VERSION ""

NS_ :

BS_:

BU_:

BO_ 605 DAS_road: 6 XXX
 SG_ DAS_stopLineDist : 16|8@1+ (0.5,0) [0|127.5] "m" XXX
 SG_ DAS_trafficLightColor : 26|3@0+ (1,0) [0|7] "" XXX

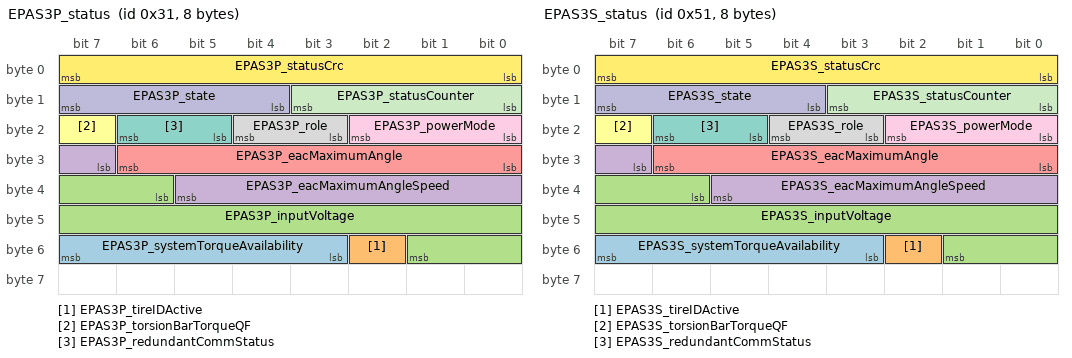
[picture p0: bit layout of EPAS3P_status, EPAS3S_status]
BO_ 49 EPAS3P_status: 8 Vector__XXX
 SG_ EPAS3P_systemTorqueAvailability : 51|5@1+ (5,0) [0|0] "" Vector__XXX
 SG_ EPAS3P_tireIDActive : 50|1@1+ (1,0) [0|0] "" Vector__XXX
 SG_ EPAS3P_inputVoltage : 38|12@1+ (0.0073,0) [0|0] "" Vector__XXX
 SG_ EPAS3P_eacMaximumAngleSpeed : 31|7@1+ (10,0) [0|0] "" Vector__XXX
 SG_ EPAS3P_eacMaximumAngle : 24|7@1+ (10,0) [0|0] "" Vector__XXX
 SG_ EPAS3P_torsionBarTorqueQF : 23|1@1+ (1,0) [0|0] "" Vector__XXX
 SG_ EPAS3P_redundantCommStatus : 21|2@1+ (1,0) [0|0] "" Vector__XXX
 SG_ EPAS3P_role : 19|2@1+ (1,0) [0|0] "" Vector__XXX
 SG_ EPAS3P_powerMode : 16|3@1+ (1,0) [0|0] "" Vector__XXX
 SG_ EPAS3P_state : 12|4@1+ (1,0) [0|0] "" Vector__XXX
 SG_ EPAS3P_statusCounter : 8|4@1+ (1,0) [0|0] "" Vector__XXX
 SG_ EPAS3P_statusCrc : 0|8@1+ (1,0) [0|0] "" Vector__XXX

BO_ 81 EPAS3S_status: 8 Vector__XXX
 SG_ EPAS3S_systemTorqueAvailability : 51|5@1+ (5,0) [0|0] "" Vector__XXX
 SG_ EPAS3S_tireIDActive : 50|1@1+ (1,0) [0|0] "" Vector__XXX
 SG_ EPAS3S_inputVoltage : 38|12@1+ (0.0073,0) [0|0] "" Vector__XXX
 SG_ EPAS3S_eacMaximumAngleSpeed : 31|7@1+ (10,0) [0|0] "" Vector__XXX
 SG_ EPAS3S_eacMaximumAngle : 24|7@1+ (10,0) [0|0] "" Vector__XXX
 SG_ EPAS3S_torsionBarTorqueQF : 23|1@1+ (1,0) [0|0] "" Vector__XXX
 SG_ EPAS3S_redundantCommStatus : 21|2@1+ (1,0) [0|0] "" Vector__XXX
 SG_ EPAS3S_role : 19|2@1+ (1,0) [0|0] "" Vector__XXX
 SG_ EPAS3S_powerMode : 16|3@1+ (1,0) [0|0] "" Vector__XXX
 SG_ EPAS3S_state : 12|4@1+ (1,0) [0|0] "" Vector__XXX
 SG_ EPAS3S_statusCounter : 8|4@1+ (1,0) [0|0] "" Vector__XXX
 SG_ EPAS3S_statusCrc : 0|8@1+ (1,0) [0|0] "" Vector__XXX

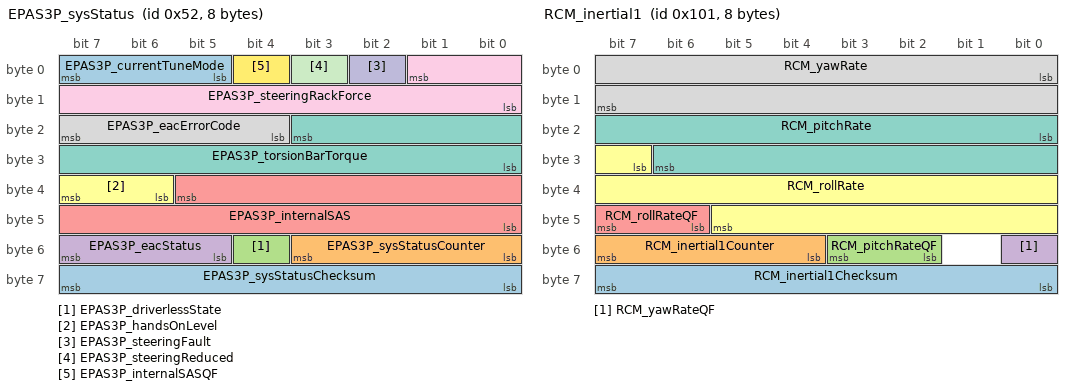
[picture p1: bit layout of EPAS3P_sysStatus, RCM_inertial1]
BO_ 82 EPAS3P_sysStatus: 8 Vector__XXX
 SG_ EPAS3P_sysStatusChecksum : 63|8@0+ (1,0) [0|0] "" Vector__XXX
 SG_ EPAS3P_sysStatusCounter : 51|4@0+ (1,0) [0|0] "" Vector__XXX
 SG_ EPAS3P_driverlessState : 52|1@0+ (1,0) [0|0] "" Vector__XXX
 SG_ EPAS3P_eacStatus : 55|3@0+ (1,0) [0|0] "" Vector__XXX
 SG_ EPAS3P_internalSAS : 37|14@0+ (0.1,-819.2) [0|0] "" Vector__XXX
 SG_ EPAS3P_handsOnLevel : 39|2@0+ (1,0) [0|0] "" Vector__XXX
 SG_ EPAS3P_torsionBarTorque : 19|12@0+ (0.01,-20.5) [0|0] "" Vector__XXX
 SG_ EPAS3P_eacErrorCode : 23|4@0+ (1,0) [0|0] "" Vector__XXX
 SG_ EPAS3P_steeringRackForce : 1|10@0+ (50,-25575) [0|0] "" Vector__XXX
 SG_ EPAS3P_steeringFault : 2|1@0+ (1,0) [0|0] "" Vector__XXX
 SG_ EPAS3P_steeringReduced : 3|1@0+ (1,0) [0|0] "" Vector__XXX
 SG_ EPAS3P_internalSASQF : 4|1@0+ (1,0) [0|0] "" Vector__XXX
 SG_ EPAS3P_currentTuneMode : 7|3@0+ (1,0) [0|0] "" Vector__XXX

BO_ 257 RCM_inertial1: 8 Vector__XXX
 SG_ RCM_inertial1Checksum : 56|8@1+ (1,0) [0|0] "" Vector__XXX
 SG_ RCM_inertial1Counter : 52|4@1+ (1,0) [0|0] "" Vector__XXX
 SG_ RCM_pitchRateQF : 50|2@1+ (1,0) [0|0] "" Vector__XXX
 SG_ RCM_yawRateQF : 48|1@1+ (1,0) [0|0] "" Vector__XXX
 SG_ RCM_rollRateQF : 46|2@1+ (1,0) [0|0] "" Vector__XXX
 SG_ RCM_rollRate : 31|15@1- (0.00025,0) [0|0] "" Vector__XXX
 SG_ RCM_pitchRate : 16|15@1- (0.00025,0) [0|0] "" Vector__XXX
 SG_ RCM_yawRate : 0|16@1- (0.0001,0) [0|0] "" Vector__XXX

BO_ 258 VCLEFT_doorStatus: 8 VEH
 SG_ VCLEFT_frontHandlePulledPersist : 62|1@1+ (1,0) [0|0] ""  X
 SG_ VCLEFT_mirrorDipped : 61|1@1+ (1,0) [0|0] ""  X
 SG_ VCLEFT_mirrorHeatState : 58|3@1+ (1,0) [0|0] ""  X
 SG_ VCLEFT_mirrorRecallState : 55|3@1+ (1,0) [0|0] ""  X
 SG_ VCLEFT_mirrorFoldState : 52|3@1+ (1,0) [0|0] ""  X
 SG_ VCLEFT_mirrorState : 49|3@1+ (1,0) [0|0] ""  X
 SG_ VCLEFT_mirrorTiltYPosition : 41|8@1+ (0.02,0) [0|0] "V"  X
 SG_ VCLEFT_mirrorTiltXPosition : 33|8@1+ (0.02,0) [0|0] "V"  X
 SG_ VCLEFT_rearIntSwitchPressed : 32|1@1+ (1,0) [0|0] ""  X
 SG_ VCLEFT_frontIntSwitchPressed : 31|1@1+ (1,0) [0|0] ""  X
 SG_ VCLEFT_rearHandlePWM : 24|7@1+ (1,0) [0|0] "%"  X
 SG_ VCLEFT_frontHandlePWM : 16|7@1+ (1,0) [0|0] "%"  X
 SG_ VCLEFT_rearRelActuatorSwitch : 13|1@1+ (1,0) [0|0] ""  X
 SG_ VCLEFT_frontRelActuatorSwitch : 12|1@1+ (1,0) [0|0] ""  X
 SG_ VCLEFT_rearHandlePulled : 11|1@1+ (1,0) [0|0] ""  X
 SG_ VCLEFT_frontHandlePulled : 10|1@1+ (1,0) [0|0] ""  X
 SG_ VCLEFT_rearLatchSwitch : 9|1@1+ (1,0) [0|0] ""  X
 SG_ VCLEFT_frontLatchSwitch : 8|1@1+ (1,0) [0|0] ""  X
 SG_ VCLEFT_rearLatchStatus : 4|4@1+ (1,0) [0|0] ""  X
 SG_ VCLEFT_frontLatchStatus : 0|4@1+ (1,0) [0|0] ""  X

BO_ 259 VCRIGHT_doorStatus: 8 VEH
 SG_ VCRIGHT_mirrorDipped : 63|1@1+ (1,0) [0|0] ""  X
 SG_ VCRIGHT_mirrorRecallState : 60|3@1+ (1,0) [0|0] ""  X
 SG_ VCRIGHT_trunkLatchStatus : 56|4@1+ (1,0) [0|0] ""  X
 SG_ VCRIGHT_mirrorFoldState : 52|3@1+ (1,0) [0|0] ""  X
 SG_ VCRIGHT_mirrorState : 49|3@1+ (1,0) [0|0] ""  X
 SG_ VCRIGHT_mirrorTiltYPosition : 41|8@1+ (0.02,0) [0|0] "V"  X
 SG_ VCRIGHT_mirrorTiltXPosition : 33|8@1+ (0.02,0) [0|0] "V"  X
 SG_ VCRIGHT_rearIntSwitchPressed : 32|1@1+ (1,0) [0|0] ""  X
 SG_ VCRIGHT_frontIntSwitchPressed : 31|1@1+ (1,0) [0|0] ""  X
 SG_ VCRIGHT_frontHandlePulledPersist : 30|1@1+ (1,0) [0|0] ""  X
 SG_ VCRIGHT_reservedForBackCompat : 28|2@1+ (1,0) [0|0] ""  X
 SG_ VCRIGHT_rearHandlePWM : 21|7@1+ (1,0) [0|0] "%"  X
 SG_ VCRIGHT_frontHandlePWM : 14|7@1+ (1,0) [0|0] "%"  X
 SG_ VCRIGHT_rearRelActuatorSwitch : 13|1@1+ (1,0) [0|0] ""  X
 SG_ VCRIGHT_frontRelActuatorSwitch : 12|1@1+ (1,0) [0|0] ""  X
 SG_ VCRIGHT_rearHandlePulled : 11|1@1+ (1,0) [0|0] ""  X
 SG_ VCRIGHT_frontHandlePulled : 10|1@1+ (1,0) [0|0] ""  X
 SG_ VCRIGHT_rearLatchSwitch : 9|1@1+ (1,0) [0|0] ""  X
 SG_ VCRIGHT_frontLatchSwitch : 8|1@1+ (1,0) [0|0] ""  X
 SG_ VCRIGHT_rearLatchStatus : 4|4@1+ (1,0) [0|0] ""  X
 SG_ VCRIGHT_frontLatchStatus : 0|4@1+ (1,0) [0|0] ""  X

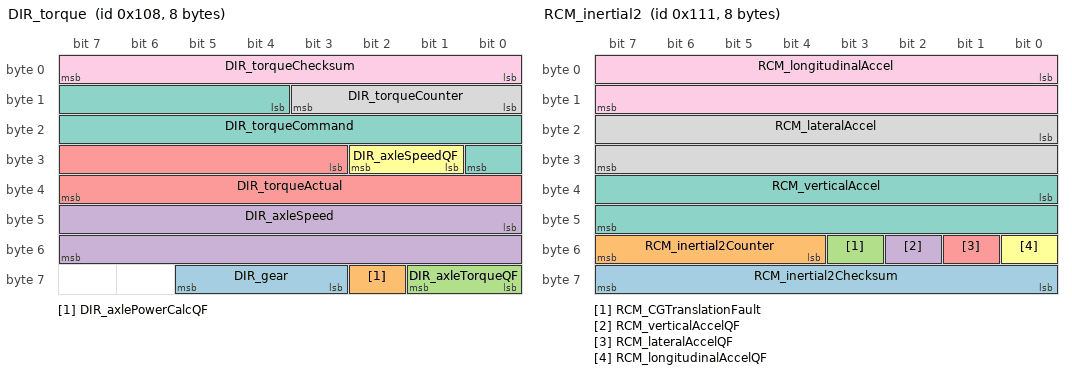
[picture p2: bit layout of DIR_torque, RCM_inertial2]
BO_ 264 DIR_torque: 8 Vector__XXX
 SG_ DIR_gear : 59|3@1+ (1,0) [0|0] "" Vector__XXX
 SG_ DIR_axlePowerCalcQF : 58|1@1+ (1,0) [0|0] "" Vector__XXX
 SG_ DIR_axleTorqueQF : 56|2@1+ (1,0) [0|0] "" Vector__XXX
 SG_ DIR_axleSpeed : 40|16@1- (0.1,0) [0|0] "" Vector__XXX
 SG_ DIR_torqueActual : 27|13@1- (2,0) [0|0] "" Vector__XXX
 SG_ DIR_axleSpeedQF : 25|2@1+ (1,0) [0|0] "" Vector__XXX
 SG_ DIR_torqueCommand : 12|13@1- (2,0) [0|0] "" Vector__XXX
 SG_ DIR_torqueCounter : 8|4@1+ (1,0) [0|0] "" Vector__XXX
 SG_ DIR_torqueChecksum : 0|8@1+ (1,0) [0|0] "" Vector__XXX

BO_ 273 RCM_inertial2: 8 Vector__XXX
 SG_ RCM_inertial2Checksum : 56|8@1+ (1,0) [0|0] "" Vector__XXX
 SG_ RCM_inertial2Counter : 52|4@1+ (1,0) [0|0] "" Vector__XXX
 SG_ RCM_CGTranslationFault : 51|1@1+ (1,0) [0|0] "" Vector__XXX
 SG_ RCM_verticalAccelQF : 50|1@1+ (1,0) [0|0] "" Vector__XXX
 SG_ RCM_lateralAccelQF : 49|1@1+ (1,0) [0|0] "" Vector__XXX
 SG_ RCM_longitudinalAccelQF : 48|1@1+ (1,0) [0|0] "" Vector__XXX
 SG_ RCM_verticalAccel : 32|16@1- (0.00125,0) [0|0] "" Vector__XXX
 SG_ RCM_lateralAccel : 16|16@1- (0.00125,0) [0|0] "" Vector__XXX
 SG_ RCM_longitudinalAccel : 0|16@1- (0.00125,0) [0|0] "" Vector__XXX

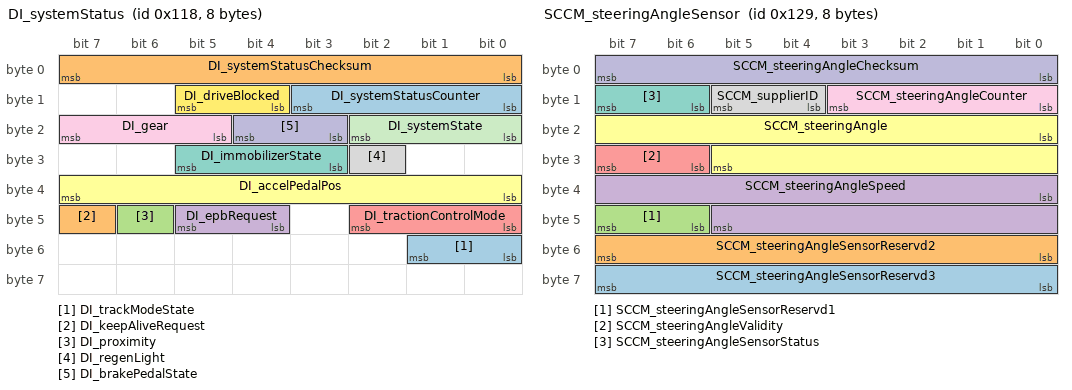
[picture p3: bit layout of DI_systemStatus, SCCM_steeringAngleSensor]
BO_ 280 DI_systemStatus: 8 VEH
 SG_ DI_trackModeState : 48|2@1+ (1,0) [0|0] ""  X
 SG_ DI_keepAliveRequest : 47|1@1+ (1,0) [0|0] ""  X
 SG_ DI_proximity : 46|1@1+ (1,0) [0|0] ""  X
 SG_ DI_epbRequest : 44|2@1+ (1,0) [0|0] ""  X
 SG_ DI_tractionControlMode : 40|3@1+ (1,0) [0|0] ""  X
 SG_ DI_accelPedalPos : 32|8@1+ (0.4,0) [0|0] "%"  X
 SG_ DI_immobilizerState : 27|3@1+ (1,0) [0|0] ""  X
 SG_ DI_regenLight : 26|1@1+ (1,0) [0|0] ""  X
 SG_ DI_gear : 21|3@1+ (1,0) [0|0] ""  X
 SG_ DI_brakePedalState : 19|2@1+ (1,0) [0|0] ""  X
 SG_ DI_systemState : 16|3@1+ (1,0) [0|0] ""  X
 SG_ DI_driveBlocked : 12|2@1+ (1,0) [0|2] ""  X
 SG_ DI_systemStatusCounter : 8|4@1+ (1,0) [0|0] ""  X
 SG_ DI_systemStatusChecksum : 0|8@1+ (1,0) [0|0] ""  X

BO_ 297 SCCM_steeringAngleSensor: 8 VEH
 SG_ SCCM_steeringAngleSensorReservd3 : 56|8@1+ (1,0) [0|0] ""  X
 SG_ SCCM_steeringAngleSensorReservd2 : 48|8@1+ (1,0) [0|0] ""  X
 SG_ SCCM_steeringAngleSensorReservd1 : 46|2@1+ (1,0) [0|0] ""  X
 SG_ SCCM_steeringAngleSpeed : 32|14@1+ (0.5,-4096) [0|0] "deg/s"  X
 SG_ SCCM_steeringAngleValidity : 30|2@1+ (1,0) [0|0] ""  X
 SG_ SCCM_steeringAngle : 16|14@1+ (0.1,-819.2) [0|0] "deg"  X
 SG_ SCCM_steeringAngleSensorStatus : 14|2@1+ (1,0) [0|0] ""  X
 SG_ SCCM_supplierID : 12|2@1+ (1,0) [0|0] ""  X
 SG_ SCCM_steeringAngleCounter : 8|4@1+ (1,0) [0|0] ""  X
 SG_ SCCM_steeringAngleChecksum : 0|8@1+ (1,0) [0|0] ""  X

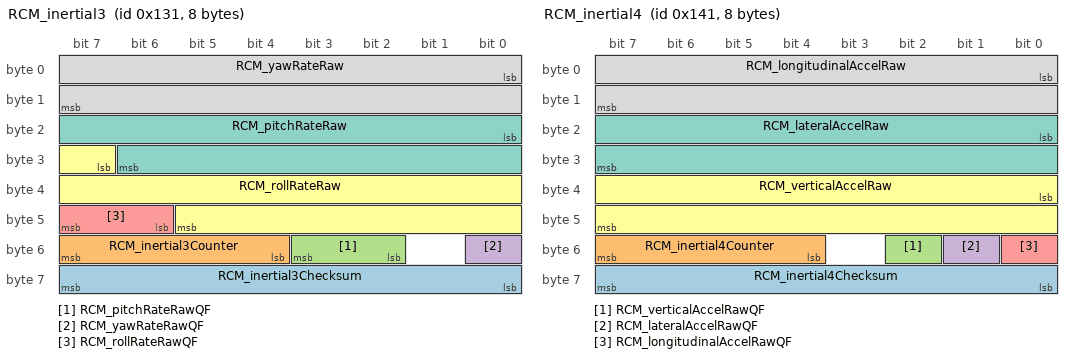
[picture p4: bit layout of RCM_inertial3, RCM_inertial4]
BO_ 305 RCM_inertial3: 8 Vector__XXX
 SG_ RCM_inertial3Checksum : 56|8@1+ (1,0) [0|0] "" Vector__XXX
 SG_ RCM_inertial3Counter : 52|4@1+ (1,0) [0|0] "" Vector__XXX
 SG_ RCM_pitchRateRawQF : 50|2@1+ (1,0) [0|0] "" Vector__XXX
 SG_ RCM_yawRateRawQF : 48|1@1+ (1,0) [0|0] "" Vector__XXX
 SG_ RCM_rollRateRawQF : 46|2@1+ (1,0) [0|0] "" Vector__XXX
 SG_ RCM_rollRateRaw : 31|15@1- (0.00025,0) [0|0] "" Vector__XXX
 SG_ RCM_pitchRateRaw : 16|15@1- (0.00025,0) [0|0] "" Vector__XXX
 SG_ RCM_yawRateRaw : 0|16@1- (0.0001,0) [0|0] "" Vector__XXX

BO_ 321 RCM_inertial4: 8 Vector__XXX
 SG_ RCM_inertial4Checksum : 56|8@1+ (1,0) [0|0] "" Vector__XXX
 SG_ RCM_inertial4Counter : 52|4@1+ (1,0) [0|0] "" Vector__XXX
 SG_ RCM_verticalAccelRawQF : 50|1@1+ (1,0) [0|0] "" Vector__XXX
 SG_ RCM_lateralAccelRawQF : 49|1@1+ (1,0) [0|0] "" Vector__XXX
 SG_ RCM_longitudinalAccelRawQF : 48|1@1+ (1,0) [0|0] "" Vector__XXX
 SG_ RCM_verticalAccelRaw : 32|16@1- (0.00125,0) [0|0] "" Vector__XXX
 SG_ RCM_lateralAccelRaw : 16|16@1- (0.00125,0) [0|0] "" Vector__XXX
 SG_ RCM_longitudinalAccelRaw : 0|16@1- (0.00125,0) [0|0] "" Vector__XXX

BO_ 325 ESP_status: 8 Vector__XXX
 SG_ ESP_brakeTorqueTarget : 51|13@1+ (3,0) [0|0] "" Vector__XXX
 SG_ ESP_ebrStatus : 49|2@1+ (1,0) [0|0] "" Vector__XXX
 SG_ ESP_ebrStandstillSkid : 48|1@1+ (1,0) [0|0] "" Vector__XXX
 SG_ ESP_btcTargetState : 38|2@1+ (1,0) [0|0] "" Vector__XXX
 SG_ ESP_ptcTargetState : 36|2@1+ (1,0) [0|0] "" Vector__XXX
 SG_ ESP_cdpStatus : 34|2@1+ (1,0) [0|0] "" Vector__XXX
 SG_ ESP_aesPrimaryActuatorStatus : 32|2@1+ (1,0) [0|0] "" Vector__XXX
 SG_ ESP_brakeApply : 31|1@1+ (1,0) [0|0] "" Vector__XXX
 SG_ ESP_driverBrakeApply : 29|2@1+ (1,0) [0|0] "" Vector__XXX
 SG_ ESP_brakeDiscWipingActive : 28|1@1+ (1,0) [0|0] "" Vector__XXX
 SG_ ESP_steeringAngleQF : 27|1@1+ (1,0) [0|0] "" Vector__XXX
 SG_ ESP_yawRateQF : 26|1@1+ (1,0) [0|0] "" Vector__XXX
 SG_ ESP_lateralAccelQF : 25|1@1+ (1,0) [0|0] "" Vector__XXX
 SG_ ESP_longitudinalAccelQF : 24|1@1+ (1,0) [0|0] "" Vector__XXX
 SG_ ESP_absBrakeEvent2 : 22|2@1+ (1,0) [0|0] "" Vector__XXX
 SG_ ESP_brakeLamp : 21|1@1+ (1,0) [0|0] "" Vector__XXX
 SG_ ESP_espLampFlash : 20|1@1+ (1,0) [0|0] "" Vector__XXX
 SG_ ESP_hydraulicBoostEnabled : 19|1@1+ (1,0) [0|0] "" Vector__XXX
 SG_ ESP_espFaultLamp : 18|1@1+ (1,0) [0|0] "" Vector__XXX
 SG_ ESP_absFaultLamp : 17|1@1+ (1,0) [0|0] "" Vector__XXX
 SG_ ESP_ebdFaultLamp : 16|1@1+ (1,0) [0|0] "" Vector__XXX
 SG_ ESP_stabilityControlSts2 : 14|2@1+ (1,0) [0|0] "" Vector__XXX
 SG_ ESP_espModeActive : 12|2@1+ (1,0) [0|0] "" Vector__XXX
 SG_ ESP_statusCounter : 8|4@1+ (1,0) [0|0] "" Vector__XXX
 SG_ ESP_statusChecksum : 0|8@1+ (1,0) [0|0] "" Vector__XXX

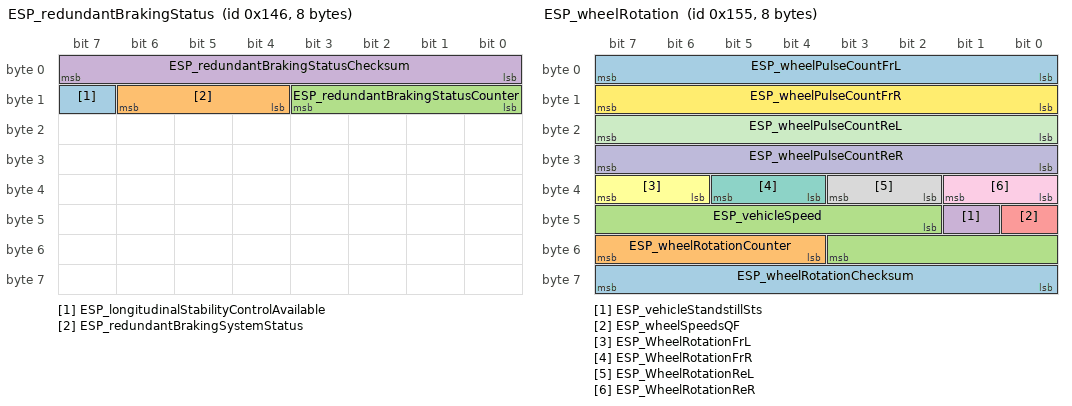
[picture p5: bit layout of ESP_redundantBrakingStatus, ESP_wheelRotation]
BO_ 326 ESP_redundantBrakingStatus: 8 Vector__XXX
 SG_ ESP_longitudinalStabilityControlAvailable : 15|1@1+ (1,0) [0|0] "" Vector__XXX
 SG_ ESP_redundantBrakingSystemStatus : 12|3@1+ (1,0) [0|0] "" Vector__XXX
 SG_ ESP_redundantBrakingStatusCounter : 8|4@1+ (1,0) [0|0] "" Vector__XXX
 SG_ ESP_redundantBrakingStatusChecksum : 0|8@1+ (1,0) [0|0] "" Vector__XXX

BO_ 329 IBST_redundantBrakingStatus: 8 Vector__XXX
 SG_ IBST_brakeTorqueTarget : 15|13@1+ (3,0) [0|0] "" Vector__XXX
 SG_ IBST_redundantBrakingSystemStatus : 12|3@1+ (1,0) [0|0] "" Vector__XXX
 SG_ IBST_redundantBrakingStatusCounter : 8|4@1+ (1,0) [0|0] "" Vector__XXX
 SG_ IBST_redundantBrakingStatusChecksum : 0|8@1+ (1,0) [0|0] "" Vector__XXX

BO_ 341 ESP_wheelRotation: 8 Vector__XXX
 SG_ ESP_wheelRotationChecksum : 56|8@1+ (1,0) [0|0] "" Vector__XXX
 SG_ ESP_wheelRotationCounter : 52|4@1+ (1,0) [0|0] "" Vector__XXX
 SG_ ESP_vehicleSpeed : 42|10@1+ (0.5,0) [0|0] "" Vector__XXX
 SG_ ESP_vehicleStandstillSts : 41|1@1+ (1,0) [0|0] "" Vector__XXX
 SG_ ESP_wheelSpeedsQF : 40|1@1+ (1,0) [0|0] "" Vector__XXX
 SG_ ESP_WheelRotationFrL : 38|2@1+ (1,0) [0|0] "" Vector__XXX
 SG_ ESP_WheelRotationFrR : 36|2@1+ (1,0) [0|0] "" Vector__XXX
 SG_ ESP_WheelRotationReL : 34|2@1+ (1,0) [0|0] "" Vector__XXX
 SG_ ESP_WheelRotationReR : 32|2@1+ (1,0) [0|0] "" Vector__XXX
 SG_ ESP_wheelPulseCountReR : 24|8@1+ (1,0) [0|0] "" Vector__XXX
 SG_ ESP_wheelPulseCountReL : 16|8@1+ (1,0) [0|0] "" Vector__XXX
 SG_ ESP_wheelPulseCountFrR : 8|8@1+ (1,0) [0|0] "" Vector__XXX
 SG_ ESP_wheelPulseCountFrL : 0|8@1+ (1,0) [0|0] "" Vector__XXX

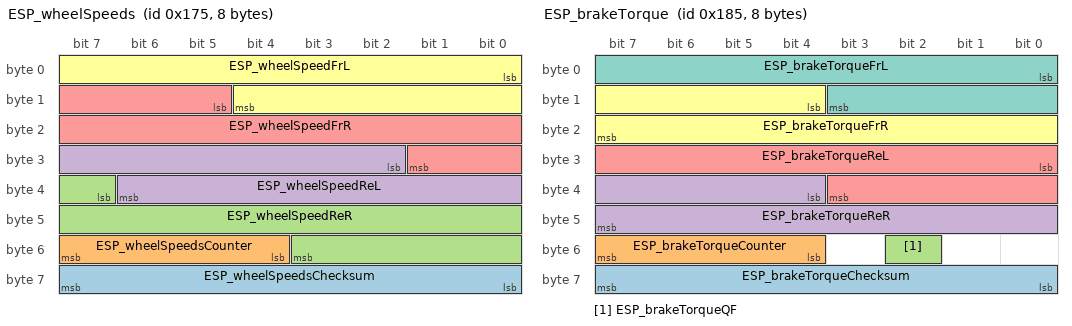
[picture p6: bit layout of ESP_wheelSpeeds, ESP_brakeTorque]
BO_ 373 ESP_wheelSpeeds: 8 Vector__XXX
 SG_ ESP_wheelSpeedsChecksum : 56|8@1+ (1,0) [0|0] "" Vector__XXX
 SG_ ESP_wheelSpeedsCounter : 52|4@1+ (1,0) [0|0] "" Vector__XXX
 SG_ ESP_wheelSpeedReR : 39|13@1+ (0.042,0) [0|0] "" Vector__XXX
 SG_ ESP_wheelSpeedReL : 26|13@1+ (0.042,0) [0|0] "" Vector__XXX
 SG_ ESP_wheelSpeedFrR : 13|13@1+ (0.042,0) [0|0] "" Vector__XXX
 SG_ ESP_wheelSpeedFrL : 0|13@1+ (0.042,0) [0|0] "" Vector__XXX

BO_ 389 ESP_brakeTorque: 8 Vector__XXX
 SG_ ESP_brakeTorqueChecksum : 56|8@1+ (1,0) [0|0] "" Vector__XXX
 SG_ ESP_brakeTorqueCounter : 52|4@1+ (1,0) [0|0] "" Vector__XXX
 SG_ ESP_brakeTorqueQF : 50|1@1+ (1,0) [0|0] "" Vector__XXX
 SG_ ESP_brakeTorqueReR : 36|12@1+ (3,0) [0|0] "" Vector__XXX
 SG_ ESP_brakeTorqueReL : 24|12@1+ (3,0) [0|0] "" Vector__XXX
 SG_ ESP_brakeTorqueFrR : 12|12@1+ (3,0) [0|0] "" Vector__XXX
 SG_ ESP_brakeTorqueFrL : 0|12@1+ (3,0) [0|0] "" Vector__XXX

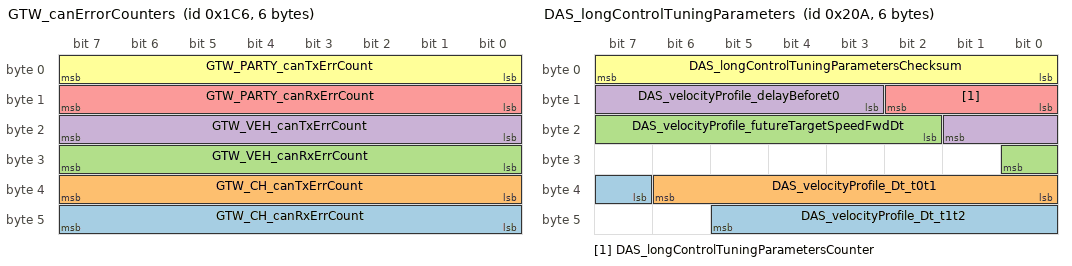
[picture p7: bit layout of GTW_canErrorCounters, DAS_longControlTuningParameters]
BO_ 454 GTW_canErrorCounters: 6 Vector__XXX
 SG_ GTW_CH_canRxErrCount : 40|8@1+ (1,0) [0|0] "" Vector__XXX
 SG_ GTW_CH_canTxErrCount : 32|8@1+ (1,0) [0|0] "" Vector__XXX
 SG_ GTW_VEH_canRxErrCount : 24|8@1+ (1,0) [0|0] "" Vector__XXX
 SG_ GTW_VEH_canTxErrCount : 16|8@1+ (1,0) [0|0] "" Vector__XXX
 SG_ GTW_PARTY_canRxErrCount : 8|8@1+ (1,0) [0|0] "" Vector__XXX
 SG_ GTW_PARTY_canTxErrCount : 0|8@1+ (1,0) [0|0] "" Vector__XXX

BO_ 521 DAS_longControl: 8 Vector__XXX
 SG_ DAS_longControlStack M : 61|3@1+ (1,0) [0|0] "" Vector__XXX
 SG_ DAS_velocityProfile_calcDelay m3 : 58|3@1+ (0.006666666666666667,0) [0|0] "" Vector__XXX
 SG_ DAS_torqueProfiler_jerkMaxPed m2 : 53|8@1+ (0.059,0) [0|0] "" Vector__XXX
 SG_ DAS_velocityProfile_maxAllowedTargetErrorReg m3 : 52|6@1- (0.1,1.1) [0|0] "" Vector__XXX
 SG_ DAS_pedalControl_speedMax m5 : 51|8@1+ (1,0) [0|0] "" Vector__XXX
 SG_ DAS_pedalControl_noGradeAccelMax m5 : 45|6@1+ (0.25,0) [0|0] "" Vector__XXX
 SG_ DAS_torqueProfiler_jerkMinPed m2 : 44|9@1+ (0.03,-15.232) [0|0] "" Vector__XXX
 SG_ DAS_velocityProfile_jerkFwd_t1t2 m3 : 44|8@1- (0.12,0) [0|0] "" Vector__XXX
 SG_ DAS_pedalControl_brakeTorqueCommand m5 : 32|13@1+ (3.5,0) [0|0] "" Vector__XXX
 SG_ DAS_torqueControl_standstillRequest m6 : 32|1@1+ (1,0) [0|0] "" Vector__XXX
 SG_ DAS_torqueProfiler_targetSpeedPed m2 : 32|12@1+ (0.1,0) [0|0] "" Vector__XXX
 SG_ DAS_velocityProfile_futureTargetSpeedFwd m3 : 32|12@1- (0.08,80.08) [0|0] "" Vector__XXX
 SG_ DAS_velocityProfile_jerkFwd_t0t1 m3 : 24|8@1- (0.12,0) [0|0] "" Vector__XXX
 SG_ DAS_torqueProfiler_accelMaxPed m2 : 23|9@1+ (0.04,-15) [0|0] "" Vector__XXX
 SG_ DAS_aebControl_targetAccelDis m4 : 18|11@1- (0.01,-7.5) [0|0] "" Vector__XXX
 SG_ DAS_aebControl_active m4 : 16|2@1+ (1,0) [0|0] "" Vector__XXX
 SG_ DAS_pedalControl_accelPedalPos m5 : 16|12@1+ (0.025,0) [0|0] "" Vector__XXX
 SG_ DAS_torqueControl_sysTorqueCommandFwd m6 : 16|15@1- (2,0) [0|0] "" Vector__XXX
 SG_ DAS_torqueProfiler_accelMinPed m2 : 14|9@1+ (0.04,-15) [0|0] "" Vector__XXX
 SG_ DAS_velocityProfile_accelFwd_t0 m3 : 13|11@1- (0.012,-0.216) [0|0] "" Vector__XXX
 SG_ DAS_gearRequest : 11|2@1+ (1,0) [0|0] "" Vector__XXX
 SG_ DAS_longControlCounter : 8|3@1+ (1,0) [0|0] "" Vector__XXX
 SG_ DAS_longControlChecksum : 0|8@1+ (1,0) [0|0] "" Vector__XXX

BO_ 522 DAS_longControlTuningParameters: 6 Vector__XXX
 SG_ DAS_velocityProfile_Dt_t1t2 : 39|7@1+ (0.01,0) [0|0] "" Vector__XXX
 SG_ DAS_velocityProfile_Dt_t0t1 : 32|7@1+ (0.01,0) [0|0] "" Vector__XXX
 SG_ DAS_velocityProfile_futureTargetSpeedFwdDt : 18|7@1+ (0.01,0) [0|0] "" Vector__XXX
 SG_ DAS_velocityProfile_delayBeforet0 : 11|7@1+ (0.01,0) [0|0] "" Vector__XXX
 SG_ DAS_longControlTuningParametersCounter : 8|3@1+ (1,0) [0|0] "" Vector__XXX
 SG_ DAS_longControlTuningParametersChecksum : 0|8@1+ (1,0) [0|0] "" Vector__XXX

BO_ 529 RCM_status: 6 Vector__XXX
 SG_ RCM_pedProEDR2State : 46|2@1+ (1,0) [0|0] "" Vector__XXX
 SG_ RCM_pedProEDR1State : 44|2@1+ (1,0) [0|0] "" Vector__XXX
 SG_ RCM_occupantClassificationSource : 43|1@1+ (1,0) [0|0] "" Vector__XXX
 SG_ RCM_driverOrientationInitStatus : 40|3@1+ (1,0) [0|0] "" Vector__XXX
 SG_ RCM_edr3State : 38|2@1+ (1,0) [0|0] "" Vector__XXX
 SG_ RCM_imuOffsetLearnState : 36|2@1+ (1,0) [0|0] "" Vector__XXX
 SG_ RCM_keepPowerReason : 32|4@1+ (1,0) [0|0] "" Vector__XXX
 SG_ RCM_edr2State : 30|2@1+ (1,0) [0|0] "" Vector__XXX
 SG_ RCM_edr1State : 28|2@1+ (1,0) [0|0] "" Vector__XXX
 SG_ RCM_seatTrackPositionPass : 26|2@1+ (1,0) [0|0] "" Vector__XXX
 SG_ RCM_seatTrackPositionDrvr : 24|2@1+ (1,0) [0|0] "" Vector__XXX
 SG_ RCM_vinLearnFlag : 22|2@1+ (1,0) [0|0] "" Vector__XXX
 SG_ RCM_alrSwitchStatus : 20|2@1+ (1,0) [0|0] "" Vector__XXX
 SG_ RCM_airbagCutoffStatus : 18|2@1+ (1,0) [0|0] "" Vector__XXX
 SG_ RCM_passAirbagIndicatorRequest : 16|2@1+ (1,0) [0|0] "" Vector__XXX
 SG_ RCM_warningIndicatorState : 14|2@1+ (1,0) [0|0] "" Vector__XXX
 SG_ RCM_armStatus : 12|2@1+ (1,0) [0|0] "" Vector__XXX
 SG_ RCM_statusCounter : 8|4@1+ (1,0) [0|0] "" Vector__XXX
 SG_ RCM_statusChecksum : 0|8@1+ (1,0) [0|0] "" Vector__XXX

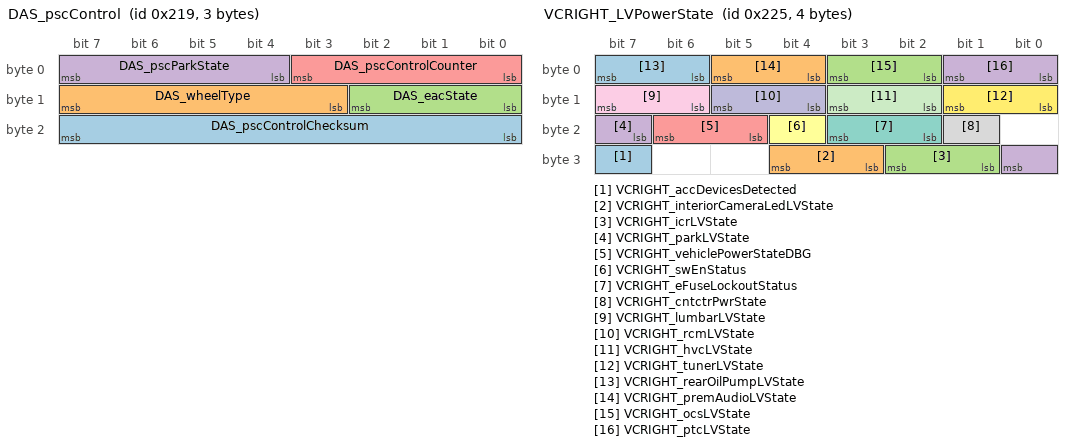
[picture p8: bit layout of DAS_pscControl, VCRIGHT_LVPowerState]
BO_ 537 DAS_pscControl: 3 Vector__XXX
 SG_ DAS_pscControlChecksum : 16|8@1+ (1,0) [0|0] "" Vector__XXX
 SG_ DAS_wheelType : 11|5@1+ (1,0) [0|0] "" Vector__XXX
 SG_ DAS_eacState : 8|3@1+ (1,0) [0|0] "" Vector__XXX
 SG_ DAS_pscParkState : 4|4@1+ (1,0) [0|0] "" Vector__XXX
 SG_ DAS_pscControlCounter : 0|4@1+ (1,0) [0|0] "" Vector__XXX

BO_ 545 VCFRONT_LVPowerState: 8 Vector__XXX
 SG_ VCFRONT_LVPowerStateChecksum : 56|8@1+ (1,0) [0|0] "" Vector__XXX
 SG_ VCFRONT_LVPowerStateCounter : 52|4@1+ (1,0) [0|0] "" Vector__XXX
 SG_ VCFRONT_LVShuttingDown : 51|1@1+ (1,0) [0|0] "" Vector__XXX
 SG_ VCFRONT_inAccessoryPlus : 50|1@1+ (1,0) [0|0] "" Vector__XXX
 SG_ VCFRONT_uiHiCurrentLVState m0 : 48|2@1+ (1,0) [0|0] "" Vector__XXX
 SG_ VCFRONT_vcrightHiCurrentLVState m0 : 46|2@1+ (1,0) [0|0] "" Vector__XXX
 SG_ VC_noAccDeviceDetectedWhileIdle m1 : 46|1@1+ (1,0) [0|0] "" Vector__XXX
 SG_ VCFRONT_vcleftHiCurrentLVState m0 : 44|2@1+ (1,0) [0|0] "" Vector__XXX
 SG_ VCFRONT_ocsLVRequest m0 : 42|2@1+ (1,0) [0|0] "" Vector__XXX
 SG_ VC_persistAccPortPowerState m1 : 41|3@1+ (1,0) [0|0] "" Vector__XXX
 SG_ VCFRONT_oilPumpRearLVRequest m0 : 40|2@1+ (1,0) [0|0] "" Vector__XXX
 SG_ VC_accPortPowerRequest m1 : 40|1@1+ (1,0) [0|0] "" Vector__XXX
 SG_ VC_persistAccPowerRequestOverridden m1 : 39|1@1+ (1,0) [0|0] "" Vector__XXX
 SG_ VCFRONT_oilPumpFrontLVState m0 : 38|2@1+ (1,0) [0|0] "" Vector__XXX
 SG_ VCFRONT_difLVState m0 : 36|2@1+ (1,0) [0|0] "" Vector__XXX
 SG_ VCFRONT_dirLVRequest m0 : 34|2@1+ (1,0) [0|0] "" Vector__XXX
 SG_ VC_autonomyBehavior m1 : 34|2@1+ (1,0) [0|0] "" Vector__XXX
 SG_ VCFRONT_das2HighCurrentLVState m0 : 32|2@1+ (1,0) [0|0] "" Vector__XXX
 SG_ VC_hvStateRequest m1 : 31|3@1+ (1,0) [0|0] "" Vector__XXX
 SG_ VCFRONT_das1HighCurrentLVState m0 : 30|2@1+ (1,0) [0|0] "" Vector__XXX
 SG_ VC_dcdcSupportRequest m1 : 30|1@1+ (1,0) [0|0] "" Vector__XXX
 SG_ VCFRONT_MCUGraphicsLVState m1 : 28|2@1+ (1,0) [0|0] "" Vector__XXX
 SG_ VCFRONT_amplifierLVRequest m0 : 28|2@1+ (1,0) [0|0] "" Vector__XXX
 SG_ VCFRONT_espValveLVState m1 : 26|2@1+ (1,0) [0|0] "" Vector__XXX
 SG_ VCFRONT_tunerLVRequest m0 : 26|2@1+ (1,0) [0|0] "" Vector__XXX
 SG_ VCFRONT_MCUAudioLVState m1 : 24|2@1+ (1,0) [0|0] "" Vector__XXX
 SG_ VCFRONT_iBoosterLVState m0 : 24|2@1+ (1,0) [0|0] "" Vector__XXX
 SG_ VCFRONT_hcmrLVState m1 : 22|2@1+ (1,0) [0|0] "" Vector__XXX
 SG_ VCFRONT_rcmLVRequest m0 : 22|2@1+ (1,0) [0|0] "" Vector__XXX
 SG_ VCFRONT_hcmlLVState m1 : 20|2@1+ (1,0) [0|0] "" Vector__XXX
 SG_ VCFRONT_tpmsLVRequest m0 : 20|2@1+ (1,0) [0|0] "" Vector__XXX
 SG_ VCFRONT_CMPDLVState m1 : 18|2@1+ (1,0) [0|0] "" Vector__XXX
 SG_ VCFRONT_sccmLVRequest m0 : 18|2@1+ (1,0) [0|0] "" Vector__XXX
 SG_ VCFRONT_pcsLVState m1 : 16|2@1+ (1,0) [0|0] "" Vector__XXX
 SG_ VCFRONT_ptcLVRequest m0 : 16|2@1+ (1,0) [0|0] "" Vector__XXX
 SG_ VCFRONT_hvacCompLVState m0 : 14|2@1+ (1,0) [0|0] "" Vector__XXX
 SG_ VCFRONT_tasLVState m1 : 14|2@1+ (1,0) [0|0] "" Vector__XXX
 SG_ VCFRONT_hvcLVRequest m1 : 12|2@1+ (1,0) [0|0] "" Vector__XXX
 SG_ VCFRONT_radcLVState m0 : 12|2@1+ (1,0) [0|0] "" Vector__XXX
 SG_ VCFRONT_epasLVState m1 : 10|2@1+ (1,0) [0|0] "" Vector__XXX
 SG_ VCFRONT_espLVState m0 : 10|2@1+ (1,0) [0|0] "" Vector__XXX
 SG_ VCFRONT_cpLVRequest m1 : 8|2@1+ (1,0) [0|0] "" Vector__XXX
 SG_ VCFRONT_parkLVState m0 : 8|2@1+ (1,0) [0|0] "" Vector__XXX
 SG_ VCFRONT_vehiclePowerState : 5|2@1+ (1,0) [0|0] "" Vector__XXX
 SG_ VCFRONT_LVPowerStateIndex M : 0|5@1+ (1,0) [0|0] "" Vector__XXX

BO_ 549 VCRIGHT_LVPowerState: 4 Vector__XXX
 SG_ VCRIGHT_accDevicesDetected : 31|1@1+ (1,0) [0|0] "" Vector__XXX
 SG_ VCRIGHT_interiorCameraLedLVState : 27|2@1+ (1,0) [0|0] "" Vector__XXX
 SG_ VCRIGHT_icrLVState : 25|2@1+ (1,0) [0|0] "" Vector__XXX
 SG_ VCRIGHT_parkLVState : 23|2@1+ (1,0) [0|0] "" Vector__XXX
 SG_ VCRIGHT_vehiclePowerStateDBG : 21|2@1+ (1,0) [0|0] "" Vector__XXX
 SG_ VCRIGHT_swEnStatus : 20|1@1+ (1,0) [0|0] "" Vector__XXX
 SG_ VCRIGHT_eFuseLockoutStatus : 18|2@1+ (1,0) [0|0] "" Vector__XXX
 SG_ VCRIGHT_cntctrPwrState : 17|1@1+ (1,0) [0|0] "" Vector__XXX
 SG_ VCRIGHT_lumbarLVState : 14|2@1+ (1,0) [0|0] "" Vector__XXX
 SG_ VCRIGHT_rcmLVState : 12|2@1+ (1,0) [0|0] "" Vector__XXX
 SG_ VCRIGHT_hvcLVState : 10|2@1+ (1,0) [0|0] "" Vector__XXX
 SG_ VCRIGHT_tunerLVState : 8|2@1+ (1,0) [0|0] "" Vector__XXX
 SG_ VCRIGHT_rearOilPumpLVState : 6|2@1+ (1,0) [0|0] "" Vector__XXX
 SG_ VCRIGHT_premAudioLVState : 4|2@1+ (1,0) [0|0] "" Vector__XXX
 SG_ VCRIGHT_ocsLVState : 2|2@1+ (1,0) [0|0] "" Vector__XXX
 SG_ VCRIGHT_ptcLVState : 0|2@1+ (1,0) [0|0] "" Vector__XXX

BO_ 551 OCS1P_debugCushionMutCNT: 8 Vector__XXX
 SG_ OCS1P_cushionMutCNTFreqMed : 48|16@1+ (10,0) [0|0] "" Vector__XXX
 SG_ OCS1P_cushionMutCNTDuty : 32|16@1+ (1,0) [0|0] "" Vector__XXX
 SG_ OCS1P_cushionMutCNTFreq : 0|32@1+ (1,0) [0|0] "" Vector__XXX

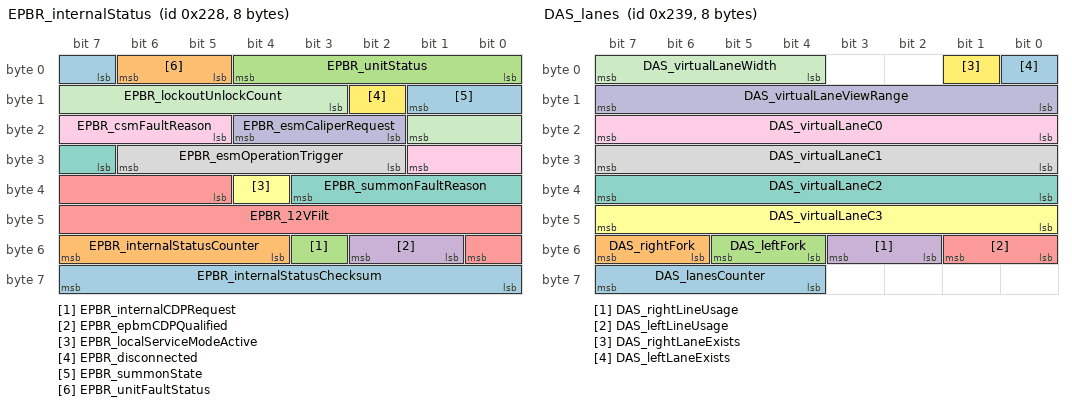
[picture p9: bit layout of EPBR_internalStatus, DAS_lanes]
BO_ 552 EPBR_internalStatus: 8 VEH
 SG_ EPBR_internalStatusChecksum : 56|8@1+ (1,0) [0|0] ""  X
 SG_ EPBR_internalStatusCounter : 52|4@1+ (1,0) [0|0] ""  X
 SG_ EPBR_internalCDPRequest : 51|1@1+ (1,0) [0|0] ""  X
 SG_ EPBR_epbmCDPQualified : 49|2@1+ (1,0) [0|0] ""  X
 SG_ EPBR_12VFilt : 37|12@1+ (0.00544368,0) [0|0] "V"  X
 SG_ EPBR_localServiceModeActive : 36|1@1+ (1,0) [0|0] ""  X
 SG_ EPBR_summonFaultReason : 31|5@1+ (1,0) [0|0] ""  X
 SG_ EPBR_esmOperationTrigger : 26|5@1+ (1,0) [0|0] ""  X
 SG_ EPBR_csmFaultReason : 21|5@1+ (1,0) [0|0] ""  X
 SG_ EPBR_esmCaliperRequest : 18|3@1+ (1,0) [0|0] ""  X
 SG_ EPBR_lockoutUnlockCount : 11|7@1+ (1,0) [0|0] ""  X
 SG_ EPBR_disconnected : 10|1@1+ (1,0) [0|0] ""  X
 SG_ EPBR_summonState : 7|3@1+ (1,0) [0|0] ""  X
 SG_ EPBR_unitFaultStatus : 5|2@1+ (1,0) [0|0] ""  X
 SG_ EPBR_unitStatus : 0|5@1+ (1,0) [0|0] ""  X

BO_ 553 OCS1P_debugCushionSelfCNT: 8 Vector__XXX
 SG_ OCS1P_cushionSelfCNTFreqMed : 48|16@1+ (10,0) [0|0] "" Vector__XXX
 SG_ OCS1P_cushionSelfCNTDuty : 32|16@1+ (1,0) [0|0] "" Vector__XXX
 SG_ OCS1P_cushionSelfCNTFreq : 0|32@1+ (1,0) [0|0] "" Vector__XXX

BO_ 561 OCS1P_debugSeatbackSelfCNT: 8 Vector__XXX
 SG_ OCS1P_seatbackSelfCNTFreqMed : 48|16@1+ (10,0) [0|0] "" Vector__XXX
 SG_ OCS1P_seatbackSelfCNTDuty : 32|16@1+ (1,0) [0|0] "" Vector__XXX
 SG_ OCS1P_seatbackSelfCNTFreq : 0|32@1+ (1,0) [0|0] "" Vector__XXX

BO_ 564 OCS1P_debugCalibration: 8 Vector__XXX
 SG_ OCS1P_cushionMutCalibLargeFreq m1 : 40|16@1+ (1,0) [0|0] "" Vector__XXX
 SG_ OCS1P_cushionMutCalibSmallFreq m1 : 24|16@1+ (1,0) [0|0] "" Vector__XXX
 SG_ OCS1P_humidityCalib m2 : 24|16@1+ (0.1,0) [0|0] "" Vector__XXX
 SG_ OCS1P_seatbackSelfCalibEmptyFreq m0 : 24|16@1+ (1,0) [0|0] "" Vector__XXX
 SG_ OCS1P_seatbackSelfOffsetHCB m3 : 24|16@1- (0.005,0) [0|0] "" Vector__XXX
 SG_ OCS1P_cushionMutCalibEmptyFreq m1 : 8|16@1+ (1,0) [0|0] "" Vector__XXX
 SG_ OCS1P_cushionSelfCalibEmptyFreq m0 : 8|16@1+ (1,0) [0|0] "" Vector__XXX
 SG_ OCS1P_cushionSelfOffsetHCB m3 : 8|16@1- (0.005,0) [0|0] "" Vector__XXX
 SG_ OCS1P_temperatureCalib m2 : 8|16@1- (0.1,0) [0|0] "" Vector__XXX
 SG_ OCS1P_debugCalibrationIndex M : 0|2@1+ (1,0) [0|0] "" Vector__XXX

BO_ 565 OCS1P_debugTHS: 4 Vector__XXX
 SG_ OCS1P_humidity : 16|16@1+ (0.1,0) [0|0] "" Vector__XXX
 SG_ OCS1P_temperature : 0|16@1- (0.1,0) [0|0] "" Vector__XXX

BO_ 568 UI_driverAssistMapData: 8 Vector__XXX
 SG_ UI_mapDataChecksum : 56|8@1+ (1,0) [0|0] "" Vector__XXX
 SG_ UI_mapDataCounter : 52|4@1+ (1,0) [0|0] "" Vector__XXX
 SG_ UI_scaEnabled : 51|1@1+ (1,0) [0|0] "" Vector__XXX
 SG_ UI_pmmEnabled : 50|1@1+ (1,0) [0|0] "" Vector__XXX
 SG_ UI_autosteerRestricted : 49|1@1+ (1,0) [0|0] "" Vector__XXX
 SG_ UI_acceptBottsDots : 48|1@1+ (1,0) [0|0] "" Vector__XXX
 SG_ UI_rejectHandsOn : 47|1@1+ (1,0) [0|0] "" Vector__XXX
 SG_ UI_rejectAutosteer : 46|1@1+ (1,0) [0|0] "" Vector__XXX
 SG_ UI_rejectRightFreeSpace : 45|1@1+ (1,0) [0|0] "" Vector__XXX
 SG_ UI_rejectLeftFreeSpace : 44|1@1+ (1,0) [0|0] "" Vector__XXX
 SG_ UI_rejectNav : 43|1@1+ (1,0) [0|0] "" Vector__XXX
 SG_ UI_rejectHPP : 42|1@1+ (1,0) [0|0] "" Vector__XXX
 SG_ UI_rejectRightLane : 41|1@1+ (1,0) [0|0] "" Vector__XXX
 SG_ UI_rejectLeftLane : 40|1@1+ (1,0) [0|0] "" Vector__XXX
 SG_ UI_nextBranchRightOffRamp : 39|1@1+ (1,0) [0|0] "" Vector__XXX
 SG_ UI_nextBranchLeftOffRamp : 38|1@1+ (1,0) [0|0] "" Vector__XXX
 SG_ UI_controlledAccess : 37|1@1+ (1,0) [0|0] "" Vector__XXX
 SG_ UI_nextBranchDist : 32|5@1+ (10,0) [0|0] "" Vector__XXX
 SG_ UI_perpendicularAutoparkEnabled : 31|1@1+ (1,0) [0|0] "" Vector__XXX
 SG_ UI_parallelAutoparkEnabled : 30|1@1+ (1,0) [0|0] "" Vector__XXX
 SG_ UI_navRouteActive : 29|1@1+ (1,0) [0|0] "" Vector__XXX
 SG_ UI_gpsRoadMatch : 28|1@1+ (1,0) [0|0] "" Vector__XXX
 SG_ UI_streetCount : 26|2@1+ (1,0) [0|0] "" Vector__XXX
 SG_ UI_countryCode : 16|10@1+ (1,0) [0|0] "" Vector__XXX
 SG_ UI_mapSpeedLimitType : 13|3@1+ (1,0) [0|0] "" Vector__XXX
 SG_ UI_mapSpeedLimit : 8|5@1+ (1,0) [0|0] "" Vector__XXX
 SG_ UI_mapSpeedUnits : 7|1@1+ (1,0) [0|0] "" Vector__XXX
 SG_ UI_inSuperchargerGeofence : 6|1@1+ (1,0) [0|0] "" Vector__XXX
 SG_ UI_roadClass : 3|3@1+ (1,0) [0|0] "" Vector__XXX
 SG_ UI_mapSpeedLimitDependency : 0|3@1+ (1,0) [0|0] "" Vector__XXX

BO_ 569 DAS_lanes: 8 Vector__XXX
 SG_ DAS_lanesCounter : 60|4@1+ (1,0) [0|0] "" Vector__XXX
 SG_ DAS_rightFork : 54|2@1+ (1,0) [0|0] "" Vector__XXX
 SG_ DAS_leftFork : 52|2@1+ (1,0) [0|0] "" Vector__XXX
 SG_ DAS_rightLineUsage : 50|2@1+ (1,0) [0|0] "" Vector__XXX
 SG_ DAS_leftLineUsage : 48|2@1+ (1,0) [0|0] "" Vector__XXX
 SG_ DAS_virtualLaneC3 : 40|8@1+ (2.4e-07,-3e-05) [0|0] "" Vector__XXX
 SG_ DAS_virtualLaneC2 : 32|8@1+ (2e-05,-0.0025) [0|0] "" Vector__XXX
 SG_ DAS_virtualLaneC1 : 24|8@1+ (0.0016,-0.2) [0|0] "" Vector__XXX
 SG_ DAS_virtualLaneC0 : 16|8@1+ (0.035,-3.5) [0|0] "" Vector__XXX
 SG_ DAS_virtualLaneViewRange : 8|8@1+ (1,0) [0|0] "" Vector__XXX
 SG_ DAS_virtualLaneWidth : 4|4@1+ (0.3125,2) [0|0] "" Vector__XXX
 SG_ DAS_rightLaneExists : 1|1@1+ (1,0) [0|0] "" Vector__XXX
 SG_ DAS_leftLaneExists : 0|1@1+ (1,0) [0|0] "" Vector__XXX

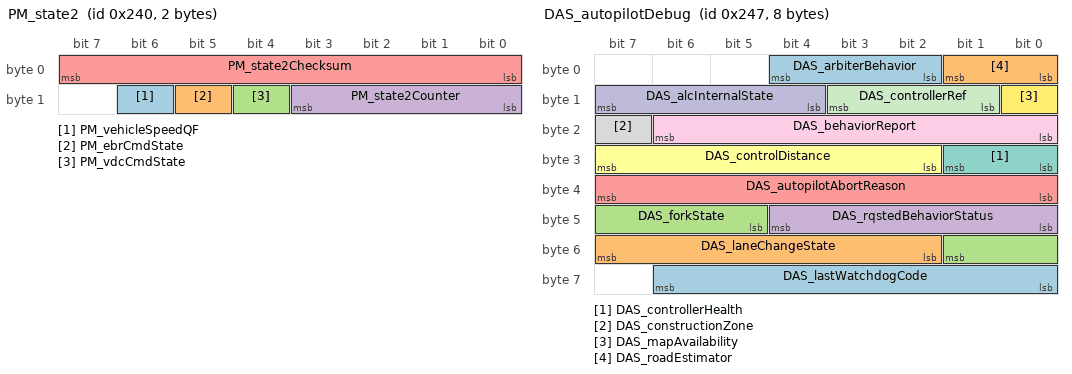
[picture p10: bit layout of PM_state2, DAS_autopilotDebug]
BO_ 576 PM_state2: 2 Vector__XXX
 SG_ PM_vehicleSpeedQF : 14|1@1+ (1,0) [0|0] "" Vector__XXX
 SG_ PM_ebrCmdState : 13|1@1+ (1,0) [0|0] "" Vector__XXX
 SG_ PM_vdcCmdState : 12|1@1+ (1,0) [0|0] "" Vector__XXX
 SG_ PM_state2Counter : 8|4@1+ (1,0) [0|0] "" Vector__XXX
 SG_ PM_state2Checksum : 0|8@1+ (1,0) [0|0] "" Vector__XXX

BO_ 583 DAS_autopilotDebug: 8 Vector__XXX
 SG_ DAS_lastWatchdogCode : 56|7@1+ (1,0) [0|0] "" Vector__XXX
 SG_ DAS_laneChangeState : 50|6@1+ (1,0) [0|0] "" Vector__XXX
 SG_ DAS_forkState : 45|5@1+ (1,0) [0|0] "" Vector__XXX
 SG_ DAS_rqstedBehaviorStatus : 40|5@1+ (1,0) [0|0] "" Vector__XXX
 SG_ DAS_autopilotAbortReason : 32|8@1+ (1,0) [0|0] "" Vector__XXX
 SG_ DAS_controlDistance : 26|6@1+ (2,0) [0|0] "" Vector__XXX
 SG_ DAS_controllerHealth : 24|2@1+ (1,0) [0|0] "" Vector__XXX
 SG_ DAS_constructionZone : 23|1@1+ (1,0) [0|0] "" Vector__XXX
 SG_ DAS_behaviorReport : 16|7@1+ (1,0) [0|0] "" Vector__XXX
 SG_ DAS_alcInternalState : 12|4@1+ (1,0) [0|0] "" Vector__XXX
 SG_ DAS_controllerRef : 9|3@1+ (1,0) [0|0] "" Vector__XXX
 SG_ DAS_mapAvailability : 8|1@1+ (1,0) [0|0] "" Vector__XXX
 SG_ DAS_arbiterBehavior : 2|3@1+ (1,0) [0|0] "" Vector__XXX
 SG_ DAS_roadEstimator : 0|2@1+ (1,0) [0|0] "" Vector__XXX

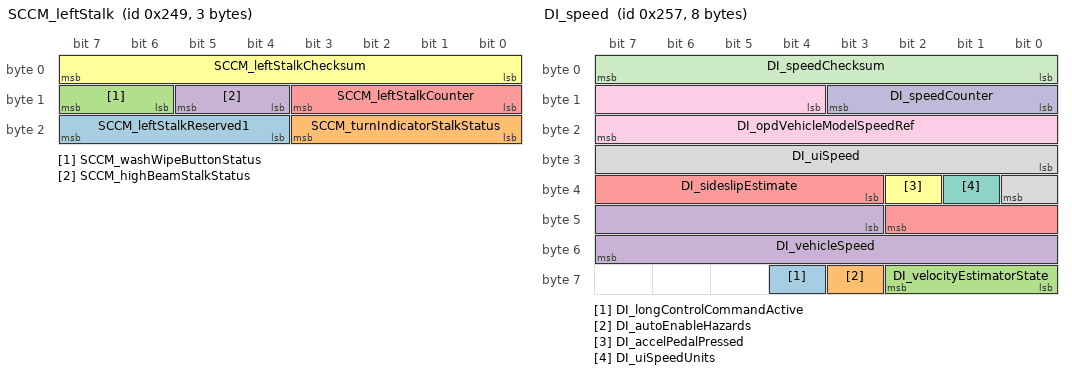
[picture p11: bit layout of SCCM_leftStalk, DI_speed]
BO_ 585 SCCM_leftStalk: 3 VEH
 SG_ SCCM_leftStalkReserved1 : 20|4@1+ (1,0) [0|0] ""  X
 SG_ SCCM_turnIndicatorStalkStatus : 16|4@1+ (1,0) [0|0] ""  X
 SG_ SCCM_washWipeButtonStatus : 14|2@1+ (1,0) [0|0] ""  X
 SG_ SCCM_highBeamStalkStatus : 12|2@1+ (1,0) [0|0] ""  X
 SG_ SCCM_leftStalkCounter : 8|4@1+ (1,0) [0|0] ""  X
 SG_ SCCM_leftStalkChecksum : 0|8@1+ (1,0) [0|0] ""  X

BO_ 586 DAS_visualDebug: 8 Vector__XXX
 SG_ DAS_rearLeftVehDetectedTrip : 63|1@1+ (1,0) [0|0] "" Vector__XXX
 SG_ DAS_rearRightVehDetectedTrip : 62|1@1+ (1,0) [0|0] "" Vector__XXX
 SG_ DAS_rearLeftVehDetectedCurrent : 61|1@1+ (1,0) [0|0] "" Vector__XXX
 SG_ DAS_rearVehDetectedThisCycle : 60|1@1+ (1,0) [0|0] "" Vector__XXX
 SG_ DAS_ulcType : 58|2@1+ (1,0) [0|0] "" Vector__XXX
 SG_ DAS_behaviorType : 56|2@1+ (1,0) [0|0] "" Vector__XXX
 SG_ DAS_isaSystemState : 54|2@1+ (1,0) [0|0] "" Vector__XXX
 SG_ DAS_trafficAwareSetSpeedInUse : 53|1@1+ (1,0) [0|0] "" Vector__XXX
 SG_ DAS_ulcInProgress : 52|1@1+ (1,0) [0|0] "" Vector__XXX
 SG_ DAS_accSmartSpeedState : 49|3@1+ (1,0) [0|0] "" Vector__XXX
 SG_ DAS_accSmartSpeedActive : 48|1@1+ (1,0) [0|0] "" Vector__XXX
 SG_ DAS_navDistance : 40|8@1+ (100,0) [0|0] "" Vector__XXX
 SG_ DAS_navAvailable : 39|1@1+ (1,0) [0|0] "" Vector__XXX
 SG_ DAS_devAppInterfaceEnabled : 38|1@1+ (1,0) [0|0] "" Vector__XXX
 SG_ DAS_lastAutosteerAbortReason : 32|6@1+ (1,0) [0|0] "" Vector__XXX
 SG_ DAS_plannerState : 28|4@1+ (1,0) [0|0] "" Vector__XXX
 SG_ DAS_lastLinePreferenceReason : 24|4@1+ (1,0) [0|0] "" Vector__XXX
 SG_ DAS_autosteerHealthState : 21|3@1+ (1,0) [0|0] "" Vector__XXX
 SG_ DAS_autosteerHealthAnomalyLevel : 18|3@1+ (1,0) [0|0] "" Vector__XXX
 SG_ DAS_roadSurfaceType : 16|2@1+ (1,0) [0|0] "" Vector__XXX
 SG_ DAS_offsetSide : 14|2@1+ (1,0) [0|0] "" Vector__XXX
 SG_ DAS_autosteerBottsDotsUsage : 12|2@1+ (1,0) [0|0] "" Vector__XXX
 SG_ DAS_autosteerModelUsage : 10|2@1+ (1,0) [0|0] "" Vector__XXX
 SG_ DAS_autosteerNavigationUsage : 8|2@1+ (1,0) [0|0] "" Vector__XXX
 SG_ DAS_autosteerHPPUsage : 6|2@1+ (1,0) [0|0] "" Vector__XXX
 SG_ DAS_autosteerVehiclesUsage : 4|2@1+ (1,0) [0|0] "" Vector__XXX

BO_ 599 DI_speed: 8 VEH
 SG_ DI_longControlCommandActive : 60|1@1+ (1,0) [0|1] ""  X
 SG_ DI_autoEnableHazards : 59|1@1+ (1,0) [0|1] ""  X
 SG_ DI_velocityEstimatorState : 56|3@1+ (1,0) [0|7] ""  X
 SG_ DI_vehicleSpeed : 43|13@1+ (0.08,-40) [-40|615.28] "kph"  X
 SG_ DI_sideslipEstimate : 35|8@1- (0.0025,0) [-0.32|0.3175] "rad"  X
 SG_ DI_accelPedalPressed : 34|1@1+ (1,0) [0|1] ""  X
 SG_ DI_uiSpeedUnits : 33|1@1+ (1,0) [0|1] ""  X
 SG_ DI_uiSpeed : 24|9@1+ (1,0) [0|510] ""  X
 SG_ DI_opdVehicleModelSpeedRef : 12|12@1+ (0.08,-40) [-40|285] "kph"  X
 SG_ DI_speedCounter : 8|4@1+ (1,0) [0|15] ""  X
 SG_ DI_speedChecksum : 0|8@1+ (1,0) [0|255] ""  X

BO_ 601 APP_status: 8 Vector__XXX
 SG_ APP_statusChecksum : 56|8@1+ (1,0) [0|0] "" Vector__XXX
 SG_ APP_statusCounter : 52|4@1+ (1,0) [0|0] "" Vector__XXX
 SG_ APP_suspendResumeAvailable : 51|1@1+ (1,0) [0|0] "" Vector__XXX
 SG_ APP_uiEthFailoverDisabled : 50|1@1+ (1,0) [0|0] "" Vector__XXX
 SG_ APP_autonomySystemHealth : 49|1@1+ (1,0) [0|0] "" Vector__XXX
 SG_ APP_autoparkVersionIdentifier : 47|2@1+ (1,0) [0|0] "" Vector__XXX
 SG_ APP_sentryState : 44|3@1+ (1,0) [0|0] "" Vector__XXX
 SG_ APP_summonVersionIdentifier : 42|2@1+ (1,0) [0|0] "" Vector__XXX
 SG_ APP_socOperatingMode : 40|2@1+ (1,0) [0|0] "" Vector__XXX
 SG_ APP_DDAWSystemStatus : 37|3@1+ (1,0) [0|0] "" Vector__XXX
 SG_ APP_sendingBUCStream : 35|1@1+ (1,0) [0|0] "" Vector__XXX
 SG_ APP_unifiedObjectStackSupported : 33|2@1+ (1,0) [0|0] "" Vector__XXX
 SG_ APP_excessiveAccelPedalWarning : 32|1@1+ (1,0) [0|0] "" Vector__XXX
 SG_ APP_fsdRevokeCount : 29|3@1+ (1,0) [0|0] "" Vector__XXX
 SG_ APP_teslaVisionUnsupportedReason : 26|3@1+ (1,0) [0|0] "" Vector__XXX
 SG_ APP_teslaVisionSupported : 24|2@1+ (1,0) [0|0] "" Vector__XXX
 SG_ APP_fsdRevokeStrikeoutCount : 21|3@1+ (1,0) [0|0] "" Vector__XXX
 SG_ APP_fsdSuspendState : 19|2@1+ (1,0) [0|0] "" Vector__XXX
 SG_ APP_summonUnavailableReason : 14|5@1+ (1,0) [0|0] "" Vector__XXX
 SG_ APP_allowApActivationWithBrake : 13|1@1+ (1,0) [0|0] "" Vector__XXX
 SG_ APP_clipRecordingStatus : 10|3@1+ (1,0) [0|0] "" Vector__XXX
 SG_ APP_factorySummonStatus : 6|4@1+ (1,0) [0|0] "" Vector__XXX
 SG_ APP_cameraHeaterRequest : 5|1@1+ (1,0) [0|0] "" Vector__XXX
 SG_ APP_fusedState : 3|2@1+ (1,0) [0|0] "" Vector__XXX
 SG_ APP_watchdogState : 0|3@1+ (1,0) [0|0] "" Vector__XXX

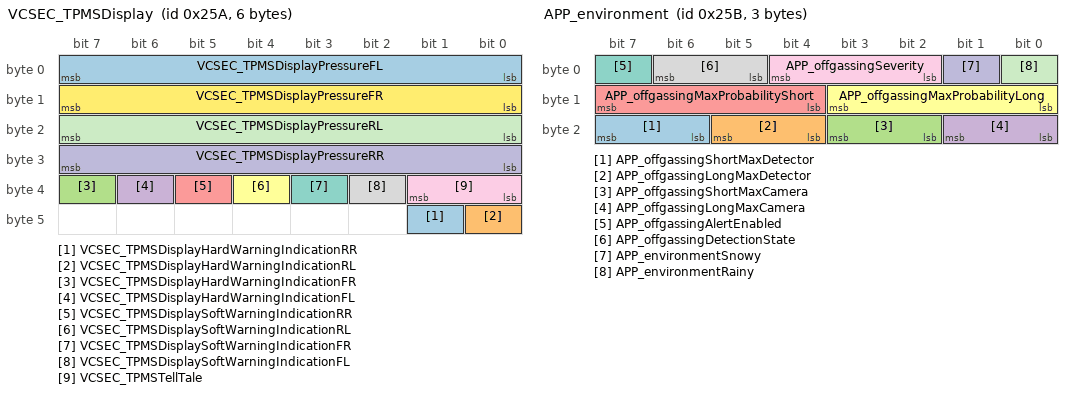
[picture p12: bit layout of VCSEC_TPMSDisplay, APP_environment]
BO_ 602 VCSEC_TPMSDisplay: 6 Vector__XXX
 SG_ VCSEC_TPMSDisplayHardWarningIndicationRR : 41|1@1+ (1,0) [0|0] "" Vector__XXX
 SG_ VCSEC_TPMSDisplayHardWarningIndicationRL : 40|1@1+ (1,0) [0|0] "" Vector__XXX
 SG_ VCSEC_TPMSDisplayHardWarningIndicationFR : 39|1@1+ (1,0) [0|0] "" Vector__XXX
 SG_ VCSEC_TPMSDisplayHardWarningIndicationFL : 38|1@1+ (1,0) [0|0] "" Vector__XXX
 SG_ VCSEC_TPMSDisplaySoftWarningIndicationRR : 37|1@1+ (1,0) [0|0] "" Vector__XXX
 SG_ VCSEC_TPMSDisplaySoftWarningIndicationRL : 36|1@1+ (1,0) [0|0] "" Vector__XXX
 SG_ VCSEC_TPMSDisplaySoftWarningIndicationFR : 35|1@1+ (1,0) [0|0] "" Vector__XXX
 SG_ VCSEC_TPMSDisplaySoftWarningIndicationFL : 34|1@1+ (1,0) [0|0] "" Vector__XXX
 SG_ VCSEC_TPMSTellTale : 32|2@1+ (1,0) [0|0] "" Vector__XXX
 SG_ VCSEC_TPMSDisplayPressureRR : 24|8@1+ (0.025,0) [0|0] "" Vector__XXX
 SG_ VCSEC_TPMSDisplayPressureRL : 16|8@1+ (0.025,0) [0|0] "" Vector__XXX
 SG_ VCSEC_TPMSDisplayPressureFR : 8|8@1+ (0.025,0) [0|0] "" Vector__XXX
 SG_ VCSEC_TPMSDisplayPressureFL : 0|8@1+ (0.025,0) [0|0] "" Vector__XXX

BO_ 603 APP_environment: 3 Vector__XXX
 SG_ APP_offgassingShortMaxDetector : 22|2@1+ (1,0) [0|0] "" Vector__XXX
 SG_ APP_offgassingLongMaxDetector : 20|2@1+ (1,0) [0|0] "" Vector__XXX
 SG_ APP_offgassingShortMaxCamera : 18|2@1+ (1,0) [0|0] "" Vector__XXX
 SG_ APP_offgassingLongMaxCamera : 16|2@1+ (1,0) [0|0] "" Vector__XXX
 SG_ APP_offgassingMaxProbabilityShort : 12|4@1+ (1,0) [0|0] "" Vector__XXX
 SG_ APP_offgassingMaxProbabilityLong : 8|4@1+ (1,0) [0|0] "" Vector__XXX
 SG_ APP_offgassingAlertEnabled : 7|1@1+ (1,0) [0|0] "" Vector__XXX
 SG_ APP_offgassingDetectionState : 5|2@1+ (1,0) [0|0] "" Vector__XXX
 SG_ APP_offgassingSeverity : 2|3@1+ (1,0) [0|0] "" Vector__XXX
 SG_ APP_environmentSnowy : 1|1@1+ (1,0) [0|0] "" Vector__XXX
 SG_ APP_environmentRainy : 0|1@1+ (1,0) [0|0] "" Vector__XXX

BO_ 637 APS_eacMonitor: 3 Vector__XXX
 SG_ APS_eacMonitorChecksum : 16|8@1+ (1,0) [0|0] "" Vector__XXX
 SG_ APS_eacMonitorCounter : 8|4@1+ (1,0) [0|0] "" Vector__XXX
 SG_ APS_eacAllow : 0|2@1+ (1,0) [0|0] "" Vector__XXX

BO_ 644 UI_vehicleModes: 8 Vector__XXX
 SG_ UI_vehicleModesChecksum : 56|8@1+ (1,0) [0|0] "" Vector__XXX
 SG_ UI_vehicleModesCounter : 52|4@1+ (1,0) [0|0] "" Vector__XXX
 SG_ UI_upkeepMode : 46|1@1+ (1,0) [0|0] "" Vector__XXX
 SG_ UI_sohTestRequest : 45|1@1+ (1,0) [0|0] "" Vector__XXX
 SG_ UI_lightShowType : 42|3@1+ (1,0) [0|0] "" Vector__XXX
 SG_ UI_closureEasterEggStatus : 40|2@1+ (1,0) [0|0] "" Vector__XXX
 SG_ UI_signedCmdServiceMode : 39|1@1+ (1,0) [0|0] "" Vector__XXX
 SG_ UI_signedCmdHardLocked : 38|1@1+ (1,0) [0|0] "" Vector__XXX
 SG_ UI_premiumAmpPowerOff : 37|1@1+ (1,0) [0|0] "" Vector__XXX
 SG_ UI_serviceModePlus : 36|1@1+ (1,0) [0|0] "" Vector__XXX
 SG_ UI_diagnosticsAllowed : 35|1@1+ (1,0) [0|0] "" Vector__XXX
 SG_ UI_gameMode : 34|1@1+ (1,0) [0|0] "" Vector__XXX
 SG_ UI_valetMode : 33|1@1+ (1,0) [0|0] "" Vector__XXX
 SG_ UI_carWashMode : 32|1@1+ (1,0) [0|0] "" Vector__XXX
 SG_ UI_homelinkV2Command2 : 24|8@1+ (1,0) [0|0] "" Vector__XXX
 SG_ UI_homelinkV2Command1 : 16|8@1+ (1,0) [0|0] "" Vector__XXX
 SG_ UI_homelinkV2Command0 : 8|8@1+ (1,0) [0|0] "" Vector__XXX
 SG_ UI_hasEverBeenDelivered : 5|1@1+ (1,0) [0|0] "" Vector__XXX
 SG_ UI_isDelivered : 4|1@1+ (1,0) [0|0] "" Vector__XXX
 SG_ UI_serviceMode : 3|1@1+ (1,0) [0|0] "" Vector__XXX
 SG_ UI_showroomMode : 2|1@1+ (1,0) [0|0] "" Vector__XXX
 SG_ UI_transportMode : 1|1@1+ (1,0) [0|0] "" Vector__XXX
 SG_ UI_factoryMode : 0|1@1+ (1,0) [0|0] "" Vector__XXX

BO_ 659 UI_chassisControl: 8 Vector__XXX
 SG_ UI_chassisControlChecksum : 56|8@1+ (1,0) [0|0] "" Vector__XXX
 SG_ UI_chassisControlCounter : 52|4@1+ (1,0) [0|0] "" Vector__XXX
 SG_ UI_selfParkTune : 48|4@1+ (1,0) [0|0] "" Vector__XXX
 SG_ UI_redLightStopSignEnable : 46|2@1+ (1,0) [0|0] "" Vector__XXX
 SG_ UI_pedalMap_epas : 44|2@1+ (1,0) [0|0] "" Vector__XXX
 SG_ UI_pedalSafetyEnable : 42|2@1+ (1,0) [0|0] "" Vector__XXX
 SG_ UI_ldwEnable : 40|2@1+ (1,0) [0|0] "" Vector__XXX
 SG_ UI_latControlEnable : 38|2@1+ (1,0) [0|0] "" Vector__XXX
 SG_ UI_fcwSensitivity : 36|2@1+ (1,0) [0|0] "" Vector__XXX
 SG_ UI_fcwEnable : 34|2@1+ (1,0) [0|0] "" Vector__XXX
 SG_ UI_bsdEnable : 32|2@1+ (1,0) [0|0] "" Vector__XXX
 SG_ UI_autoParkRequest : 28|4@1+ (1,0) [0|0] "" Vector__XXX
 SG_ UI_rebootAutopilot : 27|1@1+ (1,0) [0|0] "" Vector__XXX
 SG_ UI_winchProxUserOverride : 26|1@1+ (1,0) [0|0] "" Vector__XXX
 SG_ UI_autoLaneChangeEnable : 24|2@1+ (1,0) [0|0] "" Vector__XXX
 SG_ UI_ahlbEnable : 22|2@1+ (1,0) [0|0] "" Vector__XXX
 SG_ UI_aesEnable : 20|2@1+ (1,0) [0|0] "" Vector__XXX
 SG_ UI_aebEnable : 18|2@1+ (1,0) [0|0] "" Vector__XXX
 SG_ UI_accOvertakeEnable : 16|2@1+ (1,0) [0|0] "" Vector__XXX
 SG_ UI_dasDebugEnable : 14|1@1+ (1,0) [0|0] "" Vector__XXX
 SG_ UI_distanceUnits : 13|1@1+ (1,0) [0|0] "" Vector__XXX
 SG_ UI_trailerMode : 12|1@1+ (1,0) [0|0] "" Vector__XXX
 SG_ UI_zeroSpeedConfirmed : 10|2@1+ (1,0) [0|0] "" Vector__XXX
 SG_ UI_winchModeRequest : 8|2@1+ (1,0) [0|0] "" Vector__XXX
 SG_ UI_narrowGarages : 7|1@1+ (1,0) [0|0] "" Vector__XXX
 SG_ UI_parkBrakeRequest : 5|2@1+ (1,0) [0|0] "" Vector__XXX
 SG_ UI_tractionControlMode : 2|3@1+ (1,0) [0|0] "" Vector__XXX
 SG_ UI_steeringTuneRequest : 0|2@1+ (1,0) [0|0] "" Vector__XXX

BO_ 680 EPBL_status: 8 Vector__XXX
 SG_ EPBL_statusChecksum : 56|8@1+ (1,0) [0|0] "" Vector__XXX
 SG_ EPBL_statusCounter : 52|4@1+ (1,0) [0|0] "" Vector__XXX
 SG_ EPBL_blockDrive : 51|1@1+ (1,0) [0|0] "" Vector__XXX
 SG_ EPBL_bothDisconnected : 50|1@1+ (1,0) [0|0] "" Vector__XXX
 SG_ EPBL_winchModeAvailable : 49|1@1+ (1,0) [0|0] "" Vector__XXX
 SG_ EPBL_hornRequest : 48|1@1+ (1,0) [0|0] "" Vector__XXX
 SG_ EPBL_okToPark : 47|1@1+ (1,0) [0|0] "" Vector__XXX
 SG_ EPBL_espPowerRequest : 46|1@1+ (1,0) [0|0] "" Vector__XXX
 SG_ EPBL_showStalkFaultedOnUi : 45|1@1+ (1,0) [0|0] "" Vector__XXX
 SG_ EPBL_autonomyBehavior : 43|2@1+ (1,0) [0|0] "" Vector__XXX
 SG_ EPBL_uiWinchModeLvStatus : 33|2@1+ (1,0) [0|0] "" Vector__XXX
 SG_ EPBL_showUiGearShifter : 32|1@1+ (1,0) [0|0] "" Vector__XXX
 SG_ EPBL_brakeDiscWipeRequest : 30|2@1+ (1,0) [0|0] "" Vector__XXX
 SG_ EPBL_uiParkAvailable : 28|2@1+ (1,0) [0|0] "" Vector__XXX
 SG_ EPBL_cdpRequest : 27|1@1+ (1,0) [0|0] "" Vector__XXX
 SG_ EPBL_winchModePending : 26|1@1+ (1,0) [0|0] "" Vector__XXX
 SG_ EPBL_winchModePermissive : 25|1@1+ (1,0) [0|0] "" Vector__XXX
 SG_ EPBL_updateMode : 24|1@1+ (1,0) [0|0] "" Vector__XXX
 SG_ EPBL_winchModeActive : 23|1@1+ (1,0) [0|0] "" Vector__XXX
 SG_ EPBL_uiWinchModeMiscBlocking : 22|1@1+ (1,0) [0|0] "" Vector__XXX
 SG_ EPBL_requestUserConfirmation : 21|1@1+ (1,0) [0|0] "" Vector__XXX
 SG_ EPBL_brakeConfirmedPressed : 20|1@1+ (1,0) [0|0] "" Vector__XXX
 SG_ EPBL_epbConfigMismatch : 19|1@1+ (1,0) [0|0] "" Vector__XXX
 SG_ EPBL_brakeLight : 18|1@1+ (1,0) [0|0] "" Vector__XXX
 SG_ EPBL_summonEnabled : 17|1@1+ (1,0) [0|0] "" Vector__XXX
 SG_ EPBL_redundantBrakingEnabled : 16|1@1+ (1,0) [0|0] "" Vector__XXX
 SG_ EPBL_contactorCycleNotNeededForWinchEntry : 15|1@1+ (1,0) [0|0] "" Vector__XXX
 SG_ EPBL_telltale : 12|3@1+ (1,0) [0|0] "" Vector__XXX
 SG_ EPBL_chimeRequest : 9|3@1+ (1,0) [0|0] "" Vector__XXX
 SG_ EPBL_systemCdpAvailable : 8|1@1+ (1,0) [0|0] "" Vector__XXX
 SG_ EPBL_driverIsLeavingAnySpeed : 7|1@1+ (1,0) [0|0] "" Vector__XXX
 SG_ EPBL_driverIsLeaving : 6|1@1+ (1,0) [0|0] "" Vector__XXX
 SG_ EPBL_freeRollModeStatus : 4|2@1+ (1,0) [0|0] "" Vector__XXX
 SG_ EPBL_systemStatus : 0|4@1+ (1,0) [0|0] "" Vector__XXX

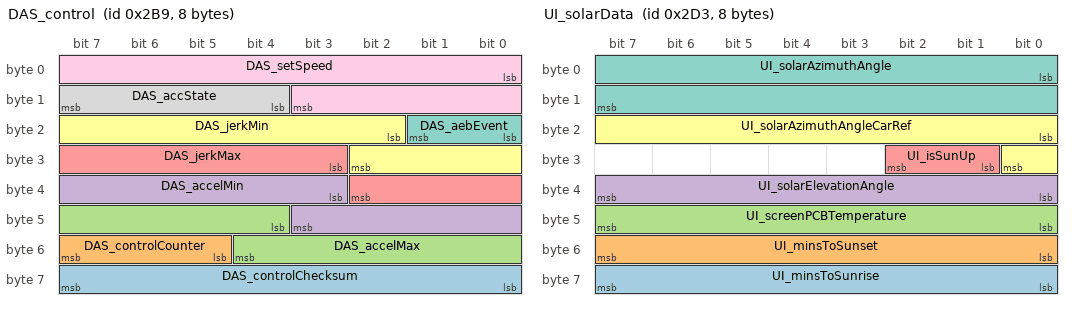
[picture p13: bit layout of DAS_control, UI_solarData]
BO_ 697 DAS_control: 8 Vector__XXX
 SG_ DAS_controlChecksum : 56|8@1+ (1,0) [0|0] "" Vector__XXX
 SG_ DAS_controlCounter : 53|3@1+ (1,0) [0|0] "" Vector__XXX
 SG_ DAS_accelMax : 44|9@1+ (0.04,-15) [0|0] "" Vector__XXX
 SG_ DAS_accelMin : 35|9@1+ (0.04,-15) [0|0] "" Vector__XXX
 SG_ DAS_jerkMax : 27|8@1+ (0.059,0) [0|0] "" Vector__XXX
 SG_ DAS_jerkMin : 18|9@1+ (0.03,-15.232) [0|0] "" Vector__XXX
 SG_ DAS_aebEvent : 16|2@1+ (1,0) [0|0] "" Vector__XXX
 SG_ DAS_accState : 12|4@1+ (1,0) [0|0] "" Vector__XXX
 SG_ DAS_setSpeed : 0|12@1+ (0.1,0) [0|0] "" Vector__XXX

BO_ 723 UI_solarData: 8 Vector__XXX
 SG_ UI_minsToSunrise : 56|8@1+ (10,0) [0|0] "" Vector__XXX
 SG_ UI_minsToSunset : 48|8@1+ (10,0) [0|0] "" Vector__XXX
 SG_ UI_screenPCBTemperature : 40|8@1- (0.5,40) [0|0] "" Vector__XXX
 SG_ UI_solarElevationAngle : 32|8@1- (1,0) [0|0] "" Vector__XXX
 SG_ UI_isSunUp : 25|2@1+ (1,0) [0|0] "" Vector__XXX
 SG_ UI_solarAzimuthAngleCarRef : 16|9@1- (1,0) [0|0] "" Vector__XXX
 SG_ UI_solarAzimuthAngle : 0|16@1- (1,0) [0|0] "" Vector__XXX

BO_ 737 VCFRONT_status: 8 VEH
 SG_ VCFRONT_isActiveHeatingBattery m0 : 63|1@1+ (1,0) [0|1] ""  X
 SG_ VCFRONT_frunkAccessPost m0 : 62|1@1+ (1,0) [0|1] ""  X
 SG_ VCFRONT_headlampRightFanStatus m0 : 61|1@1+ (1,0) [0|1] ""  X
 SG_ VCFRONT_headlampLeftFanStatus m0 : 60|1@1+ (1,0) [0|1] ""  X
 SG_ VCFRONT_frunkLatchType m0 : 58|2@1+ (1,0) [0|2] ""  X
 SG_ VCFRONT_refrigFillRoutineStatus m3 : 52|2@1+ (1,0) [0|3] ""  Receiver
 SG_ VCFRONT_radarHeaterState m0 : 52|3@1+ (1,0) [0|4] ""  X
 SG_ VCFRONT_hornOn m0 : 51|1@1+ (1,0) [0|1] ""  X
 SG_ VCFRONT_coolantFillRoutineStatus m3 : 50|2@1+ (1,0) [0|3] ""  X
 SG_ VCFRONT_anyDoorOpen m0 : 50|1@1+ (1,0) [0|1] ""  X
 SG_ VCFRONT_anyClosureOpen m0 : 49|1@1+ (1,0) [0|1] ""  X
 SG_ VCFRONT_hvacPerfTestCommand m3 : 48|2@1+ (1,0) [0|2] ""  X
 SG_ VCFRONT_homelinkCommStatus m2 : 48|2@1+ (1,0) [0|3] ""  X
 SG_ VCFRONT_frunkInteriorRelSwitch m0 : 48|1@1+ (1,0) [0|1] ""  X
 SG_ VCFRONT_shortedCellFaultCounter m4 : 44|3@1+ (1,0) [0|7] ""  X
 SG_ VCFRONT_vbatProt m5 : 40|12@1+ (0.00544368,0) [0|22.2919] "V"  X
 SG_ VCFRONT_pressureRefrigDischarge m3 : 40|8@1+ (0.125,0) [0|31.75] "bar"  X
 SG_ VCFRONT_homelinkV2Response4 m2 : 40|8@1+ (1,0) [0|255] ""  X
 SG_ VCFRONT_headlightRightVPosition m0 : 38|10@1+ (1,0) [0|1023] "ticks"  X
 SG_ VCFRONT_sleepCurrent m1 : 32|12@1- (0.1,-204.7) [-409.5|0] "mA"  X
 SG_ VCFRONT_silentWakeIBSCurrent m4 : 32|12@1- (0.1,-204.7) [-409.5|0] "mA"  X
 SG_ VCFRONT_pressureRefrigSuction m3 : 32|7@1+ (0.125,0) [0|11.5] "bar"  X
 SG_ VCFRONT_homelinkV2Response3 m2 : 32|8@1+ (1,0) [0|255] ""  X
 SG_ VCFRONT_isHeatPumpOilPurgeActive m3 : 31|1@1+ (1,0) [0|1] ""  X
 SG_ VCFRONT_reverseBatteryFault m4 : 30|1@1+ (1,0) [0|1] ""  X
 SG_ VCFRONT_isColdStartRunning m3 : 30|1@1+ (1,0) [0|1] ""  X
 SG_ VCFRONT_hasLowRefrigerant m3 : 29|1@1+ (1,0) [0|1] ""  X
 SG_ VCFRONT_voltageProfile m4 : 28|2@1+ (1,0) [0|3] ""  X
 SG_ VCFRONT_headlightLeftVPosition m0 : 28|10@1+ (1,0) [0|1023] "ticks"  X
 SG_ VCFRONT_AS8510Voltage m5 : 28|12@1+ (0.00544368,0) [0|22.2864] "V"  X
 SG_ VCFRONT_compPerfRecoveryLimited m3 : 27|1@1+ (1,0) [0|1] ""  X
 SG_ VCFRONT_chillerDemandActive m3 : 26|1@1+ (1,0) [0|1] ""  X
 SG_ VCFRONT_isEvapOperationAllowed m3 : 25|1@1+ (1,0) [0|1] ""  X
 SG_ VCFRONT_airCompressorStatus m0 : 25|3@1+ (1,0) [0|7] ""  X
 SG_ VCFRONT_voltageFloorReachedCount m4 : 24|4@1+ (1,0) [0|15] ""  X
 SG_ VCFRONT_timeSpentSleeping m1 : 24|8@1+ (1,0) [0|255] "s"  X
 SG_ VCFRONT_homelinkV2Response2 m2 : 24|8@1+ (1,0) [0|255] ""  X
 SG_ VCFRONT_freezeEvapITerm m3 : 24|1@1+ (1,0) [0|1] ""  X
 SG_ VCFRONT_crashUnlockOverrideSet m0 : 24|1@1+ (1,0) [0|1] ""  X
 SG_ VCFRONT_crashState m0 : 22|2@1+ (1,0) [0|2] ""  X
 SG_ VCFRONT_voltageDropCounter m4 : 20|4@1+ (1,0) [0|15] ""  X
 SG_ VCFRONT_crashDetectedType m0 : 20|2@1+ (1,0) [0|2] ""  X
 SG_ VCFRONT_wiperState m0 : 16|4@1+ (1,0) [0|12] ""  X
 SG_ VCFRONT_vbatMonitorVoltage m5 : 16|12@1+ (0.00544368,0) [0|22.2864] "V"  X
 SG_ VCFRONT_minEvapHeatRejection m3 : 16|8@1+ (10,0) [0|2500] "W"  X
 SG_ VCFRONT_homelinkV2Response1 m2 : 16|8@1+ (1,0) [0|255] ""  X
 SG_ VCFRONT_batterySMState m1 : 16|4@1+ (1,0) [0|8] ""  X
 SG_ VCFRONT_12VOverchargeCounter m4 : 16|4@1+ (1,0) [0|15] ""  X
 SG_ VCFRONT_IBSFault m4 : 15|1@1+ (1,0) [0|1] ""  X
 SG_ VCFRONT_PCSMia m4 : 14|1@1+ (1,0) [0|1] ""  X
 SG_ VCFRONT_chargeNeeded m4 : 13|1@1+ (1,0) [0|1] ""  X
 SG_ VCFRONT_wiperPosition m0 : 12|3@1+ (1,0) [0|4] ""  X
 SG_ VCFRONT_HSDInitCompleteU16 m5 : 12|1@1+ (1,0) [0|1] ""  X
 SG_ VCFRONT_HSDInitCompleteU13 m5 : 11|1@1+ (1,0) [0|1] ""  X
 SG_ VCFRONT_PEResetLineState m5 : 10|1@1+ (1,0) [0|1] ""  X
 SG_ VCFRONT_ChargePumpVoltageStable m5 : 9|1@1+ (1,0) [0|1] ""  X
 SG_ VCFRONT_wiperSpeed m0 : 8|4@1+ (1,0) [0|8] ""  X
 SG_ VCFRONT_vehicleStatusDBG m1 : 8|5@1+ (1,0) [0|17] ""  X
 SG_ VCFRONT_railBState m5 : 8|1@1+ (1,0) [0|1] ""  X
 SG_ VCFRONT_maxEvapHeatRejection m3 : 8|8@1+ (65,0) [0|16575] "W"  X
 SG_ VCFRONT_homelinkV2Response0 m2 : 8|8@1+ (1,0) [0|255] ""  X
 SG_ VCFRONT_railAState m5 : 7|1@1+ (1,0) [0|1] ""  X
 SG_ VCFRONT_12VBRailStable m5 : 6|1@1+ (1,0) [0|1] ""  X
 SG_ VCFRONT_iBoosterStateDBG m1 : 5|3@1+ (1,0) [0|4] ""  X
 SG_ VCFRONT_12VARailStable m5 : 5|1@1+ (1,0) [0|1] ""  X
 SG_ VCFRONT_epasWakeLine m1 : 4|1@1+ (1,0) [0|1] ""  X
 SG_ VCFRONT_5VBRailStable m5 : 4|1@1+ (1,0) [0|1] ""  X
 SG_ VCFRONT_tempCompTargetVoltage m4 : 3|10@1+ (0.01,9) [9|16] "V"  X
 SG_ VCFRONT_iBoosterWakeLine m1 : 3|1@1+ (1,0) [0|1] ""  X
 SG_ VCFRONT_frunkLatchStatus m0 : 3|4@1+ (1,0) [0|8] ""  X
 SG_ VCFRONT_5VARailStable m5 : 3|1@1+ (1,0) [0|1] ""  X
 SG_ VCFRONT_statusIndex M : 0|3@1+ (1,0) [0|6] ""  X

BO_ 744 EPBR_status: 8 Vector__XXX
 SG_ EPBR_statusChecksum : 56|8@1+ (1,0) [0|0] "" Vector__XXX
 SG_ EPBR_statusCounter : 52|4@1+ (1,0) [0|0] "" Vector__XXX
 SG_ EPBR_blockDrive : 51|1@1+ (1,0) [0|0] "" Vector__XXX
 SG_ EPBR_bothDisconnected : 50|1@1+ (1,0) [0|0] "" Vector__XXX
 SG_ EPBR_winchModeAvailable : 49|1@1+ (1,0) [0|0] "" Vector__XXX
 SG_ EPBR_hornRequest : 48|1@1+ (1,0) [0|0] "" Vector__XXX
 SG_ EPBR_okToPark : 47|1@1+ (1,0) [0|0] "" Vector__XXX
 SG_ EPBR_espPowerRequest : 46|1@1+ (1,0) [0|0] "" Vector__XXX
 SG_ EPBR_showStalkFaultedOnUi : 45|1@1+ (1,0) [0|0] "" Vector__XXX
 SG_ EPBR_autonomyBehavior : 43|2@1+ (1,0) [0|0] "" Vector__XXX
 SG_ EPBR_contactorCycleNotNeededForWinchEntry : 35|1@1+ (1,0) [0|0] "" Vector__XXX
 SG_ EPBR_uiWinchModeLvStatus : 33|2@1+ (1,0) [0|0] "" Vector__XXX
 SG_ EPBR_showUiGearShifter : 32|1@1+ (1,0) [0|0] "" Vector__XXX
 SG_ EPBR_brakeDiscWipeRequest : 30|2@1+ (1,0) [0|0] "" Vector__XXX
 SG_ EPBR_uiParkAvailable : 28|2@1+ (1,0) [0|0] "" Vector__XXX
 SG_ EPBR_cdpRequest : 27|1@1+ (1,0) [0|0] "" Vector__XXX
 SG_ EPBR_winchModePending : 26|1@1+ (1,0) [0|0] "" Vector__XXX
 SG_ EPBR_winchModePermissive : 25|1@1+ (1,0) [0|0] "" Vector__XXX
 SG_ EPBR_updateMode : 24|1@1+ (1,0) [0|0] "" Vector__XXX
 SG_ EPBR_winchModeActive : 23|1@1+ (1,0) [0|0] "" Vector__XXX
 SG_ EPBR_uiWinchModeMiscBlocking : 22|1@1+ (1,0) [0|0] "" Vector__XXX
 SG_ EPBR_requestUserConfirmation : 21|1@1+ (1,0) [0|0] "" Vector__XXX
 SG_ EPBR_brakeConfirmedPressed : 20|1@1+ (1,0) [0|0] "" Vector__XXX
 SG_ EPBR_epbConfigMismatch : 19|1@1+ (1,0) [0|0] "" Vector__XXX
 SG_ EPBR_brakeLight : 18|1@1+ (1,0) [0|0] "" Vector__XXX
 SG_ EPBR_summonEnabled : 17|1@1+ (1,0) [0|0] "" Vector__XXX
 SG_ EPBR_redundantBrakingEnabled : 16|1@1+ (1,0) [0|0] "" Vector__XXX
 SG_ EPBR_audioCurrentSpikeDetected : 15|1@1+ (1,0) [0|0] "" Vector__XXX
 SG_ EPBR_telltale : 12|3@1+ (1,0) [0|0] "" Vector__XXX
 SG_ EPBR_chimeRequest : 9|3@1+ (1,0) [0|0] "" Vector__XXX
 SG_ EPBR_systemCdpAvailable : 8|1@1+ (1,0) [0|0] "" Vector__XXX
 SG_ EPBR_driverIsLeavingAnySpeed : 7|1@1+ (1,0) [0|0] "" Vector__XXX
 SG_ EPBR_driverIsLeaving : 6|1@1+ (1,0) [0|0] "" Vector__XXX
 SG_ EPBR_freeRollModeStatus : 4|2@1+ (1,0) [0|0] "" Vector__XXX
 SG_ EPBR_systemStatus : 0|4@1+ (1,0) [0|0] "" Vector__XXX

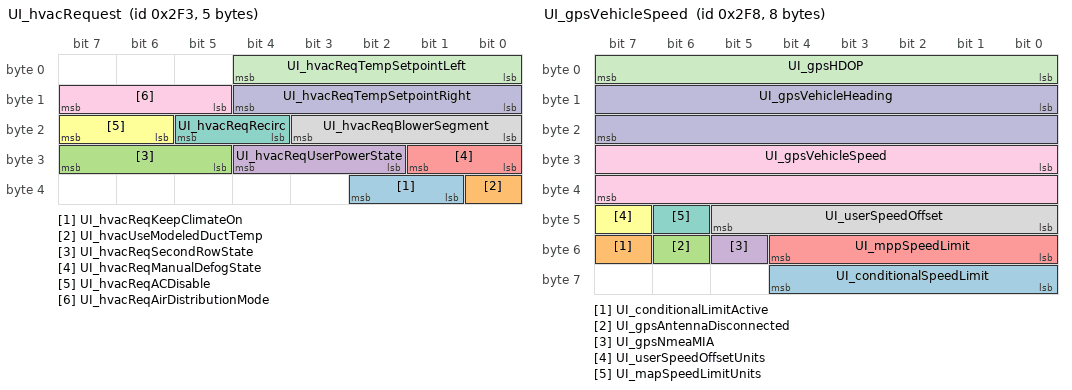
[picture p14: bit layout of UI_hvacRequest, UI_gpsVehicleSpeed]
BO_ 755 UI_hvacRequest: 5 VEH
 SG_ UI_hvacReqKeepClimateOn : 33|2@1+ (1,0) [0|3] ""  X
 SG_ UI_hvacUseModeledDuctTemp : 32|1@1+ (1,0) [0|0] ""  X
 SG_ UI_hvacReqSecondRowState : 29|3@1+ (1,0) [0|0] ""  X
 SG_ UI_hvacReqUserPowerState : 26|3@1+ (1,0) [0|0] ""  X
 SG_ UI_hvacReqManualDefogState : 24|2@1+ (1,0) [0|0] ""  X
 SG_ UI_hvacReqACDisable : 22|2@1+ (1,0) [0|0] ""  X
 SG_ UI_hvacReqRecirc : 20|2@1+ (1,0) [0|0] ""  X
 SG_ UI_hvacReqBlowerSegment : 16|4@1+ (1,0) [0|0] ""  X
 SG_ UI_hvacReqAirDistributionMode : 13|3@1+ (1,0) [0|0] ""  X
 SG_ UI_hvacReqTempSetpointRight : 8|5@1+ (0.5,15) [0|0] "degC"  X
 SG_ UI_hvacReqTempSetpointLeft : 0|5@1+ (0.5,15) [0|0] "degC"  X

BO_ 760 UI_gpsVehicleSpeed: 8 Vector__XXX
 SG_ UI_conditionalSpeedLimit : 56|5@1+ (5,0) [0|0] "" Vector__XXX
 SG_ UI_conditionalLimitActive : 55|1@1+ (1,0) [0|0] "" Vector__XXX
 SG_ UI_gpsAntennaDisconnected : 54|1@1+ (1,0) [0|0] "" Vector__XXX
 SG_ UI_gpsNmeaMIA : 53|1@1+ (1,0) [0|0] "" Vector__XXX
 SG_ UI_mppSpeedLimit : 48|5@1+ (5,0) [0|0] "" Vector__XXX
 SG_ UI_userSpeedOffsetUnits : 47|1@1+ (1,0) [0|0] "" Vector__XXX
 SG_ UI_mapSpeedLimitUnits : 46|1@1+ (1,0) [0|0] "" Vector__XXX
 SG_ UI_userSpeedOffset : 40|6@1+ (1,-30) [0|0] "" Vector__XXX
 SG_ UI_gpsVehicleSpeed : 24|16@1+ (0.00390625,0) [0|0] "" Vector__XXX
 SG_ UI_gpsVehicleHeading : 8|16@1+ (0.0078125,0) [0|0] "" Vector__XXX
 SG_ UI_gpsHDOP : 0|8@1+ (0.1,0) [0|0] "" Vector__XXX

BO_ 771 OCS1P_status: 8 Vector__XXX
 SG_ OCS1P_statusChecksum : 56|8@1+ (1,0) [0|0] "" Vector__XXX
 SG_ OCS1P_statusCounter : 52|4@1+ (1,0) [0|0] "" Vector__XXX
 SG_ OCS1P_classificationHeldCap : 51|1@1+ (1,0) [0|0] "" Vector__XXX
 SG_ OCS1P_seatbackStableCap : 50|1@1+ (1,0) [0|0] "" Vector__XXX
 SG_ OCS1P_cushionStableCap : 49|1@1+ (1,0) [0|0] "" Vector__XXX
 SG_ OCS1P_sandwichStable : 48|1@1+ (1,0) [0|0] "" Vector__XXX
 SG_ OCS1P_seatbackStable : 47|1@1+ (1,0) [0|0] "" Vector__XXX
 SG_ OCS1P_occupiedStateCap : 45|2@1+ (1,0) [0|0] "" Vector__XXX
 SG_ OCS1P_sbrBoundaryType : 43|1@1+ (1,0) [0|0] "" Vector__XXX
 SG_ OCS1P_sandwichBoundaryType : 42|1@1+ (1,0) [0|0] "" Vector__XXX
 SG_ OCS1P_noSandwichType : 40|2@1+ (1,0) [0|0] "" Vector__XXX
 SG_ OCS1P_sandwichDisabled : 39|1@1+ (1,0) [0|0] "" Vector__XXX
 SG_ OCS1P_classificationVariant : 36|3@1+ (1,0) [0|0] "" Vector__XXX
 SG_ OCS1P_classificationHoldState : 33|3@1+ (1,0) [0|0] "" Vector__XXX
 SG_ OCS1P_classificationExtHold : 32|1@1+ (1,0) [0|0] "" Vector__XXX
 SG_ OCS1P_cushionStable : 31|1@1+ (1,0) [0|0] "" Vector__XXX
 SG_ OCS1P_classificationHeld : 30|1@1+ (1,0) [0|0] "" Vector__XXX
 SG_ OCS1P_occupantClassificationCap : 25|3@1+ (1,0) [0|0] "" Vector__XXX
 SG_ OCS1P_occupantClassificationRawCap : 22|3@1+ (1,0) [0|0] "" Vector__XXX
 SG_ OCS1P_occupantClassificationSelf : 19|3@1+ (1,0) [0|0] "" Vector__XXX
 SG_ OCS1P_occupantClassificationRaw : 16|3@1+ (1,0) [0|0] "" Vector__XXX
 SG_ OCS1P_triggerSnapshot : 11|5@1+ (1,0) [0|0] "" Vector__XXX
 SG_ OCS1P_occupiedState : 9|2@1+ (1,0) [0|0] "" Vector__XXX
 SG_ OCS1P_occupantClassificationQF : 8|1@1+ (1,0) [0|0] "" Vector__XXX
 SG_ OCS1P_occupantClassification : 0|8@1+ (1,0) [0|0] "" Vector__XXX

BO_ 777 DAS_object: 8 CH
 SG_ DAS_leadVeh2Id m0 : 58|6@1+ (1,0) [0|0] ""  X
 SG_ DAS_leftVeh2Id m1 : 58|6@1+ (1,0) [0|0] ""  X
 SG_ DAS_rightVeh2Id m2 : 58|6@1+ (1,0) [0|0] ""  X
 SG_ DAS_cutinVehHeading m5 : 56|8@1+ (0.0245437,-3.14159) [0|0] "rad"  X
 SG_ DAS_leadVeh2Dy m0 : 51|7@1+ (0.35,-22.05) [0|0] "m"  X
 SG_ DAS_leftVeh2Dy m1 : 51|7@1+ (0.35,-22.05) [0|0] "m"  X
 SG_ DAS_rightVeh2Dy m2 : 51|7@1+ (0.35,-22.05) [0|0] "m"  X
 SG_ DAS_rightVeh2Heading m5 : 48|8@1+ (0.0245437,-3.14159) [0|0] "rad"  X
 SG_ DAS_leadVeh2VxRel m0 : 47|4@1+ (4,-30) [0|0] "m/s"  X
 SG_ DAS_leftVeh2VxRel m1 : 47|4@1+ (4,-30) [0|0] "m/s"  X
 SG_ DAS_rightVeh2VxRel m2 : 47|4@1+ (4,-30) [0|0] "m/s"  X
 SG_ DAS_rightVehHeading m5 : 40|8@1+ (0.0245437,-3.14159) [0|0] "rad"  X
 SG_ DAS_leadVeh2Dx m0 : 39|8@1+ (0.5,0) [0|0] "m"  X
 SG_ DAS_leftVeh2Dx m1 : 39|8@1+ (0.5,0) [0|0] "m"  X
 SG_ DAS_rightVeh2Dx m2 : 39|8@1+ (0.5,0) [0|0] "m"  X
 SG_ DAS_leadVeh2RelevantForControl m0 : 38|1@1+ (1,0) [0|0] ""  X
 SG_ DAS_leftVeh2RelevantForControl m1 : 38|1@1+ (1,0) [0|0] ""  X
 SG_ DAS_rightVeh2RelevantForControl m2 : 38|1@1+ (1,0) [0|0] ""  X
 SG_ DAS_leadVeh2Type m0 : 34|3@1+ (1,0) [0|0] ""  X
 SG_ DAS_leftVeh2Type m1 : 34|3@1+ (1,0) [0|0] ""  X
 SG_ DAS_rightVeh2Type m2 : 34|3@1+ (1,0) [0|0] ""  X
 SG_ DAS_leftVeh2Heading m5 : 32|8@1+ (0.0245437,-3.14159) [0|0] "rad"  X
 SG_ DAS_roadSignOrientation m4 : 30|2@1+ (1,0) [0|0] ""  X
 SG_ DAS_leadVehId m0 : 27|7@1+ (1,0) [0|0] ""  X
 SG_ DAS_leftVehId m1 : 27|7@1+ (1,0) [0|0] ""  X
 SG_ DAS_rightVehId m2 : 27|7@1+ (1,0) [0|0] ""  X
 SG_ DAS_cutinVehId m3 : 27|7@1+ (1,0) [0|0] ""  X
 SG_ DAS_roadSignArrow m4 : 27|3@1+ (1,0) [0|0] ""  X
 SG_ DAS_roadSignSource m4 : 25|2@1+ (1,0) [0|0] ""  X
 SG_ DAS_roadSignControlActive m4 : 24|1@1+ (1,0) [0|0] ""  X
 SG_ DAS_leftVehHeading m5 : 24|8@1+ (0.0245437,-3.14159) [0|0] "rad"  X
 SG_ DAS_leadVehDy m0 : 20|7@1+ (0.35,-22.05) [0|0] "m"  X
 SG_ DAS_leftVehDy m1 : 20|7@1+ (0.35,-22.05) [0|0] "m"  X
 SG_ DAS_rightVehDy m2 : 20|7@1+ (0.35,-22.05) [0|0] "m"  X
 SG_ DAS_cutinVehDy m3 : 20|7@1+ (0.35,-22.05) [0|0] "m"  X
 SG_ DAS_leadVehVxRel m0 : 16|4@1+ (4,-30) [0|0] "m/s"  X
 SG_ DAS_leftVehVxRel m1 : 16|4@1+ (4,-30) [0|0] "m/s"  X
 SG_ DAS_rightVehVxRel m2 : 16|4@1+ (4,-30) [0|0] "m/s"  X
 SG_ DAS_cutinVehVxRel m3 : 16|4@1+ (4,-30) [0|0] "m/s"  X
 SG_ DAS_leadVeh2Heading m5 : 16|8@1+ (0.0245437,-3.14159) [0|0] "rad"  X
 SG_ DAS_roadSignStopLineDist m4 : 14|10@1+ (0.2,-20) [0|0] "m"  X
 SG_ DAS_leadVehDx m0 : 8|8@1+ (0.5,0) [0|0] "m"  X
 SG_ DAS_leftVehDx m1 : 8|8@1+ (0.5,0) [0|0] "m"  X
 SG_ DAS_rightVehDx m2 : 8|8@1+ (0.5,0) [0|0] "m"  X
 SG_ DAS_cutinVehDx m3 : 8|8@1+ (0.5,0) [0|0] "m"  X
 SG_ DAS_leadVehHeading m5 : 8|8@1+ (0.0245437,-3.14159) [0|0] "rad"  X
 SG_ DAS_leadVehRelevantForControl m0 : 7|1@1+ (1,0) [0|0] ""  X
 SG_ DAS_leftVehRelevantForControl m1 : 7|1@1+ (1,0) [0|0] ""  X
 SG_ DAS_rightVehRelevantForControl m2 : 7|1@1+ (1,0) [0|0] ""  X
 SG_ DAS_cutinVehRelevantForControl m3 : 7|1@1+ (1,0) [0|0] ""  X
 SG_ DAS_roadSignId m4 : 6|8@1+ (1,0) [0|0] ""  X
 SG_ DAS_leadVehType m0 : 3|3@1+ (1,0) [0|0] ""  X
 SG_ DAS_leftVehType m1 : 3|3@1+ (1,0) [0|0] ""  X
 SG_ DAS_rightVehType m2 : 3|3@1+ (1,0) [0|0] ""  X
 SG_ DAS_cutinVehType m3 : 3|3@1+ (1,0) [0|0] ""  X
 SG_ DAS_roadSignColor m4 : 3|3@1+ (1,0) [0|0] ""  X
 SG_ DAS_objectId M : 0|3@1+ (1,0) [0|0] ""  X

BO_ 783 OCS1P_debugCushionMutCNTComp: 6 Vector__XXX
 SG_ OCS1P_deltaFreqCushionMut : 32|16@1- (1,0) [0|0] "" Vector__XXX
 SG_ OCS1P_cushionMutCNTFreqComp : 0|16@1+ (1,0) [0|0] "" Vector__XXX

BO_ 785 EPAS3S_info: 8 Vector__XXX
 SG_ EPAS3S_infoComponentID m10 : 48|16@1+ (1,0) [0|0] "" Vector__XXX
 SG_ EPAS3S_infoApplicationCRC m13 : 32|32@1+ (1,0) [0|0] "" Vector__XXX
 SG_ EPAS3S_infoBootloaderCRC m20 : 32|32@1+ (1,0) [0|0] "" Vector__XXX
 SG_ EPAS3S_infoSubcomponent2 m23 : 32|32@1+ (1,0) [0|0] "" Vector__XXX
 SG_ EPAS3S_infoUsageID m11 : 32|16@1+ (1,0) [0|0] "" Vector__XXX
 SG_ EPAS3S_infoAssemblyID m11 : 24|8@1+ (1,0) [0|0] "" Vector__XXX
 SG_ EPAS3S_infoPcbaID m11 : 16|8@1+ (1,0) [0|0] "" Vector__XXX
 SG_ EPAS3S_infoBootUdsProtoVersion m20 : 8|8@1+ (1,0) [0|0] "" Vector__XXX
 SG_ EPAS3S_infoBuildType m10 : 8|8@1+ (1,0) [0|0] "" Vector__XXX
 SG_ EPAS3S_infoIndex M : 0|8@1+ (1,0) [0|0] "" Vector__XXX

BO_ 789 OCS1P_info: 8 Vector__XXX
 SG_ OCS1P_infoComponentID m10 : 48|16@1+ (1,0) [0|0] "" Vector__XXX
 SG_ OCS1P_infoSubUsageID m11 : 48|16@1+ (1,0) [0|0] "" Vector__XXX
 SG_ OCS1P_infoApplicationCRC m13 : 32|32@1+ (1,0) [0|0] "" Vector__XXX
 SG_ OCS1P_infoBootloaderCRC m20 : 32|32@1+ (1,0) [0|0] "" Vector__XXX
 SG_ OCS1P_infoHardwareID m10 : 32|16@1+ (1,0) [0|0] "" Vector__XXX
 SG_ OCS1P_infoUsageID m11 : 32|16@1+ (1,0) [0|0] "" Vector__XXX
 SG_ OCS1P_infoAssemblyID m11 : 24|8@1+ (1,0) [0|0] "" Vector__XXX
 SG_ OCS1P_infoBuildConfigID m10 : 16|16@1+ (1,0) [0|0] "" Vector__XXX
 SG_ OCS1P_infoPcbaID m11 : 16|8@1+ (1,0) [0|0] "" Vector__XXX
 SG_ OCS1P_infoAppGitHashBytes m17 : 8|56@1+ (1,0) [0|0] "" Vector__XXX
 SG_ OCS1P_infoBootGitHashBytes m18 : 8|56@1+ (1,0) [0|0] "" Vector__XXX
 SG_ OCS1P_infoBootSvnRev m14 : 8|24@1+ (1,0) [0|0] "" Vector__XXX
 SG_ OCS1P_infoBootUdsProtoVersion m20 : 8|8@1+ (1,0) [0|0] "" Vector__XXX
 SG_ OCS1P_infoBuildType m10 : 8|8@1+ (1,0) [0|0] "" Vector__XXX
 SG_ OCS1P_infoPlatformType m19 : 8|8@1+ (1,0) [0|0] "" Vector__XXX
 SG_ OCS1P_infoIndex M : 0|8@1+ (1,0) [0|0] "" Vector__XXX

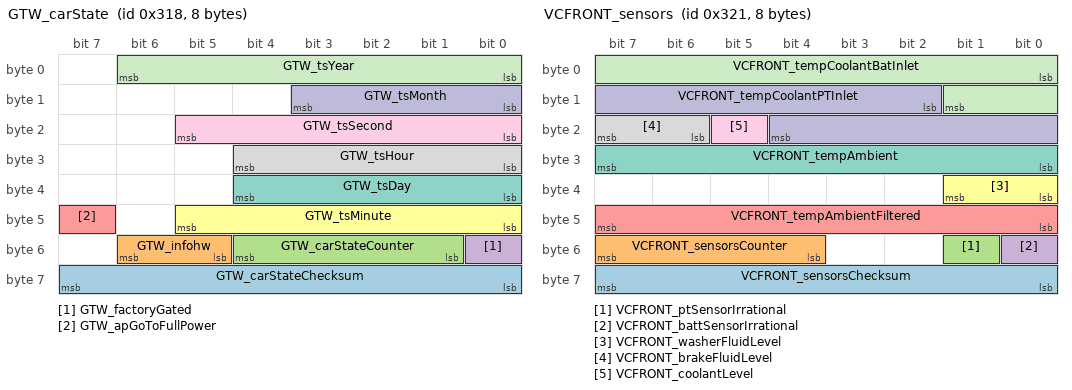
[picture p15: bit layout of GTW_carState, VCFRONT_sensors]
BO_ 792 GTW_carState: 8 Vector__XXX
 SG_ GTW_carStateChecksum : 56|8@1+ (1,0) [0|0] "" Vector__XXX
 SG_ GTW_infohw : 53|2@1+ (1,0) [0|0] "" Vector__XXX
 SG_ GTW_carStateCounter : 49|4@1+ (1,0) [0|0] "" Vector__XXX
 SG_ GTW_factoryGated : 48|1@1+ (1,0) [0|0] "" Vector__XXX
 SG_ GTW_apGoToFullPower : 47|1@1+ (1,0) [0|0] "" Vector__XXX
 SG_ GTW_tsMinute : 40|6@1+ (1,0) [0|0] "" Vector__XXX
 SG_ GTW_tsDay : 32|5@1+ (1,0) [0|0] "" Vector__XXX
 SG_ GTW_tsHour : 24|5@1+ (1,0) [0|0] "" Vector__XXX
 SG_ GTW_tsSecond : 16|6@1+ (1,0) [0|0] "" Vector__XXX
 SG_ GTW_tsMonth : 8|4@1+ (1,0) [0|0] "" Vector__XXX
 SG_ GTW_tsYear : 0|7@1+ (1,2000) [0|0] "" Vector__XXX

BO_ 801 VCFRONT_sensors: 8 Vector__XXX
 SG_ VCFRONT_sensorsChecksum : 56|8@1+ (1,0) [0|0] "" Vector__XXX
 SG_ VCFRONT_sensorsCounter : 52|4@1+ (1,0) [0|0] "" Vector__XXX
 SG_ VCFRONT_ptSensorIrrational : 49|1@1+ (1,0) [0|0] "" Vector__XXX
 SG_ VCFRONT_battSensorIrrational : 48|1@1+ (1,0) [0|0] "" Vector__XXX
 SG_ VCFRONT_tempAmbientFiltered : 40|8@1+ (0.5,-40) [0|0] "" Vector__XXX
 SG_ VCFRONT_washerFluidLevel : 32|2@1+ (1,0) [0|0] "" Vector__XXX
 SG_ VCFRONT_tempAmbient : 24|8@1+ (0.5,-40) [0|0] "" Vector__XXX
 SG_ VCFRONT_brakeFluidLevel : 22|2@1+ (1,0) [0|0] "" Vector__XXX
 SG_ VCFRONT_coolantLevel : 21|1@1+ (1,0) [0|0] "" Vector__XXX
 SG_ VCFRONT_tempCoolantPTInlet : 10|11@1+ (0.125,-40) [0|0] "" Vector__XXX
 SG_ VCFRONT_tempCoolantBatInlet : 0|10@1+ (0.125,-40) [0|0] "" Vector__XXX

BO_ 805 ESP_info: 8 Vector__XXX
 SG_ ESP_infoComponentID m10 : 48|16@1+ (1,0) [0|0] "" Vector__XXX
 SG_ ESP_infoSubUsageID m11 : 48|16@1+ (1,0) [0|0] "" Vector__XXX
 SG_ ESP_infoBootloaderCRC m20 : 32|32@1+ (1,0) [0|0] "" Vector__XXX
 SG_ ESP_infoSubcomponent1 m16 : 32|32@1+ (1,0) [0|0] "" Vector__XXX
 SG_ ESP_infoUsageID m11 : 32|16@1+ (1,0) [0|0] "" Vector__XXX
 SG_ ESP_infoApplicationCRC m13 : 39|32@0+ (1,0) [0|0] "" Vector__XXX
 SG_ ESP_infoVariantCRC m22 : 39|32@0+ (1,0) [0|0] "" Vector__XXX
 SG_ ESP_infoAssemblyID m11 : 24|8@1+ (1,0) [0|0] "" Vector__XXX
 SG_ ESP_vehFlashMode m10 : 24|1@1+ (1,0) [0|0] "" Vector__XXX
 SG_ ESP_infoPcbaID m11 : 16|8@1+ (1,0) [0|0] "" Vector__XXX
 SG_ ESP_infoVehicleVariant m16 : 16|8@1+ (1,0) [0|0] "" Vector__XXX
 SG_ ESP_infoBootUdsProtoVersion m20 : 8|8@1+ (1,0) [0|0] "" Vector__XXX
 SG_ ESP_infoBuildType m10 : 8|8@1+ (1,0) [0|0] "" Vector__XXX
 SG_ ESP_infoIndex M : 0|8@1+ (1,0) [0|0] "" Vector__XXX

BO_ 809 APP_warningMatrix0: 8 Vector__XXX
 SG_ APP_w064_epasMia : 63|1@1+ (1,0) [0|0] "" Vector__XXX
 SG_ APP_w063_parkVersionMismatch : 62|1@1+ (1,0) [0|0] "" Vector__XXX
 SG_ APP_w062_radcAlignment : 61|1@1+ (1,0) [0|0] "" Vector__XXX
 SG_ APP_w061_airSuspensionMia : 60|1@1+ (1,0) [0|0] "" Vector__XXX
 SG_ APP_w060_fcw_event : 59|1@1+ (1,0) [0|0] "" Vector__XXX
 SG_ APP_w059_parkMia : 58|1@1+ (1,0) [0|0] "" Vector__XXX
 SG_ APP_w058_epbMia : 57|1@1+ (1,0) [0|0] "" Vector__XXX
 SG_ APP_w057_mcuMia : 56|1@1+ (1,0) [0|0] "" Vector__XXX
 SG_ APP_w056_diMia : 55|1@1+ (1,0) [0|0] "" Vector__XXX
 SG_ APP_w055_radcVersionMismatch : 54|1@1+ (1,0) [0|0] "" Vector__XXX
 SG_ APP_w054_camAutofix : 53|1@1+ (1,0) [0|0] "" Vector__XXX
 SG_ APP_w053_radcCommIssue : 52|1@1+ (1,0) [0|0] "" Vector__XXX
 SG_ APP_w052_radcSensorIssue : 51|1@1+ (1,0) [0|0] "" Vector__XXX
 SG_ APP_w051_radcEcuIssue : 50|1@1+ (1,0) [0|0] "" Vector__XXX
 SG_ APP_w050_aeb_event : 49|1@1+ (1,0) [0|0] "" Vector__XXX
 SG_ APP_w049_eyeqVersionMismatch : 48|1@1+ (1,0) [0|0] "" Vector__XXX
 SG_ APP_w048_APP_Features_Disabled : 47|1@1+ (1,0) [0|0] "" Vector__XXX
 SG_ APP_w047_edrEvent : 46|1@1+ (1,0) [0|0] "" Vector__XXX
 SG_ APP_w046_eepromRecordAbsent : 45|1@1+ (1,0) [0|0] "" Vector__XXX
 SG_ APP_w045_radMia : 44|1@1+ (1,0) [0|0] "" Vector__XXX
 SG_ APP_w044_appMobileyeFailure : 43|1@1+ (1,0) [0|0] "" Vector__XXX
 SG_ APP_w043_camLongRunTime : 42|1@1+ (1,0) [0|0] "" Vector__XXX
 SG_ APP_w042_autopilotAborting : 41|1@1+ (1,0) [0|0] "" Vector__XXX
 SG_ APP_w041_autopilotRateSaturated : 40|1@1+ (1,0) [0|0] "" Vector__XXX
 SG_ APP_w040_autopilotAngleSaturated : 39|1@1+ (1,0) [0|0] "" Vector__XXX
 SG_ APP_w039_sdm_rcm_Mia : 38|1@1+ (1,0) [0|0] "" Vector__XXX
 SG_ APP_w038_camFailure : 37|1@1+ (1,0) [0|0] "" Vector__XXX
 SG_ APP_w037_camTacIssue : 36|1@1+ (1,0) [0|0] "" Vector__XXX
 SG_ APP_w036_bdyMia : 35|1@1+ (1,0) [0|0] "" Vector__XXX
 SG_ APP_w035_espMia : 34|1@1+ (1,0) [0|0] "" Vector__XXX
 SG_ APP_w034_sccmMia : 33|1@1+ (1,0) [0|0] "" Vector__XXX
 SG_ APP_w033_gtwMia : 32|1@1+ (1,0) [0|0] "" Vector__XXX
 SG_ APP_w032_canTxError : 31|1@1+ (1,0) [0|0] "" Vector__XXX
 SG_ APP_w031_canRxError : 30|1@1+ (1,0) [0|0] "" Vector__XXX
 SG_ APP_w030_Heater_Issue : 29|1@1+ (1,0) [0|0] "" Vector__XXX
 SG_ APP_w029_spi_tx_error : 28|1@1+ (1,0) [0|0] "" Vector__XXX
 SG_ APP_w028_spi_rx_error : 27|1@1+ (1,0) [0|0] "" Vector__XXX
 SG_ APP_w027_ECU_Reset_Fault : 26|1@1+ (1,0) [0|0] "" Vector__XXX
 SG_ APP_w026_ECU_timingIssue : 25|1@1+ (1,0) [0|0] "" Vector__XXX
 SG_ APP_w025_LC_Steering_Override : 24|1@1+ (1,0) [0|0] "" Vector__XXX
 SG_ APP_w024_ECU_Watchdog_Reset : 23|1@1+ (1,0) [0|0] "" Vector__XXX
 SG_ APP_w023_ECU_Cam_Statemismatc : 22|1@1+ (1,0) [0|0] "" Vector__XXX
 SG_ APP_w022_ECU_EEPROM_Failure : 21|1@1+ (1,0) [0|0] "" Vector__XXX
 SG_ APP_w021_ECU_Temperature_Issue : 20|1@1+ (1,0) [0|0] "" Vector__XXX
 SG_ APP_w020_ECU_checkstopError : 19|1@1+ (1,0) [0|0] "" Vector__XXX
 SG_ APP_w019_ECU_Stack_Overflow : 18|1@1+ (1,0) [0|0] "" Vector__XXX
 SG_ APP_w018_ECU_Power_Issue : 17|1@1+ (1,0) [0|0] "" Vector__XXX
 SG_ APP_w017_Cam_Msg_MIA : 16|1@1+ (1,0) [0|0] "" Vector__XXX
 SG_ APP_w016_aeb_e_event : 15|1@1+ (1,0) [0|0] "" Vector__XXX
 SG_ APP_w015_Camera_Failsafes : 14|1@1+ (1,0) [0|0] "" Vector__XXX
 SG_ APP_w014_swAssert : 13|1@1+ (1,0) [0|0] "" Vector__XXX
 SG_ APP_w013_Cam_Watchdog : 12|1@1+ (1,0) [0|0] "" Vector__XXX
 SG_ APP_w012_Cam_BootFailure : 11|1@1+ (1,0) [0|0] "" Vector__XXX
 SG_ APP_w011_scaEvent : 10|1@1+ (1,0) [0|0] "" Vector__XXX
 SG_ APP_w010_radcCalibIssue : 9|1@1+ (1,0) [0|0] "" Vector__XXX
 SG_ APP_w009_aebFault : 8|1@1+ (1,0) [0|0] "" Vector__XXX
 SG_ APP_w008_parkDisabled : 7|1@1+ (1,0) [0|0] "" Vector__XXX
 SG_ APP_w007_ahlbDisabled : 6|1@1+ (1,0) [0|0] "" Vector__XXX
 SG_ APP_w006_aebCancelled : 5|1@1+ (1,0) [0|0] "" Vector__XXX
 SG_ APP_w005_fcwCancelled : 4|1@1+ (1,0) [0|0] "" Vector__XXX
 SG_ APP_w004_accDisabled : 3|1@1+ (1,0) [0|0] "" Vector__XXX
 SG_ APP_w003_isaDisabled : 2|1@1+ (1,0) [0|0] "" Vector__XXX
 SG_ APP_w002_ldwDisabled : 1|1@1+ (1,0) [0|0] "" Vector__XXX
 SG_ APP_w001_DEPRECATED : 0|1@1+ (1,0) [0|0] "" Vector__XXX

BO_ 811 APS_warningMatrix0: 8 Vector__XXX
 SG_ APS_w064_epasMia : 63|1@1+ (1,0) [0|0] "" Vector__XXX
 SG_ APS_w063_parkVersionMismatch : 62|1@1+ (1,0) [0|0] "" Vector__XXX
 SG_ APS_w062_radcAlignment : 61|1@1+ (1,0) [0|0] "" Vector__XXX
 SG_ APS_w061_tasMia : 60|1@1+ (1,0) [0|0] "" Vector__XXX
 SG_ APS_w060_fcw_event : 59|1@1+ (1,0) [0|0] "" Vector__XXX
 SG_ APS_w059_parkMia : 58|1@1+ (1,0) [0|0] "" Vector__XXX
 SG_ APS_w058_epbMia : 57|1@1+ (1,0) [0|0] "" Vector__XXX
 SG_ APS_w057_mcuMia : 56|1@1+ (1,0) [0|0] "" Vector__XXX
 SG_ APS_w056_diMia : 55|1@1+ (1,0) [0|0] "" Vector__XXX
 SG_ APS_w055_radcVersionMismatch : 54|1@1+ (1,0) [0|0] "" Vector__XXX
 SG_ APS_w054_camAutofix : 53|1@1+ (1,0) [0|0] "" Vector__XXX
 SG_ APS_w053_radcCommIssue : 52|1@1+ (1,0) [0|0] "" Vector__XXX
 SG_ APS_w052_radcSensorIssue : 51|1@1+ (1,0) [0|0] "" Vector__XXX
 SG_ APS_w051_radcEcuIssue : 50|1@1+ (1,0) [0|0] "" Vector__XXX
 SG_ APS_w050_aeb_event : 49|1@1+ (1,0) [0|0] "" Vector__XXX
 SG_ APS_w049_eyeqVersionMismatch : 48|1@1+ (1,0) [0|0] "" Vector__XXX
 SG_ APS_w048_DAS_Features_Disabled : 47|1@1+ (1,0) [0|0] "" Vector__XXX
 SG_ APS_w047_edrEvent : 46|1@1+ (1,0) [0|0] "" Vector__XXX
 SG_ APS_w046_eepromRecordAbsent : 45|1@1+ (1,0) [0|0] "" Vector__XXX
 SG_ APS_w045_radMia : 44|1@1+ (1,0) [0|0] "" Vector__XXX
 SG_ APS_w044_appMobileyeFailure : 43|1@1+ (1,0) [0|0] "" Vector__XXX
 SG_ APS_w043_camLongRunTime : 42|1@1+ (1,0) [0|0] "" Vector__XXX
 SG_ APS_w042_autopilotAborting : 41|1@1+ (1,0) [0|0] "" Vector__XXX
 SG_ APS_w041_autopilotRateSaturated : 40|1@1+ (1,0) [0|0] "" Vector__XXX
 SG_ APS_w040_autopilotAngleSaturated : 39|1@1+ (1,0) [0|0] "" Vector__XXX
 SG_ APS_w039_sdm_rcm_Mia : 38|1@1+ (1,0) [0|0] "" Vector__XXX
 SG_ APS_w038_camFailure : 37|1@1+ (1,0) [0|0] "" Vector__XXX
 SG_ APS_w037_camTacIssue : 36|1@1+ (1,0) [0|0] "" Vector__XXX
 SG_ APS_w036_bdyMia : 35|1@1+ (1,0) [0|0] "" Vector__XXX
 SG_ APS_w035_espMia : 34|1@1+ (1,0) [0|0] "" Vector__XXX
 SG_ APS_w034_sccmMia : 33|1@1+ (1,0) [0|0] "" Vector__XXX
 SG_ APS_w033_gtwMia : 32|1@1+ (1,0) [0|0] "" Vector__XXX
 SG_ APS_w032_canTxError : 31|1@1+ (1,0) [0|0] "" Vector__XXX
 SG_ APS_w031_canRxError : 30|1@1+ (1,0) [0|0] "" Vector__XXX
 SG_ APS_w030_Heater_Issue : 29|1@1+ (1,0) [0|0] "" Vector__XXX
 SG_ APS_w029_spi_tx_error : 28|1@1+ (1,0) [0|0] "" Vector__XXX
 SG_ APS_w028_spi_rx_error : 27|1@1+ (1,0) [0|0] "" Vector__XXX
 SG_ APS_w027_ECU_Reset_Fault : 26|1@1+ (1,0) [0|0] "" Vector__XXX
 SG_ APS_w026_ECU_timingIssue : 25|1@1+ (1,0) [0|0] "" Vector__XXX
 SG_ APS_w025_LC_Steering_Override : 24|1@1+ (1,0) [0|0] "" Vector__XXX
 SG_ APS_w024_ECU_Watchdog_Reset : 23|1@1+ (1,0) [0|0] "" Vector__XXX
 SG_ APS_w023_ECU_Cam_Statemismatc : 22|1@1+ (1,0) [0|0] "" Vector__XXX
 SG_ APS_w022_ECU_EEPROM_Failure : 21|1@1+ (1,0) [0|0] "" Vector__XXX
 SG_ APS_w021_ECU_Temperature_Issue : 20|1@1+ (1,0) [0|0] "" Vector__XXX
 SG_ APS_w020_ECU_checkstopError : 19|1@1+ (1,0) [0|0] "" Vector__XXX
 SG_ APS_w019_ECU_Stack_Overflow : 18|1@1+ (1,0) [0|0] "" Vector__XXX
 SG_ APS_w018_ECU_Power_Issue : 17|1@1+ (1,0) [0|0] "" Vector__XXX
 SG_ APS_w017_Cam_Msg_MIA : 16|1@1+ (1,0) [0|0] "" Vector__XXX
 SG_ APS_w016_aeb_e_event : 15|1@1+ (1,0) [0|0] "" Vector__XXX
 SG_ APS_w015_Camera_Failsafes : 14|1@1+ (1,0) [0|0] "" Vector__XXX
 SG_ APS_w014_swAssert : 13|1@1+ (1,0) [0|0] "" Vector__XXX
 SG_ APS_w013_Cam_Watchdog : 12|1@1+ (1,0) [0|0] "" Vector__XXX
 SG_ APS_w012_Cam_BootFailure : 11|1@1+ (1,0) [0|0] "" Vector__XXX
 SG_ APS_w011_scaEvent : 10|1@1+ (1,0) [0|0] "" Vector__XXX
 SG_ APS_w010_radcCalibIssue : 9|1@1+ (1,0) [0|0] "" Vector__XXX
 SG_ APS_w009_aebFault : 8|1@1+ (1,0) [0|0] "" Vector__XXX
 SG_ APS_w008_parkDisabled : 7|1@1+ (1,0) [0|0] "" Vector__XXX
 SG_ APS_w007_ahlbDisabled : 6|1@1+ (1,0) [0|0] "" Vector__XXX
 SG_ APS_w006_aebCancelled : 5|1@1+ (1,0) [0|0] "" Vector__XXX
 SG_ APS_w005_fcwCancelled : 4|1@1+ (1,0) [0|0] "" Vector__XXX
 SG_ APS_w004_accDisabled : 3|1@1+ (1,0) [0|0] "" Vector__XXX
 SG_ APS_w003_isaDisabled : 2|1@1+ (1,0) [0|0] "" Vector__XXX
 SG_ APS_w002_ldwDisabled : 1|1@1+ (1,0) [0|0] "" Vector__XXX
 SG_ APS_w001_DEPRECATED : 0|1@1+ (1,0) [0|0] "" Vector__XXX

BO_ 813 IBST_info: 8 Vector__XXX
 SG_ IBST_infoSubUsageID m11 : 48|16@1+ (1,0) [0|0] "" Vector__XXX
 SG_ IBST_infoComponentID m10 : 55|16@0+ (1,0) [0|0] "" Vector__XXX
 SG_ IBST_infoApplicationCRC m13 : 32|32@1+ (1,0) [0|0] "" Vector__XXX
 SG_ IBST_infoBootloaderCRC m20 : 32|32@1+ (1,0) [0|0] "" Vector__XXX
 SG_ IBST_infoSubcomponent1 m16 : 32|32@1+ (1,0) [0|0] "" Vector__XXX
 SG_ IBST_infoUsageID m11 : 32|16@1+ (1,0) [0|0] "" Vector__XXX
 SG_ IBST_infoVariantCRC m22 : 32|32@1+ (1,0) [0|0] "" Vector__XXX
 SG_ IBST_infoAssemblyID m11 : 24|8@1+ (1,0) [0|0] "" Vector__XXX
 SG_ IBST_infoPcbaID m11 : 16|8@1+ (1,0) [0|0] "" Vector__XXX
 SG_ IBST_infoBootUdsProtoVersion m20 : 8|8@1+ (1,0) [0|0] "" Vector__XXX
 SG_ IBST_infoBuildType m10 : 8|8@1+ (1,0) [0|0] "" Vector__XXX
 SG_ IBST_infoIndex M : 0|8@1+ (1,0) [0|0] "" Vector__XXX

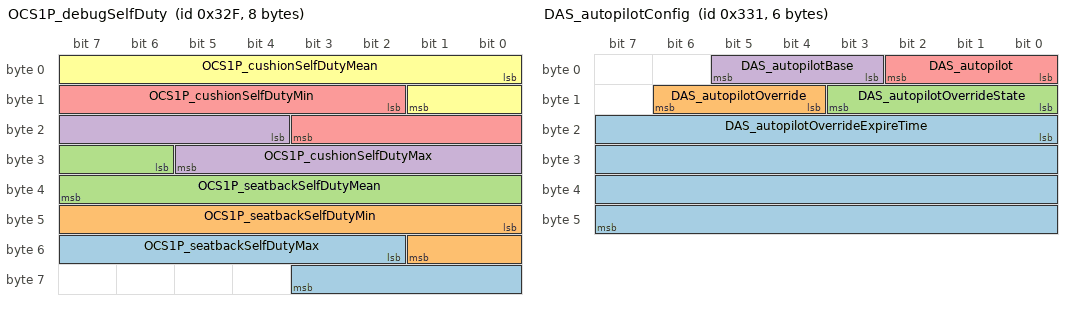
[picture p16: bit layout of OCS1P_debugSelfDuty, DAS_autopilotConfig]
BO_ 815 OCS1P_debugSelfDuty: 8 Vector__XXX
 SG_ OCS1P_seatbackSelfDutyMax : 50|10@1+ (0.09775171065493646,0) [0|0] "" Vector__XXX
 SG_ OCS1P_seatbackSelfDutyMin : 40|10@1+ (0.09775171065493646,0) [0|0] "" Vector__XXX
 SG_ OCS1P_seatbackSelfDutyMean : 30|10@1+ (0.09775171065493646,0) [0|0] "" Vector__XXX
 SG_ OCS1P_cushionSelfDutyMax : 20|10@1+ (0.09775171065493646,0) [0|0] "" Vector__XXX
 SG_ OCS1P_cushionSelfDutyMin : 10|10@1+ (0.09775171065493646,0) [0|0] "" Vector__XXX
 SG_ OCS1P_cushionSelfDutyMean : 0|10@1+ (0.09775171065493646,0) [0|0] "" Vector__XXX

BO_ 817 DAS_autopilotConfig: 6 Vector__XXX
 SG_ DAS_autopilotOverrideExpireTime : 16|32@1+ (1,0) [0|0] "" Vector__XXX
 SG_ DAS_autopilotOverride : 12|3@1+ (1,0) [0|0] "" Vector__XXX
 SG_ DAS_autopilotOverrideState : 8|4@1+ (1,0) [0|0] "" Vector__XXX
 SG_ DAS_autopilotBase : 3|3@1+ (1,0) [0|0] "" Vector__XXX
 SG_ DAS_autopilot : 0|3@1+ (1,0) [0|0] "" Vector__XXX

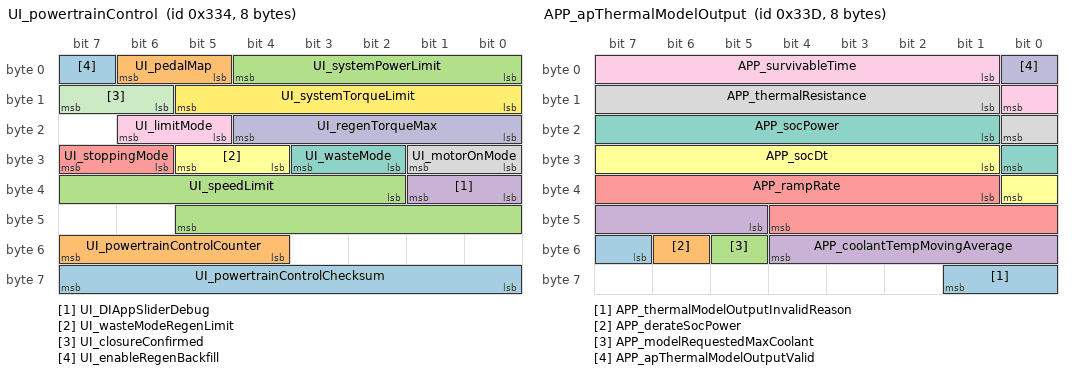
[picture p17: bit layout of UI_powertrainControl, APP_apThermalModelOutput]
BO_ 820 UI_powertrainControl: 8 Vector__XXX
 SG_ UI_powertrainControlChecksum : 56|8@1+ (1,0) [0|0] "" Vector__XXX
 SG_ UI_powertrainControlCounter : 52|4@1+ (1,0) [0|0] "" Vector__XXX
 SG_ UI_speedLimit : 34|12@1+ (0.1,0) [0|0] "" Vector__XXX
 SG_ UI_DIAppSliderDebug : 32|2@1+ (1,0) [0|0] "" Vector__XXX
 SG_ UI_stoppingMode : 30|2@1+ (1,0) [0|0] "" Vector__XXX
 SG_ UI_wasteModeRegenLimit : 28|2@1+ (1,0) [0|0] "" Vector__XXX
 SG_ UI_wasteMode : 26|2@1+ (1,0) [0|0] "" Vector__XXX
 SG_ UI_motorOnMode : 24|2@1+ (1,0) [0|0] "" Vector__XXX
 SG_ UI_limitMode : 21|2@1+ (1,0) [0|0] "" Vector__XXX
 SG_ UI_regenTorqueMax : 16|5@1+ (5,0) [0|0] "" Vector__XXX
 SG_ UI_closureConfirmed : 14|2@1+ (1,0) [0|0] "" Vector__XXX
 SG_ UI_systemTorqueLimit : 8|6@1+ (150,1000) [0|0] "" Vector__XXX
 SG_ UI_enableRegenBackfill : 7|1@1+ (1,0) [0|0] "" Vector__XXX
 SG_ UI_pedalMap : 5|2@1+ (1,0) [0|0] "" Vector__XXX
 SG_ UI_systemPowerLimit : 0|5@1+ (20,20) [0|0] "" Vector__XXX

BO_ 829 APP_apThermalModelOutput: 8 Vector__XXX
 SG_ APP_thermalModelOutputInvalidReason : 55|3@1+ (1,0) [0|0] "" Vector__XXX
 SG_ APP_derateSocPower : 54|1@1+ (1,0) [0|0] "" Vector__XXX
 SG_ APP_modelRequestedMaxCoolant : 53|1@1+ (1,0) [0|0] "" Vector__XXX
 SG_ APP_coolantTempMovingAverage : 45|8@1- (0.5,30) [0|0] "" Vector__XXX
 SG_ APP_rampRate : 33|12@1- (0.01,0) [0|0] "" Vector__XXX
 SG_ APP_socDt : 25|8@1+ (0.3,0) [0|0] "" Vector__XXX
 SG_ APP_socPower : 17|8@1+ (0.4,0) [0|0] "" Vector__XXX
 SG_ APP_thermalResistance : 9|8@1+ (0.04,0) [0|0] "" Vector__XXX
 SG_ APP_survivableTime : 1|8@1+ (0.1,0) [0|0] "" Vector__XXX
 SG_ APP_apThermalModelOutputValid : 0|1@1+ (1,0) [0|0] "" Vector__XXX

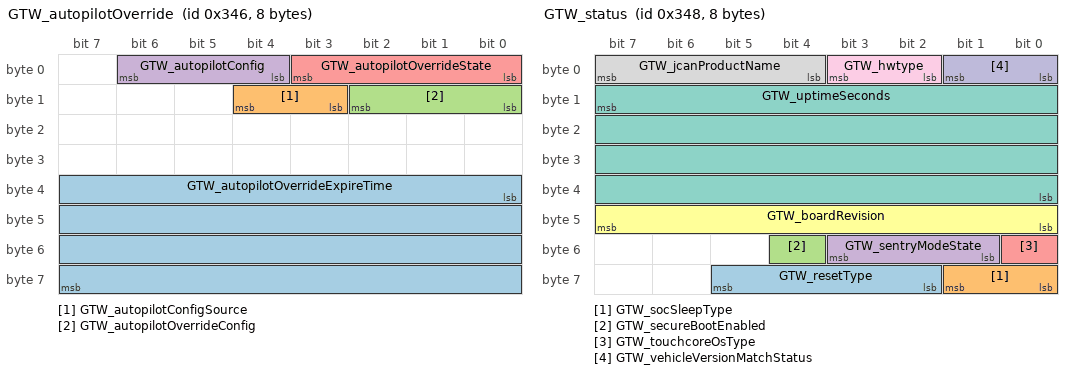
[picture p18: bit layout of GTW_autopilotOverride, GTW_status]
BO_ 838 GTW_autopilotOverride: 8 Vector__XXX
 SG_ GTW_autopilotOverrideExpireTime : 32|32@1+ (1,0) [0|0] "" Vector__XXX
 SG_ GTW_autopilotConfigSource : 11|2@1+ (1,0) [0|0] "" Vector__XXX
 SG_ GTW_autopilotOverrideConfig : 8|3@1+ (1,0) [0|0] "" Vector__XXX
 SG_ GTW_autopilotConfig : 4|3@1+ (1,0) [0|0] "" Vector__XXX
 SG_ GTW_autopilotOverrideState : 0|4@1+ (1,0) [0|0] "" Vector__XXX

BO_ 840 GTW_status: 8 Vector__XXX
 SG_ GTW_resetType : 58|4@1+ (1,0) [0|0] "" Vector__XXX
 SG_ GTW_socSleepType : 56|2@1+ (1,0) [0|0] "" Vector__XXX
 SG_ GTW_secureBootEnabled : 52|1@1+ (1,0) [0|0] "" Vector__XXX
 SG_ GTW_sentryModeState : 49|3@1+ (1,0) [0|0] "" Vector__XXX
 SG_ GTW_touchcoreOsType : 48|1@1+ (1,0) [0|0] "" Vector__XXX
 SG_ GTW_boardRevision : 40|8@1+ (1,0) [0|0] "" Vector__XXX
 SG_ GTW_uptimeSeconds : 15|32@0+ (1,0) [0|0] "" Vector__XXX
 SG_ GTW_jcanProductName : 4|4@1+ (1,0) [0|0] "" Vector__XXX
 SG_ GTW_hwtype : 2|2@1+ (1,0) [0|0] "" Vector__XXX
 SG_ GTW_vehicleVersionMatchStatus : 0|2@1+ (1,0) [0|0] "" Vector__XXX

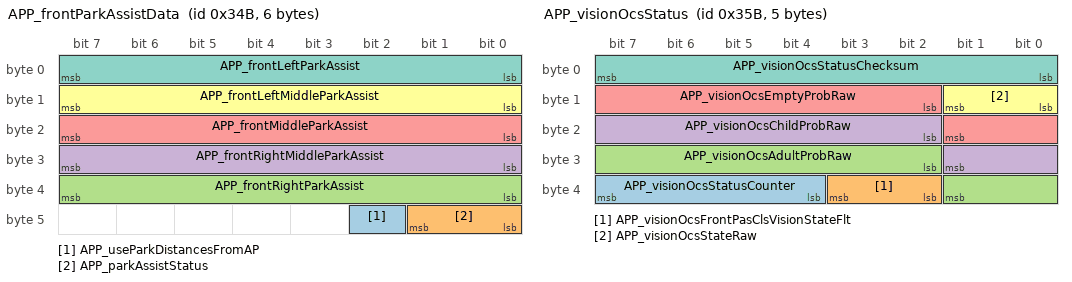
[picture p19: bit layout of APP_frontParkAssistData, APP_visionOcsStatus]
BO_ 843 APP_frontParkAssistData: 6 Vector__XXX
 SG_ APP_useParkDistancesFromAP : 42|1@1+ (1,0) [0|0] "" Vector__XXX
 SG_ APP_parkAssistStatus : 40|2@1+ (1,0) [0|0] "" Vector__XXX
 SG_ APP_frontRightParkAssist : 32|8@1+ (1,0) [0|0] "" Vector__XXX
 SG_ APP_frontRightMiddleParkAssist : 24|8@1+ (1,0) [0|0] "" Vector__XXX
 SG_ APP_frontMiddleParkAssist : 16|8@1+ (1,0) [0|0] "" Vector__XXX
 SG_ APP_frontLeftMiddleParkAssist : 8|8@1+ (1,0) [0|0] "" Vector__XXX
 SG_ APP_frontLeftParkAssist : 0|8@1+ (1,0) [0|0] "" Vector__XXX

BO_ 847 OCS1P_debugCushionSelfCNTComp: 8 Vector__XXX
 SG_ OCS1P_deltaCapCushionSelf : 48|16@1- (0.0025,0) [0|0] "" Vector__XXX
 SG_ OCS1P_deltaFreqCushionSelf : 32|16@1- (1,0) [0|0] "" Vector__XXX
 SG_ OCS1P_cushionSelfCNTCap : 16|16@1+ (0.005,0) [0|0] "" Vector__XXX
 SG_ OCS1P_cushionSelfCNTFreqComp : 0|16@1+ (1,0) [0|0] "" Vector__XXX

BO_ 848 APS_warningMatrix3: 8 Vector__XXX
 SG_ APS_w255_bootHealth : 62|1@1+ (1,0) [0|0] "" Vector__XXX
 SG_ APS_w254_sleepStateTimeout : 61|1@1+ (1,0) [0|0] "" Vector__XXX
 SG_ APS_w253_powerStateTimeout : 60|1@1+ (1,0) [0|0] "" Vector__XXX
 SG_ APS_w252_ethSwitchPortLinkDown : 59|1@1+ (1,0) [0|0] "" Vector__XXX
 SG_ APS_w251_ethloopSwitchMemUsageTooHighPort3 : 58|1@1+ (1,0) [0|0] "" Vector__XXX
 SG_ APS_w250_ethloopSwitchMemUsageTooHighPort2 : 57|1@1+ (1,0) [0|0] "" Vector__XXX
 SG_ APS_w249_ufsFailures : 56|1@1+ (1,0) [0|0] "" Vector__XXX
 SG_ APS_w248_ethloopSwitchPoorSqi : 55|1@1+ (1,0) [0|0] "" Vector__XXX
 SG_ APS_w247_ethernetFrameError : 54|1@1+ (1,0) [0|0] "" Vector__XXX
 SG_ APS_w246_ethloopSwitchPortLinkDown : 53|1@1+ (1,0) [0|0] "" Vector__XXX
 SG_ APS_w245_eloopRxFromUnexpectedSourceMAC : 52|1@1+ (1,0) [0|0] "" Vector__XXX
 SG_ APS_w244_gpuHWFaultStatus : 51|1@1+ (1,0) [0|0] "" Vector__XXX
 SG_ APS_w243_tripHWErrorStatus : 50|1@1+ (1,0) [0|0] "" Vector__XXX
 SG_ APS_w242_tripMBISTFailure : 49|1@1+ (1,0) [0|0] "" Vector__XXX
 SG_ APS_w241_ddrInitFailures : 48|1@1+ (1,0) [0|0] "" Vector__XXX
 SG_ APS_w238_resetReason : 45|1@1+ (1,0) [0|0] "" Vector__XXX
 SG_ APS_w237_faultMgrEventDetected : 44|1@1+ (1,0) [0|0] "" Vector__XXX
 SG_ APS_w236_canSharedMemError : 43|1@1+ (1,0) [0|0] "" Vector__XXX
 SG_ APS_w235_a72LoopDetected : 42|1@1+ (1,0) [0|0] "" Vector__XXX
 SG_ APS_w232_laneChangeRequested : 39|1@1+ (1,0) [0|0] "" Vector__XXX
 SG_ APS_w231_idfEvent : 38|1@1+ (1,0) [0|0] "" Vector__XXX
 SG_ APS_w230_alcUltrasoundBlocked : 37|1@1+ (1,0) [0|0] "" Vector__XXX
 SG_ APS_w229_alcUltrasoundDamaged : 36|1@1+ (1,0) [0|0] "" Vector__XXX
 SG_ APS_w228_DEPRECATED : 35|1@1+ (1,0) [0|0] "" Vector__XXX
 SG_ APS_w227_virtualWallBlocked : 34|1@1+ (1,0) [0|0] "" Vector__XXX
 SG_ APS_w226_lcCamCalNeededSpeedLmt : 33|1@1+ (1,0) [0|0] "" Vector__XXX
 SG_ APS_w225_lcDegradedVisSpeedLmt : 32|1@1+ (1,0) [0|0] "" Vector__XXX
 SG_ APS_w224_accCameraCalibration : 31|1@1+ (1,0) [0|0] "" Vector__XXX
 SG_ APS_w223_accObjectInPath : 30|1@1+ (1,0) [0|0] "" Vector__XXX
 SG_ APS_w222_accCameraBlind : 29|1@1+ (1,0) [0|0] "" Vector__XXX
 SG_ APS_w221_accRadarBlind : 28|1@1+ (1,0) [0|0] "" Vector__XXX
 SG_ APS_w220_lcTempUnavailableRoad : 27|1@1+ (1,0) [0|0] "" Vector__XXX
 SG_ APS_w219_lcTempUnavailableSpeed : 26|1@1+ (1,0) [0|0] "" Vector__XXX
 SG_ APS_w218_lcSpeedExceededLimit : 25|1@1+ (1,0) [0|0] "" Vector__XXX
 SG_ APS_w217_lcUnavailableSpeeding : 24|1@1+ (1,0) [0|0] "" Vector__XXX
 SG_ APS_w216_driverOverriding : 23|1@1+ (1,0) [0|0] "" Vector__XXX
 SG_ APS_w215_contDriverNotIntracting : 22|1@1+ (1,0) [0|0] "" Vector__XXX
 SG_ APS_w214_driverNotIntracting : 21|1@1+ (1,0) [0|0] "" Vector__XXX
 SG_ APS_w213_autosteerStruckOut : 20|1@1+ (1,0) [0|0] "" Vector__XXX
 SG_ APS_w212_lcUnavailableStrikeOut : 19|1@1+ (1,0) [0|0] "" Vector__XXX
 SG_ APS_w211_accNoSeatBelt : 18|1@1+ (1,0) [0|0] "" Vector__XXX
 SG_ APS_w210_camObstrcted : 17|1@1+ (1,0) [0|0] "" Vector__XXX
 SG_ APS_w209_autoSummonRequest : 16|1@1+ (1,0) [0|0] "" Vector__XXX
 SG_ APS_w208_rackDetected : 15|1@1+ (1,0) [0|0] "" Vector__XXX
 SG_ APS_w207_autosteerUnavailable : 14|1@1+ (1,0) [0|0] "" Vector__XXX
 SG_ APS_w206_autosteerNotEnabled : 13|1@1+ (1,0) [0|0] "" Vector__XXX
 SG_ APS_w205_apcFinalRear : 12|1@1+ (1,0) [0|0] "" Vector__XXX
 SG_ APS_w204_apcFinalFront : 11|1@1+ (1,0) [0|0] "" Vector__XXX
 SG_ APS_w203_apcActivation : 10|1@1+ (1,0) [0|0] "" Vector__XXX
 SG_ APS_w202_scwNoisyEnvironment : 9|1@1+ (1,0) [0|0] "" Vector__XXX
 SG_ APS_w201_lcAborting : 8|1@1+ (1,0) [0|0] "" Vector__XXX
 SG_ APS_w200_lcSlowdown : 7|1@1+ (1,0) [0|0] "" Vector__XXX
 SG_ APS_w199_apcAbort : 6|1@1+ (1,0) [0|0] "" Vector__XXX
 SG_ APS_w198_tsrUnavailable : 5|1@1+ (1,0) [0|0] "" Vector__XXX
 SG_ APS_w197_redLightWarning : 4|1@1+ (1,0) [0|0] "" Vector__XXX
 SG_ APS_w196_stopSignWarning : 3|1@1+ (1,0) [0|0] "" Vector__XXX
 SG_ APS_w195_scwUnavailable : 2|1@1+ (1,0) [0|0] "" Vector__XXX
 SG_ APS_w194_accDriverResumeRqrd : 1|1@1+ (1,0) [0|0] "" Vector__XXX
 SG_ APS_w193_camWindshieldUnclean : 0|1@1+ (1,0) [0|0] "" Vector__XXX

BO_ 849 RCM_info: 8 Vector__XXX
 SG_ RCM_infoComponentID m10 : 48|16@1+ (1,0) [0|0] "" Vector__XXX
 SG_ RCM_infoApplicationCRC m13 : 32|32@1+ (1,0) [0|0] "" Vector__XXX
 SG_ RCM_infoBootloaderCRC m20 : 32|32@1+ (1,0) [0|0] "" Vector__XXX
 SG_ RCM_infoUsageID m11 : 32|16@1+ (1,0) [0|0] "" Vector__XXX
 SG_ RCM_infoVariantCRC m22 : 32|32@1+ (1,0) [0|0] "" Vector__XXX
 SG_ RCM_infoAssemblyID m11 : 24|8@1+ (1,0) [0|0] "" Vector__XXX
 SG_ RCM_infoPcbaID m11 : 16|8@1+ (1,0) [0|0] "" Vector__XXX
 SG_ RCM_infoAlgoCalID m22 : 8|8@1+ (1,0) [0|0] "" Vector__XXX
 SG_ RCM_infoBootUdsProtoVersion m20 : 8|8@1+ (1,0) [0|0] "" Vector__XXX
 SG_ RCM_infoBuildType m10 : 8|8@1+ (1,0) [0|0] "" Vector__XXX
 SG_ RCM_infoIndex M : 0|8@1+ (1,0) [0|0] "" Vector__XXX

BO_ 851 UI_status: 8 Vector__XXX
 SG_ UI_cpuTemperature : 56|8@1- (1,40) [0|0] "" Vector__XXX
 SG_ UI_pcbTemperature : 48|8@1- (1,40) [0|0] "" Vector__XXX
 SG_ UI_trailerModeTelltale : 45|2@1+ (1,0) [0|0] "" Vector__XXX
 SG_ UI_cellSignalBars : 42|3@1+ (1,0) [0|0] "" Vector__XXX
 SG_ UI_cameraActive : 41|1@1+ (1,0) [0|0] "" Vector__XXX
 SG_ UI_developmentCar : 40|1@1+ (1,0) [0|0] "" Vector__XXX
 SG_ UI_falseTouchCounter : 32|8@1+ (1,0) [0|0] "" Vector__XXX
 SG_ UI_cellReceiverPower : 24|8@1+ (1,-128) [0|0] "" Vector__XXX
 SG_ UI_cellNetworkTechnology : 19|4@1+ (1,0) [0|0] "" Vector__XXX
 SG_ UI_radioActive : 18|1@1+ (1,0) [0|0] "" Vector__XXX
 SG_ UI_screenshotActive : 17|1@1+ (1,0) [0|0] "" Vector__XXX
 SG_ UI_gpsActive : 16|1@1+ (1,0) [0|0] "" Vector__XXX
 SG_ UI_factoryReset : 14|2@1+ (1,0) [0|0] "" Vector__XXX
 SG_ UI_autopilotTrial : 12|2@1+ (1,0) [0|0] "" Vector__XXX
 SG_ UI_vpnActive : 11|1@1+ (1,0) [0|0] "" Vector__XXX
 SG_ UI_cellConnected : 10|1@1+ (1,0) [0|0] "" Vector__XXX
 SG_ UI_readyForDrive : 9|1@1+ (1,0) [0|0] "" Vector__XXX
 SG_ UI_systemActive : 8|1@1+ (1,0) [0|0] "" Vector__XXX
 SG_ UI_wifiConnected : 7|1@1+ (1,0) [0|0] "" Vector__XXX
 SG_ UI_wifiActive : 6|1@1+ (1,0) [0|0] "" Vector__XXX
 SG_ UI_displayOn : 5|1@1+ (1,0) [0|0] "" Vector__XXX
 SG_ UI_displayReady : 4|1@1+ (1,0) [0|0] "" Vector__XXX
 SG_ UI_cellActive : 3|1@1+ (1,0) [0|0] "" Vector__XXX
 SG_ UI_bluetoothActive : 2|1@1+ (1,0) [0|0] "" Vector__XXX
 SG_ UI_audioActive : 1|1@1+ (1,0) [0|0] "" Vector__XXX
 SG_ UI_touchActive : 0|1@1+ (1,0) [0|0] "" Vector__XXX

BO_ 852 UI_uiHealthStatus: 6 Vector__XXX
 SG_ UI_rearDisplayCompositorOk : 31|1@1+ (1,0) [0|0] "" Vector__XXX
 SG_ UI_rearDisplayWindowManagerOk : 30|1@1+ (1,0) [0|0] "" Vector__XXX
 SG_ UI_rearDisplayHardwareOk : 29|1@1+ (1,0) [0|0] "" Vector__XXX
 SG_ UI_rearDisplayCrtcOk : 28|1@1+ (1,0) [0|0] "" Vector__XXX
 SG_ UI_rearDisplaySM : 25|3@1+ (1,0) [0|0] "" Vector__XXX
 SG_ UI_rearDisplayPowerOn : 24|1@1+ (1,0) [0|0] "" Vector__XXX
 SG_ UI_rearDisplayRunning : 23|1@1+ (1,0) [0|0] "" Vector__XXX
 SG_ UI_autonomyDASServerStatus : 21|2@1+ (1,0) [0|0] "" Vector__XXX
 SG_ UI_autonomyQtCarRearStatus : 19|2@1+ (1,0) [0|0] "" Vector__XXX
 SG_ UI_autonomyQtCarStatus : 17|2@1+ (1,0) [0|0] "" Vector__XXX
 SG_ UI_autonomyConnectivtyHWOk : 16|1@1+ (1,0) [0|0] "" Vector__XXX
 SG_ UI_autonomyConnectivityStatus : 14|2@1+ (1,0) [0|0] "" Vector__XXX
 SG_ UI_autonomyRearDispStatus : 12|2@1+ (1,0) [0|0] "" Vector__XXX
 SG_ UI_autonomyCenterDispStatus : 10|2@1+ (1,0) [0|0] "" Vector__XXX
 SG_ UI_apVisualizationOk : 9|1@1+ (1,0) [0|0] "" Vector__XXX
 SG_ UI_centerDisplayCompositorOk : 8|1@1+ (1,0) [0|0] "" Vector__XXX
 SG_ UI_centerDisplayWindowManagerOk : 7|1@1+ (1,0) [0|0] "" Vector__XXX
 SG_ UI_centerDisplayHardwareOk : 6|1@1+ (1,0) [0|0] "" Vector__XXX
 SG_ UI_centerDisplayCrtcOk : 5|1@1+ (1,0) [0|0] "" Vector__XXX
 SG_ UI_centerDisplayPowerOn : 4|1@1+ (1,0) [0|0] "" Vector__XXX
 SG_ UI_centerDisplaySM : 1|3@1+ (1,0) [0|0] "" Vector__XXX
 SG_ UI_centerDisplayRunning : 0|1@1+ (1,0) [0|0] "" Vector__XXX

BO_ 859 APP_visionOcsStatus: 5 Vector__XXX
 SG_ APP_visionOcsStatusCounter : 36|4@1+ (1,0) [0|0] "" Vector__XXX
 SG_ APP_visionOcsFrontPasClsVisionStateFlt : 34|2@1+ (1,0) [0|0] "" Vector__XXX
 SG_ APP_visionOcsAdultProbRaw : 26|8@1+ (0.004,0) [0|0] "" Vector__XXX
 SG_ APP_visionOcsChildProbRaw : 18|8@1+ (0.004,0) [0|0] "" Vector__XXX
 SG_ APP_visionOcsEmptyProbRaw : 10|8@1+ (0.004,0) [0|0] "" Vector__XXX
 SG_ APP_visionOcsStateRaw : 8|2@1+ (1,0) [0|0] "" Vector__XXX
 SG_ APP_visionOcsStatusChecksum : 0|8@1+ (1,0) [0|0] "" Vector__XXX

BO_ 873 APP_warningMatrix1: 8 Vector__XXX
 SG_ APP_w106_torsionBarOffset : 41|1@1+ (1,0) [0|0] "" Vector__XXX
 SG_ APP_w105_DEPRECATED : 40|1@1+ (1,0) [0|0] "" Vector__XXX
 SG_ APP_w104_DEPRECATED : 39|1@1+ (1,0) [0|0] "" Vector__XXX
 SG_ APP_w103_robExperimentalAEB : 38|1@1+ (1,0) [0|0] "" Vector__XXX
 SG_ APP_w102_DEPRECATED : 37|1@1+ (1,0) [0|0] "" Vector__XXX
 SG_ APP_w101_DEPRECATED : 36|1@1+ (1,0) [0|0] "" Vector__XXX
 SG_ APP_w100_DEPRECATED : 35|1@1+ (1,0) [0|0] "" Vector__XXX
 SG_ APP_w099_DEPRECATED : 34|1@1+ (1,0) [0|0] "" Vector__XXX
 SG_ APP_w098_DEPRECATED : 33|1@1+ (1,0) [0|0] "" Vector__XXX
 SG_ APP_w097_DEPRECATED : 32|1@1+ (1,0) [0|0] "" Vector__XXX
 SG_ APP_w096_DEPRECATED : 31|1@1+ (1,0) [0|0] "" Vector__XXX
 SG_ APP_w095_DEPRECATED : 30|1@1+ (1,0) [0|0] "" Vector__XXX
 SG_ APP_w094_DEPRECATED : 29|1@1+ (1,0) [0|0] "" Vector__XXX
 SG_ APP_w093_DEPRECATED : 28|1@1+ (1,0) [0|0] "" Vector__XXX
 SG_ APP_w092_DEPRECATED : 27|1@1+ (1,0) [0|0] "" Vector__XXX
 SG_ APP_w091_DEPRECATED : 26|1@1+ (1,0) [0|0] "" Vector__XXX
 SG_ APP_w090_DEPRECATED : 25|1@1+ (1,0) [0|0] "" Vector__XXX
 SG_ APP_w089_DEPRECATED : 24|1@1+ (1,0) [0|0] "" Vector__XXX
 SG_ APP_w088_DEPRECATED : 23|1@1+ (1,0) [0|0] "" Vector__XXX
 SG_ APP_w087_DEPRECATED : 22|1@1+ (1,0) [0|0] "" Vector__XXX
 SG_ APP_w086_robCollision : 21|1@1+ (1,0) [0|0] "" Vector__XXX
 SG_ APP_w085_pmmSteering : 20|1@1+ (1,0) [0|0] "" Vector__XXX
 SG_ APP_w084_pmmIPSO : 19|1@1+ (1,0) [0|0] "" Vector__XXX
 SG_ APP_w083_inPathRADObject : 18|1@1+ (1,0) [0|0] "" Vector__XXX
 SG_ APP_w082_inPathFSviolation : 17|1@1+ (1,0) [0|0] "" Vector__XXX
 SG_ APP_w081_pmmActiveBraking : 16|1@1+ (1,0) [0|0] "" Vector__XXX
 SG_ APP_w080_accFailedActivation : 15|1@1+ (1,0) [0|0] "" Vector__XXX
 SG_ APP_w079_edrAvailable : 14|1@1+ (1,0) [0|0] "" Vector__XXX
 SG_ APP_w078_pmmActive2 : 13|1@1+ (1,0) [0|0] "" Vector__XXX
 SG_ APP_w077_pmmActive : 12|1@1+ (1,0) [0|0] "" Vector__XXX
 SG_ APP_w076_mobilEyeSetC : 11|1@1+ (1,0) [0|0] "" Vector__XXX
 SG_ APP_w075_scMia : 10|1@1+ (1,0) [0|0] "" Vector__XXX
 SG_ APP_w074_inPathStationaryObst : 9|1@1+ (1,0) [0|0] "" Vector__XXX
 SG_ APP_w073_issueEscalatedLDW : 8|1@1+ (1,0) [0|0] "" Vector__XXX
 SG_ APP_w072_selfparkComplete : 7|1@1+ (1,0) [0|0] "" Vector__XXX
 SG_ APP_w071_selfparkStarted : 6|1@1+ (1,0) [0|0] "" Vector__XXX
 SG_ APP_w070_apcIncompleteCal : 5|1@1+ (1,0) [0|0] "" Vector__XXX
 SG_ APP_w069_apcSpaceMasked : 4|1@1+ (1,0) [0|0] "" Vector__XXX
 SG_ APP_w068_vlInconsistency : 3|1@1+ (1,0) [0|0] "" Vector__XXX
 SG_ APP_w067_steeringAlignment : 2|1@1+ (1,0) [0|0] "" Vector__XXX
 SG_ APP_w066_deserializerLockLost : 1|1@1+ (1,0) [0|0] "" Vector__XXX
 SG_ APP_w065_deserializerOvercurrent : 0|1@1+ (1,0) [0|0] "" Vector__XXX

CM_ "Legacy Model 3/Y, chassis bus (DashKit bus 0). One DBC per bus: an id can be a different message on each. Messages DashPilot reads keep the definitions of bus_1_tesla_vehicle.dbc, except DI_speed (full layout: 9-bit DI_uiSpeed, units at bit 33) and, not read by the app today, BMS_chgPowerAvailable (39|12) and VCRIGHT_logging1HzIndex (5 bits). The others come from the ESP32-DualCAN project (Model3_CH.dbc / Model3_VEH.dbc, github.com/dzid26, CERN-OHL-W v2: this file stays under that licence), as each message comment says. Checked against full-bus recordings of a 2023 Model Y RWD (78 min, 2026-11-20). UNK_ messages: seen on the car, no public definition, named after their id.";
CM_ BO_ 49 "ESP32-DualCAN Model3_CH. Seen on this car: 8-byte frames; fit good (bits covered 92%, mux 100%, ranges 100%).";
CM_ BO_ 81 "ESP32-DualCAN Model3_CH. Seen on this car: 8-byte frames; fit good (bits covered 92%, mux 100%, ranges 100%).";
CM_ BO_ 82 "ESP32-DualCAN Model3_CH. Seen on this car: 8-byte frames; fit ok (bits covered 100%, mux 100%, ranges 100%).";
CM_ BO_ 257 "ESP32-DualCAN Model3_CH. Seen on this car: 8-byte frames; fit good (bits covered 100%, mux 100%, ranges 100%, checksum 100%).";
CM_ BO_ 258 "DashKit DBC. Seen on this car: 8-byte frames; fit good (bits covered 89%, mux 100%, ranges 100%). read by the app or firmware; DashKit names kept.";
CM_ BO_ 259 "DashKit DBC. Seen on this car: 8-byte frames; fit good (bits covered 98%, mux 100%, ranges 100%). read by the app or firmware; DashKit names kept.";
CM_ BO_ 264 "ESP32-DualCAN Model3_CH. Seen on this car: 8-byte frames; fit good (bits covered 100%, mux 100%, ranges 100%, checksum 100%).";
CM_ BO_ 273 "ESP32-DualCAN Model3_CH. Seen on this car: 8-byte frames; fit good (bits covered 100%, mux 100%, ranges 100%, checksum 100%). read by the app or firmware.";
CM_ BO_ 305 "ESP32-DualCAN Model3_CH. Seen on this car: 8-byte frames; fit good (bits covered 100%, mux 100%, ranges 100%, checksum 100%).";
CM_ BO_ 321 "ESP32-DualCAN Model3_CH. Seen on this car: 8-byte frames; fit good (bits covered 100%, mux 100%, ranges 100%, checksum 100%).";
CM_ BO_ 325 "ESP32-DualCAN Model3_CH. Seen on this car: 8-byte frames; fit good (bits covered 100%, mux 100%, ranges 100%, checksum 100%).";
CM_ BO_ 326 "ESP32-DualCAN Model3_CH. Seen on this car: 8-byte frames; fit good (bits covered 88%, mux 100%, ranges 100%, checksum 100%).";
CM_ BO_ 329 "ESP32-DualCAN Model3_CH. Seen on this car: 8-byte frames; fit good (bits covered 100%, mux 100%, ranges 100%, checksum 100%).";
CM_ BO_ 341 "ESP32-DualCAN Model3_CH. Seen on this car: 8-byte frames; fit good (bits covered 100%, mux 100%, ranges 100%, checksum 100%).";
CM_ BO_ 373 "ESP32-DualCAN Model3_CH. Seen on this car: 8-byte frames; fit good (bits covered 100%, mux 100%, ranges 100%, checksum 100%).";
CM_ BO_ 389 "ESP32-DualCAN Model3_CH. Seen on this car: 8-byte frames; fit good (bits covered 100%, mux 100%, ranges 100%, checksum 100%).";
CM_ BO_ 454 "ESP32-DualCAN Model3_CH. Seen on this car: 6-byte frames; fit ok (bits covered 100%, mux 100%, ranges 100%).";
CM_ BO_ 521 "ESP32-DualCAN Model3_CH. Seen on this car: 8-byte frames; fit ok (bits covered 100%, mux 0%, ranges 100%, checksum 100%).";
CM_ BO_ 522 "ESP32-DualCAN Model3_CH. Seen on this car: 6-byte frames; fit ok (bits covered 100%, mux 100%, ranges 100%, checksum 100%).";
CM_ BO_ 529 "ESP32-DualCAN Model3_CH. Seen on this car: 6-byte frames; fit ok (bits covered 100%, mux 100%, ranges 100%, checksum 100%).";
CM_ BO_ 537 "ESP32-DualCAN Model3_CH. Seen on this car: 3-byte frames; fit ok (bits covered 100%, mux 100%, ranges 100%, checksum 100%).";
CM_ BO_ 545 "ESP32-DualCAN Model3_CH. Seen on this car: 8-byte frames; fit good (bits covered 100%, mux 100%, ranges 100%, checksum 100%).";
CM_ BO_ 549 "ESP32-DualCAN Model3_CH. Seen on this car: 4-byte frames; fit ok (bits covered 100%, mux 100%, ranges 100%).";
CM_ BO_ 551 "ESP32-DualCAN Model3_CH. Seen on this car: 8-byte frames; fit good (bits covered 100%, mux 100%, ranges 100%).";
CM_ BO_ 553 "ESP32-DualCAN Model3_CH. Seen on this car: 8-byte frames; fit good (bits covered 100%, mux 100%, ranges 100%).";
CM_ BO_ 561 "ESP32-DualCAN Model3_CH. Seen on this car: 8-byte frames; fit good (bits covered 100%, mux 100%, ranges 100%).";
CM_ BO_ 564 "ESP32-DualCAN Model3_CH. Seen on this car: 8-byte frames; fit good (bits covered 100%, mux 100%, ranges 100%).";
CM_ BO_ 565 "ESP32-DualCAN Model3_CH. Seen on this car: 4-byte frames; fit ok (bits covered 100%, mux 100%, ranges 100%).";
CM_ BO_ 568 "ESP32-DualCAN Model3_CH. Seen on this car: 8-byte frames; fit good (bits covered 100%, mux 100%, ranges 100%, checksum 100%).";
CM_ BO_ 569 "ESP32-DualCAN Model3_CH. Seen on this car: 8-byte frames; fit good (bits covered 100%, mux 100%, ranges 100%).";
CM_ BO_ 576 "ESP32-DualCAN Model3_CH. Seen on this car: 2-byte frames; fit ok (bits covered 100%, mux 100%, ranges 100%, checksum 100%).";
CM_ BO_ 583 "ESP32-DualCAN Model3_CH. Seen on this car: 8-byte frames; fit good (bits covered 100%, mux 100%, ranges 100%).";
CM_ BO_ 586 "ESP32-DualCAN Model3_CH. Seen on this car: 8-byte frames; fit good (bits covered 100%, mux 100%, ranges 100%).";
CM_ BO_ 599 "DashKit DBC. Seen on this car: 8-byte frames; fit ok (bits covered 58%, mux 100%, ranges 100%, checksum 100%). read by the app or firmware; DashKit names kept.";
CM_ BO_ 601 "ESP32-DualCAN Model3_CH. Seen on this car: 8-byte frames; fit good (bits covered 100%, mux 100%, ranges 100%, checksum 100%).";
CM_ BO_ 602 "ESP32-DualCAN Model3_CH. Seen on this car: 6-byte frames; fit ok (bits covered 100%, mux 100%, ranges 100%).";
CM_ BO_ 603 "ESP32-DualCAN Model3_CH. Seen on this car: 3-byte frames; fit poor (bits covered 0%, mux 100%, ranges 100%).";
CM_ BO_ 637 "ESP32-DualCAN Model3_CH. Seen on this car: 3-byte frames; fit ok (bits covered 100%, mux 100%, ranges 100%, checksum 100%).";
CM_ BO_ 644 "ESP32-DualCAN Model3_CH. Seen on this car: 8-byte frames; fit good (bits covered 100%, mux 100%, ranges 100%, checksum 100%).";
CM_ BO_ 659 "ESP32-DualCAN Model3_CH. Seen on this car: 8-byte frames; fit good (bits covered 100%, mux 100%, ranges 100%, checksum 100%).";
CM_ BO_ 680 "ESP32-DualCAN Model3_CH. Seen on this car: 8-byte frames; fit good (bits covered 100%, mux 100%, ranges 100%, checksum 100%).";
CM_ BO_ 697 "ESP32-DualCAN Model3_CH. Seen on this car: 8-byte frames; fit good (bits covered 100%, mux 100%, ranges 100%, checksum 100%).";
CM_ BO_ 723 "ESP32-DualCAN Model3_CH. Seen on this car: 8-byte frames; fit good (bits covered 100%, mux 100%, ranges 100%).";
CM_ BO_ 744 "ESP32-DualCAN Model3_CH. Seen on this car: 8-byte frames; fit good (bits covered 100%, mux 100%, ranges 100%, checksum 100%).";
CM_ BO_ 755 "DashKit DBC. Not seen on this bus; kept because the app names it.";
CM_ BO_ 760 "ESP32-DualCAN Model3_CH. Seen on this car: 8-byte frames; fit good (bits covered 100%, mux 100%, ranges 100%).";
CM_ BO_ 771 "ESP32-DualCAN Model3_CH. Seen on this car: 8-byte frames; fit good (bits covered 88%, mux 100%, ranges 100%, checksum 100%).";
CM_ BO_ 777 "DashKit DBC. Seen on this car: 8-byte frames; fit good (bits covered 100%, mux 80%, ranges 100%).";
CM_ BO_ 783 "ESP32-DualCAN Model3_CH. Seen on this car: 6-byte frames; fit poor (bits covered 0%, mux 100%, ranges 100%).";
CM_ BO_ 785 "ESP32-DualCAN Model3_CH. Seen on this car: 8-byte frames; fit good (bits covered 100%, mux 100%, ranges 100%).";
CM_ BO_ 789 "ESP32-DualCAN Model3_CH. Seen on this car: 8-byte frames; fit good (bits covered 100%, mux 100%, ranges 100%).";
CM_ BO_ 792 "ESP32-DualCAN Model3_CH. Seen on this car: 8-byte frames; fit good (bits covered 100%, mux 100%, ranges 100%, checksum 100%).";
CM_ BO_ 801 "ESP32-DualCAN Model3_CH. Seen on this car: 8-byte frames; fit good (bits covered 100%, mux 100%, ranges 100%, checksum 100%). read by the app or firmware.";
CM_ BO_ 805 "ESP32-DualCAN Model3_CH. Seen on this car: 8-byte frames; fit ok (bits covered 100%, mux 100%, ranges 100%).";
CM_ BO_ 809 "ESP32-DualCAN Model3_CH. Seen on this car: 8-byte frames; fit weak (bits covered 0%, mux 100%, ranges 100%).";
CM_ BO_ 811 "ESP32-DualCAN Model3_CH. Seen on this car: 8-byte frames; fit weak (bits covered 0%, mux 100%, ranges 100%).";
CM_ BO_ 813 "ESP32-DualCAN Model3_CH. Seen on this car: 8-byte frames; fit ok (bits covered 100%, mux 100%, ranges 100%).";
CM_ BO_ 815 "ESP32-DualCAN Model3_CH. Seen on this car: 8-byte frames; fit good (bits covered 100%, mux 100%, ranges 100%).";
CM_ BO_ 817 "ESP32-DualCAN Model3_CH. Seen on this car: 6-byte frames; fit poor (bits covered 0%, mux 100%, ranges 100%).";
CM_ BO_ 820 "ESP32-DualCAN Model3_CH. Seen on this car: 8-byte frames; fit ok (bits covered 82%, mux 100%, ranges 100%, checksum 100%).";
CM_ BO_ 829 "ESP32-DualCAN Model3_CH. Seen on this car: 8-byte frames; fit good (bits covered 100%, mux 100%, ranges 100%).";
CM_ BO_ 838 "ESP32-DualCAN Model3_CH. Seen on this car: 8-byte frames; fit weak (bits covered 0%, mux 100%, ranges 100%).";
CM_ BO_ 840 "ESP32-DualCAN Model3_CH. Seen on this car: 8-byte frames; fit good (bits covered 100%, mux 100%, ranges 100%).";
CM_ BO_ 843 "ESP32-DualCAN Model3_CH. Seen on this car: 6-byte frames; fit ok (bits covered 100%, mux 100%, ranges 100%).";
CM_ BO_ 847 "ESP32-DualCAN Model3_CH. Seen on this car: 8-byte frames; fit good (bits covered 100%, mux 100%, ranges 100%).";
CM_ BO_ 848 "ESP32-DualCAN Model3_CH. Seen on this car: 8-byte frames; fit weak (bits covered 0%, mux 100%, ranges 100%).";
CM_ BO_ 849 "ESP32-DualCAN Model3_CH. Seen on this car: 8-byte frames; fit good (bits covered 100%, mux 100%, ranges 100%).";
CM_ BO_ 851 "ESP32-DualCAN Model3_CH. Seen on this car: 8-byte frames; fit good (bits covered 100%, mux 100%, ranges 100%).";
CM_ BO_ 852 "ESP32-DualCAN Model3_CH. Seen on this car: 6-byte frames; fit ok (bits covered 100%, mux 100%, ranges 100%).";
CM_ BO_ 859 "ESP32-DualCAN Model3_CH. Seen on this car: 5-byte frames; fit ok (bits covered 100%, mux 100%, ranges 100%, checksum 100%).";
CM_ BO_ 873 "ESP32-DualCAN Model3_CH. Seen on this car: 8-byte frames; fit weak (bits covered 0%, mux 100%, ranges 100%).";
BA_DEF_ BO_  "GenMsgCycleTime" INT 0 65535;
BA_DEF_DEF_  "GenMsgCycleTime" 0;
BA_ "GenMsgCycleTime" BO_ 258 100;
BA_ "GenMsgCycleTime" BO_ 259 100;
BA_ "GenMsgSendType" BO_ 280 0;
BA_ "GenMsgCycleTime" BO_ 280 10;
BA_ "GenMsgSendType" BO_ 297 0;
BA_ "GenMsgCycleTime" BO_ 297 10;
BA_ "GenMsgSendType" BO_ 552 0;
BA_ "GenMsgCycleTime" BO_ 552 100;
BA_ "GenMsgSendType" BO_ 585 0;
BA_ "GenMsgCycleTime" BO_ 585 100;
BA_ "GenMsgCycleTime" BO_ 599 20;
BA_ "GenMsgSendType" BO_ 737 0;
BA_ "GenMsgCycleTime" BO_ 737 20;
BA_ "GenMsgCycleTime" BO_ 755 500;
BA_ "GenMsgCycleTime" BO_ 777 30;
VAL_ 49 EPAS3P_state 0 "STANDBY" 1 "DRIVE" 2 "SUPPORT" 3 "CHARGE" 4 "FEIM" 5 "CLEAR_FAULT" 6 "FAULT" 7 "WELD" 8 "TEST" 9 "SNA" 10 "DIAG" ;
VAL_ 81 EPAS3S_state 0 "STANDBY" 1 "DRIVE" 2 "SUPPORT" 3 "CHARGE" 4 "FEIM" 5 "CLEAR_FAULT" 6 "FAULT" 7 "WELD" 8 "TEST" 9 "SNA" 10 "DIAG" ;
VAL_ 82 EPAS3P_eacStatus 0 "INHIBITED" 1 "AVAILABLE" 2 "ACTIVE" 3 "FAULT" 4 "LKA_ELK_AVAILABLE" 5 "LKA_ACTIVE" 6 "ELK_AVAILABLE" 7 "ELK_ACTIVE" ;
VAL_ 82 EPAS3P_handsOnLevel 0 "0" 1 "1" 2 "2" 3 "3" ;
VAL_ 82 EPAS3P_torsionBarTorque 4094 "UNDEFINABLE_DATA" 4095 "SNA" ;
VAL_ 82 EPAS3P_eacErrorCode 0 "EAC_ERROR_IDLE" 1 "EAC_ERROR_MIN_SPEED" 2 "EAC_ERROR_MAX_SPEED" 3 "EAC_ERROR_HANDS_ON" 4 "EAC_ERROR_TMP_FAULT" 5 "EAR_ERROR_MAX_STEER_DELTA" 6 "EAC_ERROR_HIGH_ANGLE_REQ" 7 "EAC_ERROR_HIGH_ANGLE_RATE_REQ" 8 "EAC_ERROR_HIGH_ANGLE_SAFETY" 9 "EAC_ERROR_HIGH_ANGLE_RATE_SAFETY" 10 "EAC_ERROR_HIGH_MMOT_SAFETY" 11 "EAC_ERROR_HIGH_TORSION_SAFETY" 12 "EAC_ERROR_LOW_ASSIST" 13 "EAC_ERROR_PINION_VEL_DIFF" 14 "EAC_EXTERNAL_MONITOR_INHIBIT" 15 "SNA" ;
VAL_ 82 EPAS3P_steeringRackForce 1022 "NOT_IN_SPEC" 1023 "SNA" ;
VAL_ 82 EPAS3P_steeringFault 0 "NO_FAULT" 1 "FAULT" ;
VAL_ 82 EPAS3P_steeringReduced 0 "NORMAL_ASSIST" 1 "REDUCED_ASSIST" ;
VAL_ 82 EPAS3P_internalSASQF 0 "UNDEFINABLE_ACCURACY" 1 "IN_SPEC" ;
VAL_ 82 EPAS3P_currentTuneMode 0 "DM_COMFORT" 1 "DM_STANDARD" 2 "DM_SPORT" 3 "RWD_COMFORT" 4 "RWD_STANDARD" 5 "RWD_SPORT" ;
VAL_ 257 RCM_pitchRateQF 0 "INIT" 1 "VALID" 2 "TEMP_INVALID" 3 "FAULTED" ;
VAL_ 257 RCM_yawRateQF 0 "FAULTED" 1 "NOT_FAULTED" ;
VAL_ 257 RCM_rollRateQF 0 "INIT" 1 "VALID" 2 "TEMP_INVALID" 3 "FAULTED" ;
VAL_ 257 RCM_rollRate 4294950912 "SNA" ;
VAL_ 257 RCM_pitchRate 4294950912 "SNA" ;
VAL_ 257 RCM_yawRate 4294934528 "SNA" ;
VAL_ 258 VCLEFT_mirrorHeatState 0 "SNA" 1 "ON" 2 "OFF" 3 "OFF_UNAVAILABLE" 4 "FAULT" ;
VAL_ 258 VCLEFT_mirrorRecallState 0 "INIT" 1 "RECALLING_AXIS_1" 2 "RECALLING_AXIS_2" 3 "RECALLING_COMPLETE" 4 "RECALLING_FAILED" 5 "RECALLING_STOPPED" ;
VAL_ 258 VCLEFT_mirrorFoldState 0 "UNKNOWN" 1 "FOLDED" 2 "UNFOLDED" 3 "FOLDING" 4 "UNFOLDING" ;
VAL_ 258 VCLEFT_mirrorState 0 "IDLE" 1 "TILT_X" 2 "TILT_Y" 3 "FOLD_UNFOLD" 4 "RECALL" ;
VAL_ 258 VCLEFT_rearLatchStatus 0 "SNA" 1 "OPENED" 2 "CLOSED" 3 "CLOSING" 4 "OPENING" 5 "AJAR" 6 "TIMEOUT" 7 "DEFAULT" 8 "FAULT" ;
VAL_ 258 VCLEFT_frontLatchStatus 0 "SNA" 1 "OPENED" 2 "CLOSED" 3 "CLOSING" 4 "OPENING" 5 "AJAR" 6 "TIMEOUT" 7 "DEFAULT" 8 "FAULT" ;
VAL_ 259 VCRIGHT_mirrorRecallState 0 "INIT" 1 "RECALLING_AXIS_1" 2 "RECALLING_AXIS_2" 3 "RECALLING_COMPLETE" 4 "RECALLING_FAILED" 5 "RECALLING_STOPPED" ;
VAL_ 259 VCRIGHT_trunkLatchStatus 0 "SNA" 1 "OPENED" 2 "CLOSED" 3 "CLOSING" 4 "OPENING" 5 "AJAR" 6 "TIMEOUT" 7 "DEFAULT" 8 "FAULT" ;
VAL_ 259 VCRIGHT_mirrorFoldState 0 "UNKNOWN" 1 "FOLDED" 2 "UNFOLDED" 3 "FOLDING" 4 "UNFOLDING" ;
VAL_ 259 VCRIGHT_mirrorState 0 "IDLE" 1 "TILT_X" 2 "TILT_Y" 3 "FOLD_UNFOLD" 4 "RECALL" ;
VAL_ 259 VCRIGHT_rearLatchStatus 0 "SNA" 1 "OPENED" 2 "CLOSED" 3 "CLOSING" 4 "OPENING" 5 "AJAR" 6 "TIMEOUT" 7 "DEFAULT" 8 "FAULT" ;
VAL_ 259 VCRIGHT_frontLatchStatus 0 "SNA" 1 "OPENED" 2 "CLOSED" 3 "CLOSING" 4 "OPENING" 5 "AJAR" 6 "TIMEOUT" 7 "DEFAULT" 8 "FAULT" ;
VAL_ 264 DIR_gear 0 "INVALID" 1 "P" 2 "R" 3 "N" 4 "D" 7 "SNA" ;
VAL_ 264 DIR_axlePowerCalcQF 0 "INVALID" 1 "VALID" ;
VAL_ 264 DIR_axleTorqueQF 0 "INVALID" 1 "VALID" 2 "FAULTED" ;
VAL_ 264 DIR_axleSpeed 4294934528 "SNA" ;
VAL_ 264 DIR_torqueActual 4294963200 "SNA" ;
VAL_ 264 DIR_axleSpeedQF 0 "INVALID" 1 "VALID" 2 "FAULTED" ;
VAL_ 264 DIR_torqueCommand 4294963200 "SNA" ;
VAL_ 273 RCM_CGTranslationFault 0 "NOT_FAULTED" 1 "FAULTED" ;
VAL_ 273 RCM_verticalAccelQF 0 "FAULTED" 1 "NOT_FAULTED" ;
VAL_ 273 RCM_lateralAccelQF 0 "FAULTED" 1 "NOT_FAULTED" ;
VAL_ 273 RCM_longitudinalAccelQF 0 "FAULTED" 1 "NOT_FAULTED" ;
VAL_ 273 RCM_verticalAccel 4294934528 "SNA" ;
VAL_ 273 RCM_lateralAccel 4294934528 "SNA" ;
VAL_ 273 RCM_longitudinalAccel 4294934528 "SNA" ;
VAL_ 280 DI_trackModeState 0 "UNAVAILABLE" 1 "AVAILABLE" 2 "ON" ;
VAL_ 280 DI_keepAliveRequest 0 "NO_REQUEST" 1 "KEEP_ALIVE" ;
VAL_ 280 DI_epbRequest 0 "NO_REQUEST" 1 "PARK" 2 "UNPARK" ;
VAL_ 280 DI_tractionControlMode 0 "NORMAL" 1 "SLIP_START" 2 "DEV_MODE_1" 3 "DEV_MODE_2" 4 "ROLLS_MODE" 5 "DYNO_MODE" ;
VAL_ 280 DI_accelPedalPos 255 "SNA" ;
VAL_ 280 DI_immobilizerState 0 "INIT_SNA" 1 "REQUEST" 2 "AUTHENTICATING" 3 "DISARMED" 4 "IDLE" 5 "RESET" 6 "FAULT" ;
VAL_ 280 DI_gear 0 "INVALID" 1 "P" 2 "R" 3 "N" 4 "D" 7 "SNA" ;
VAL_ 280 DI_brakePedalState 0 "OFF" 1 "ON" 2 "INVALID" ;
VAL_ 280 DI_systemState 0 "UNAVAILABLE" 1 "IDLE" 2 "STANDBY" 3 "FAULT" 4 "ABORT" 5 "ENABLE" ;
VAL_ 297 SCCM_steeringAngleValidity 0 "INVALID" 1 "VALID" 2 "INIT" 3 "SNA" ;
VAL_ 297 SCCM_steeringAngleSensorStatus 0 "OK" 1 "INIT" 2 "ERROR" 3 "ERROR_INIT" ;
VAL_ 325 ESP_brakeTorqueTarget 8191 "SNA" ;
VAL_ 325 ESP_ebrStatus 0 "EBR_IS_NOT_AVAILABLE" 1 "EBR_IS_AVAILABLE" 2 "ACTUATING_DI_EBR" 3 "EBR_COMMAND_INVALID" ;
VAL_ 325 ESP_ebrStandstillSkid 0 "NO_STANDSTILL_SKID" 1 "STANDSTILL_SKID_DETECTED" ;
VAL_ 325 ESP_btcTargetState 0 "OFF" 1 "BACKUP" 2 "ON" 3 "SNA" ;
VAL_ 325 ESP_ptcTargetState 0 "FAULT" 1 "BACKUP" 2 "ON" 3 "SNA" ;
VAL_ 325 ESP_cdpStatus 0 "CDP_IS_NOT_AVAILABLE" 1 "CDP_IS_AVAILABLE" 2 "ACTUATING_EPB_CDP" 3 "CDP_COMMAND_INVALID" ;
VAL_ 325 ESP_brakeApply 0 "INACTIVE" 1 "ACTIVE" ;
VAL_ 325 ESP_driverBrakeApply 0 "NotInit_orOff" 1 "Not_Applied" 2 "Driver_applying_brakes" 3 "Faulty_SNA" ;
VAL_ 325 ESP_brakeDiscWipingActive 0 "INACTIVE" 1 "ACTIVE" ;
VAL_ 325 ESP_steeringAngleQF 0 "UNDEFINABLE_ACCURACY" 1 "IN_SPEC" ;
VAL_ 325 ESP_yawRateQF 0 "UNDEFINABLE_ACCURACY" 1 "IN_SPEC" ;
VAL_ 325 ESP_lateralAccelQF 0 "UNDEFINABLE_ACCURACY" 1 "IN_SPEC" ;
VAL_ 325 ESP_longitudinalAccelQF 0 "UNDEFINABLE_ACCURACY" 1 "IN_SPEC" ;
VAL_ 325 ESP_absBrakeEvent2 0 "NOT_ACTIVE" 1 "ACTIVE_FRONT_REAR" 2 "ACTIVE_FRONT" 3 "ACTIVE_REAR" ;
VAL_ 325 ESP_brakeLamp 0 "OFF" 1 "ON" ;
VAL_ 325 ESP_espLampFlash 0 "OFF" 1 "FLASH" ;
VAL_ 325 ESP_espFaultLamp 0 "OFF" 1 "ON" ;
VAL_ 325 ESP_absFaultLamp 0 "OFF" 1 "ON" ;
VAL_ 325 ESP_ebdFaultLamp 0 "OFF" 1 "ON" ;
VAL_ 325 ESP_stabilityControlSts2 0 "INIT" 1 "ON" 2 "ENGAGED" 3 "FAULTED" ;
VAL_ 325 ESP_espModeActive 0 "00_NORMAL" 1 "01" 2 "02" 3 "03" ;
VAL_ 329 IBST_brakeTorqueTarget 8191 "SNA" ;
VAL_ 341 ESP_vehicleSpeed 8191 "SNA" ;
VAL_ 521 DAS_pedalControl_accelPedalPos 255 "SNA" ;
VAL_ 521 DAS_gearRequest 0 "IDLE_SNA" 1 "PARK" 2 "REVERSE" 3 "NEUTRAL" 4 "DRIVE" ;
VAL_ 529 RCM_pedProEDR2State 0 "EMPTY" 1 "STORED" 2 "LOCKED" 3 "UNAVAILABLE" ;
VAL_ 529 RCM_pedProEDR1State 0 "EMPTY" 1 "STORED" 2 "LOCKED" 3 "UNAVAILABLE" ;
VAL_ 529 RCM_driverOrientationInitStatus 0 "RCM_DRIVER_ORIENTATION_INIT_NOT_COMPLETE" 1 "RCM_DRIVER_ORIENTATION_MATCHED_LHD" 2 "RCM_DRIVER_ORIENTATION_MATCHED_RHD" 3 "RCM_DRIVER_ORIENTATION_MISMATCH_DEFAULT_LHD" 4 "RCM_DRIVER_ORIENTATION_MISMATCH_DEFAULT_RHD" 7 "SNA" ;
VAL_ 529 RCM_edr3State 0 "EMPTY" 1 "STORED" 2 "LOCKED" 3 "UNAVAILABLE" ;
VAL_ 529 RCM_imuOffsetLearnState 0 "OFFSET_LEARNING_OFF" 1 "SLOW_LEARNING_DISTANCE" 2 "FAST_LEARNING_TIME" 3 "OFFSETS_UNABLE_TO_LEARN" ;
VAL_ 529 RCM_keepPowerReason 0 "NO_KEEP_POWER_REQUEST" 1 "IN_IDLE_MODE" 2 "CRASH_ALGO_ACTIVE" 3 "EDR_STORING_TO_EEPROM" 4 "EDR_UPLOADING" 5 "CANNOT_POWER_DOWN" 6 "INITIALIZATION_PHASE" 7 "INVALID_POWER_OFF_REQUEST" 8 "KEEP_POWER_REASON_SNA" ;
VAL_ 529 RCM_edr2State 0 "EMPTY" 1 "STORED" 2 "LOCKED" 3 "UNAVAILABLE" ;
VAL_ 529 RCM_edr1State 0 "EMPTY" 1 "STORED" 2 "LOCKED" 3 "UNAVAILABLE" ;
VAL_ 529 RCM_seatTrackPositionPass 0 "RCM_SEAT_POSITION_NEAR" 1 "RCM_SEAT_POSITION_FAR" 2 "RCM_SEAT_POSITION_FAULTED" 3 "SNA" ;
VAL_ 529 RCM_seatTrackPositionDrvr 0 "RCM_SEAT_POSITION_NEAR" 1 "RCM_SEAT_POSITION_FAR" 2 "RCM_SEAT_POSITION_FAULTED" 3 "SNA" ;
VAL_ 529 RCM_vinLearnFlag 0 "RCM_VIN_NOT_STORED" 1 "RCM_VIN_STORED" 2 "RCM_VIN_STORED_MISMATCH" 3 "SNA" ;
VAL_ 529 RCM_alrSwitchStatus 0 "RCM_ALR_NOT_ENGAGED" 1 "RCM_ALR_ENGAGED" 2 "RCM_ALR_FAULTED" 3 "SNA" ;
VAL_ 529 RCM_airbagCutoffStatus 0 "RCM_PASSENGER_AIRBAG_ENABLED" 1 "RCM_PASSENGER_AIRBAG_DISABLED" 3 "SNA" ;
VAL_ 529 RCM_passAirbagIndicatorRequest 0 "RCM_PASSENGER_AIRBAG_INDICATOR_ON" 1 "RCM_PASSENGER_AIRBAG_INDICATOR_OFF" 3 "SNA" ;
VAL_ 529 RCM_warningIndicatorState 0 "RCM_WARNING_INDICATOR_OFF" 1 "RCM_WARNING_INDICATOR_ON" 3 "SNA" ;
VAL_ 529 RCM_armStatus 0 "RCM_UNARMED" 1 "RCM_ARMED" 2 "ARMED_WITH_NOFIRE_CAL" 3 "SNA" ;
VAL_ 537 DAS_wheelType 0 "PINWHEEL_18" 1 "STILETTO_19" 2 "STILETTO_20" 3 "STILETTO_20_DARK_STAGGERED" 4 "GEMINI_19_SQUARE" 5 "GEMINI_19_STAGGERED" 14 "STILETTO_20_DARK_SQUARE" 15 "INDUCTION_20_BLACK" 16 "UBERTURBINE_21_BLACK" 17 "APOLLO_19_SILVER" 18 "PINWHEEL_18_CAP_KIT" 19 "ZEROG_20_GUNPOWDER" 20 "APOLLO_19_SILVER_CAP_KIT" 21 "STILETTO_REFRESH_19" 22 "PINWHEEL_REFRESH_18" 23 "UBERTURBINE_20_GUNPOWDER" 24 "PINWHEEL_REFRESH_18_CAP_KIT" 27 "ZEROG_19_GUNPOWDER" ;
VAL_ 545 VCFRONT_uiHiCurrentLVState 0 "OFF" 1 "ON" 2 "GOING_DOWN" 3 "FAULT" ;
VAL_ 545 VCFRONT_espValveLVState 0 "OFF" 1 "ON" 2 "GOING_DOWN" 3 "FAULT" ;
VAL_ 545 VCFRONT_hcmlLVState 0 "OFF" 1 "ON" 2 "GOING_DOWN" 3 "FAULT" ;
VAL_ 545 VCFRONT_epasLVState 0 "OFF" 1 "ON" 2 "GOING_DOWN" 3 "FAULT" ;
VAL_ 545 VCFRONT_espLVState 0 "OFF" 1 "ON" 2 "GOING_DOWN" 3 "FAULT" ;
VAL_ 545 VCFRONT_parkLVState 0 "OFF" 1 "ON" 2 "GOING_DOWN" 3 "FAULT" ;
VAL_ 545 VCFRONT_vehiclePowerState 0 "OFF" 1 "CONDITIONING" 2 "ACCESSORY" 3 "DRIVE" ;
VAL_ 545 VCFRONT_LVPowerStateIndex 0 "Mux0" 1 "Mux1" ;
VAL_ 549 VCRIGHT_icrLVState 0 "OFF" 1 "ON" 2 "GOING_DOWN" 3 "FAULT" ;
VAL_ 549 VCRIGHT_parkLVState 0 "OFF" 1 "ON" 2 "GOING_DOWN" 3 "FAULT" ;
VAL_ 549 VCRIGHT_vehiclePowerStateDBG 0 "INIT" 1 "LOW_POWER_AWAKE" 2 "CONDITIONING" 3 "ACCESSORY" 4 "ACCESSORY_PLUS" 5 "DRIVE" 6 "OTA" 7 "WAIT_FOR_HIGH_POWER" 8 "TURN_ON_LV" 9 "SYSTEM_CHECKS" 10 "LV_ON" 11 "JUMP_START" 12 "LV_SHUTDOWN" 13 "GO_QUIET" 14 "SLEEP_SHUTDOWN" 15 "LOW_POWER_STANDBY" 16 "RESET" ;
VAL_ 549 VCRIGHT_eFuseLockoutStatus 0 "IDLE" 1 "PENDING" 2 "ACTIVE" ;
VAL_ 549 VCRIGHT_lumbarLVState 0 "OFF" 1 "ON" 2 "GOING_DOWN" 3 "FAULT" ;
VAL_ 549 VCRIGHT_rcmLVState 0 "OFF" 1 "ON" 2 "GOING_DOWN" 3 "FAULT" ;
VAL_ 549 VCRIGHT_hvcLVState 0 "OFF" 1 "ON" 2 "GOING_DOWN" 3 "FAULT" ;
VAL_ 549 VCRIGHT_tunerLVState 0 "OFF" 1 "ON" 2 "GOING_DOWN" 3 "FAULT" ;
VAL_ 549 VCRIGHT_premAudioLVState 0 "OFF" 1 "ON" 2 "GOING_DOWN" 3 "FAULT" ;
VAL_ 549 VCRIGHT_ocsLVState 0 "OFF" 1 "ON" 2 "GOING_DOWN" 3 "FAULT" ;
VAL_ 549 VCRIGHT_ptcLVState 0 "OFF" 1 "ON" 2 "GOING_DOWN" 3 "FAULT" ;
VAL_ 552 EPBR_internalCDPRequest 0 "NOT_REQUESTED" 1 "REQUESTED" ;
VAL_ 552 EPBR_epbmCDPQualified 0 "IDLE" 1 "VALID" 2 "INVALID" ;
VAL_ 552 EPBR_summonFaultReason 0 "NONE" 1 "DI_MIA" 2 "DAS_MIA" 3 "ESP_MIA" 4 "EPBM_MIA" 5 "DI_FAULT" 6 "DI_APC_FAULT" 7 "DAS_FAULT" 8 "ESP_FAULT" 9 "VEH_CAN_FAULT" 10 "EAC_NOT_ALLOWED" 11 "EPBM_REQUEST" 12 "SPEED" 13 "EXTERNAL" 14 "PARK_MIA" 15 "PM_MIA" 16 "PM_REQUEST" 17 "OOC" 18 "MISMATCH" 19 "EPB_FAULT" 20 "DI_STATE_INVALID" 21 "PASSIVE_REQUEST" 22 "EPBREMOTE_MIA" 23 "REMOTE_SUMMON_FAULTED" 24 "LOCAL_UNIT_FAULTED" 25 "REMOTE_UNIT_FAULTED" 26 "START_IN_UNAVAILABLE" 27 "INVALID_REMOTE_STATE" 28 "REMOTE_DID_NOT_START" ;
VAL_ 552 EPBR_esmOperationTrigger 0 "PBUTTON_PRESSED_STOPPED" 1 "PBUTTON_PRESSED_OKTOPARK" 2 "PBUTTON_PRESSED_FAST" 3 "PBUTTON_PRESSED_UNKNOWN" 4 "PBUTTON_RELEASED" 5 "ACTIVE_PARK_REQUEST" 6 "DI_UNPARK" 7 "TOUCHSCREEN" 8 "WINCHMODE_EXIT" 9 "WINCHMODE_ENTER" 10 "WINCHMODE_UNAVAILABLE" 11 "SERVICE" 12 "DIAG_CLOSE" 13 "DIAG_OPEN" 14 "DIAG_EXIT" 15 "USER_CONFIRMED" 16 "USER_CANCEL" 17 "SPEED_STOPPED" 18 "SPEED_OKAYTOPARK" 19 "SPEED_FAST" 20 "TIMEOUT" 21 "SAVESTATE_ON_BOOT" 22 "REAPPLY" 23 "SUMMON_COMPLETE" 24 "FAULT" 25 "SUMMON_FAULT" 26 "DISQUALIFIED" 27 "EPBM_DISQUALIFIED" 28 "ACCELERATION" 29 "SYSTEM_APPLY" 30 "DRIVER_IS_LEAVING" ;
VAL_ 552 EPBR_csmFaultReason 0 "NONE" 1 "EPBM_DISABLED" 2 "EPBM_FAULTED" 3 "STATE_MISMATCH" 4 "TIMEOUT_CALIBRATE" 5 "APPLY_BLOCKED" 6 "RELEASE_BLOCKED" 7 "TIMEOUT_APPLY_COMPLETE" 8 "TIMEOUT_APPLY_INRUSH" 9 "TIMEOUT_WAIT_FOR_CLAMP" 10 "TIMEOUT_RELEASE_INRUSH" 11 "TIMEOUT_RELEASE_WAIT_FOR_ENDSTOP" 12 "TIMEOUT_RELEASE_COMPLETE" 13 "TIMEOUT_EPBM_CUTOFF" 14 "TIMEOUT_NO_RAMP" 15 "TIMEOUT_EPBM_START" 16 "MOTOR_IDLE_FAULT" 17 "MOTOR_ACTIVE_FAULT" 18 "MOTOR_NOT_READY" 19 "EPBM_MIA" 20 "NVM_MISMATCH" 21 "REMOTE_MIA" ;
VAL_ 552 EPBR_esmCaliperRequest 0 "INVALID" 1 "NONE" 2 "APPLY" 3 "RELEASE" 4 "ENDSTOP" ;
VAL_ 552 EPBR_summonState 0 "INIT" 1 "IDLE" 2 "ARMED" 3 "ACTIVE" 4 "COMPLETE" 5 "FAULT" 6 "UNAVAILABLE" ;
VAL_ 552 EPBR_unitFaultStatus 0 "NOMINAL" 1 "RETRY" 2 "FAULT" 3 "FAULT_IDLE" ;
VAL_ 552 EPBR_unitStatus 0 "UNKNOWN" 1 "OPEN" 2 "DYNAMIC" 3 "PARK" 4 "START" 5 "SERVICE" 6 "WINCHMODE" 7 "WINCHMODE_RELEASING" 8 "PARKING" 9 "DYNAMIC_APPLYING" 10 "RELEASING" 11 "SERVICE_RELEASING" 12 "PARK_PENDING" 13 "WINCHMODE_PENDING" 14 "SUMMON" 15 "SUMMON_RELEASING" 16 "SUMMON_PARKING" 17 "EXTERNAL_DYNAMIC" 18 "RELEASING_FOR_EXTERNAL_PARK" 19 "EXTERNAL_PARKING" 20 "DYNAMIC_PARKING" 21 "COUNT" ;
VAL_ 568 UI_nextBranchDist 31 "SNA" ;
VAL_ 568 UI_countryCode 0 "UNKNOWN" 1023 "SNA" ;
VAL_ 568 UI_mapSpeedLimitType 1 "REGULAR" 2 "ADVISORY" 3 "DEPENDENT" 4 "BUMPS" 7 "UNKNOWN_SNA" ;
VAL_ 568 UI_mapSpeedLimit 0 "UNKNOWN" 1 "LESS_OR_EQ_5" 2 "LESS_OR_EQ_7" 3 "LESS_OR_EQ_10" 4 "LESS_OR_EQ_15" 5 "LESS_OR_EQ_20" 6 "LESS_OR_EQ_25" 7 "LESS_OR_EQ_30" 8 "LESS_OR_EQ_35" 9 "LESS_OR_EQ_40" 10 "LESS_OR_EQ_45" 11 "LESS_OR_EQ_50" 12 "LESS_OR_EQ_55" 13 "LESS_OR_EQ_60" 14 "LESS_OR_EQ_65" 15 "LESS_OR_EQ_70" 16 "LESS_OR_EQ_75" 17 "LESS_OR_EQ_80" 18 "LESS_OR_EQ_85" 19 "LESS_OR_EQ_90" 20 "LESS_OR_EQ_95" 21 "LESS_OR_EQ_100" 22 "LESS_OR_EQ_105" 23 "LESS_OR_EQ_110" 24 "LESS_OR_EQ_115" 25 "LESS_OR_EQ_120" 26 "LESS_OR_EQ_130" 27 "LESS_OR_EQ_140" 28 "LESS_OR_EQ_150" 29 "LESS_OR_EQ_160" 30 "UNLIMITED" 31 "SNA" ;
VAL_ 568 UI_mapSpeedUnits 0 "MPH" 1 "KPH" ;
VAL_ 568 UI_inSuperchargerGeofence 0 "FALSE" 1 "TRUE" ;
VAL_ 568 UI_roadClass 0 "UNKNOWN_INVALID_SNA" 1 "CLASS_1_MAJOR" 2 "CLASS_2" 3 "CLASS_3" 4 "CLASS_4" 5 "CLASS_5" 6 "CLASS_6_MINOR" ;
VAL_ 568 UI_mapSpeedLimitDependency 0 "NONE" 1 "SCHOOL" 2 "RAIN" 3 "SNOW" 4 "TIME" 5 "SEASON" 6 "LANE" 7 "SNA" ;
VAL_ 569 DAS_rightFork 0 "NONE" 1 "AVAILABLE" 2 "SELECTED" 3 "UNAVAILABLE" ;
VAL_ 569 DAS_leftFork 0 "NONE" 1 "AVAILABLE" 2 "SELECTED" 3 "UNAVAILABLE" ;
VAL_ 569 DAS_rightLineUsage 0 "REJECTED_UNAVAILABLE" 1 "AVAILABLE" 2 "FUSED" 3 "BLACKLISTED" ;
VAL_ 569 DAS_leftLineUsage 0 "REJECTED_UNAVAILABLE" 1 "AVAILABLE" 2 "FUSED" 3 "BLACKLISTED" ;
VAL_ 583 DAS_lastWatchdogCode 0 "NO_TASK_FAILED" 30 "UNKNOWN_TASK_FAILED" 39 "TELEMETRY_PACKAGER_FAILED" 40 "TELEMETRY_FAILED" 41 "SNAPSHOT_FAILED" 42 "VISION_FAILED" 43 "LEGACY_FAILED" 44 "WATCHDOG_FAILED" 45 "CAN_RX_FAILED" 46 "CAN_TX_FAILED" 47 "TEMPERATURE_MONITOR_FAILED" 48 "INERTIATOR_FAILED" 49 "GPS_FAILED" 50 "ARBITER_FAILED" 51 "AP_STATE_MACHINE_FAILED" 52 "CONTROLLER_FAILED" 53 "LOCALIZER_FAILED" 54 "MISSION_PLANNER_FAILED" 55 "PERCEPTION_FAILED" 56 "ROAD_ESTIMATOR_FAILED" 57 "ATLAS_FAILED" 58 "STAY_IN_LANE_BEHAVIOR_FAILED" 59 "SNAPSHOT_TRIGGER_CLIENT_FAILED" 60 "RAIN_LIGHT_SENSING_FAILED" 61 "IMU_FAILED" 62 "UBX_LOG_FAILED" 63 "LANE_CHANGE_BEHAVIOR_FAILED" 65 "DRIVER_MONITOR_FAILED" 66 "MAP_MANAGER_FAILED" 67 "CAMERA_FAILED" 68 "ACTIVE_SAFETY_FAILED" 69 "UI_SERVER_FAILED" 70 "DYNAMICS_FAILED" 71 "FIELD_CALIBRATION_FAILED" 72 "PARKING_BEHAVIOR_FAILED" 73 "HW_MONITOR_FAILED" 74 "CLIP_LOGGER_FAILED" 75 "DRIVABLE_SPACE_TRACKER_FAILED" 76 "SCHEDULER_FAILED" 77 "BRIDGE_FAILED" 78 "CITY_STREETS_BEHAVIOR_FAILED" 79 "BEV_GRAPH_FAILED" 80 "ULTRASONICS_FAILED" 81 "RADAR_FAILED" 82 "SYNC_PIPELINE_FAILED" 83 "X1_CLIENT_FAILED" 84 "FLEET_CONFIG_FAILED" 85 "GEO_REGION_FAILED" 86 "TELEMETRY_COMPLIANCE_FAILED" ;
VAL_ 583 DAS_laneChangeState 0 "UNAVAILABLE_DISABLED" 1 "UNAVAILABLE_ROAD_NOT_APPROPRIATE" 2 "UNAVAILABLE_SPEED" 3 "UNAVAILABLE_NO_LANES" 4 "UNAVAILABLE_INACTIVE" 5 "UNAVAILABLE_FORK_MODE" 6 "UNAVAILABLE_ULTRASONICS_NOT_READY" 7 "UNAVAILABLE_INVALID_MODE" 8 "AVAILABLE_LEFT_ONLY" 9 "AVAILABLE_RIGHT_ONLY" 10 "AVAILABLE_BOTH" 11 "ABORTING_INACTIVE" 12 "ABORTING_BLINKER" 13 "ABORTING_TIMEOUT" 14 "ABORTING_BLIND_SPOT_OCCUPIED" 15 "ABORTING_INVALID_MODE" 16 "ABORTING_LINE_TYPE" 17 "ABORTING_FORK_AVAILABLE" 18 "ABORTING_LOST_VISION_POSE" 19 "ABORTING_ACC_AUTOSTEER_ACTIVATED" 20 "ABORTING_ULC_BLINKER_TIMEOUT" 21 "ABORTING_INVALID_BEHAVIOR" 22 "ABORTING_BELOW_MIN_SPEED" 23 "ABORTING_BEHAVIOR_CHANGED" 24 "ABORTING_HIGH_ALC_PROGRESS_ERROR" 25 "ABORTING_ULC_CONFIRMATION_TIMEOUT" 26 "ABORTING_ALC_REQUEST_BEFORE_ULC_CONFIRM" 27 "IN_PROGRESS_LEFT" 28 "IN_PROGRESS_RIGHT" 29 "BLOCKED_LEFT" 30 "BLOCKED_RIGHT" 31 "ABORTING_GORE_POINT" 32 "ABORTING_CONSTRUCTION_DETECTED" 33 "ABORTING_TOLL_BOOTH_DETECTED" 34 "ABORTING_TIGHT_TURN_RADIUS" 35 "ABORTING_WEATHER" 36 "UNAVAILABLE_BLINDSPOT_RESTRICTED" 37 "ABORTING_NO_HANDS_ON" 38 "UNAVAILABLE_NO_REAR_OBJECT" 39 "ABORTING_SOURCE_AND_TARGET_LANES_MERGED" 40 "ABORTING_SNOOZED" 41 "UNAVAILABLE_BLINKER_LATCHED" 42 "UNAVAILABLE_AUTOPILOT_ABORTING" 43 "ABORTING_DESTINATION_LANE_UNSTABLE" 63 "UNKNOWN" ;
VAL_ 583 DAS_forkState 0 "INVALID" 1 "UNAVAILABLE_DISABLED" 2 "UNAVAILABLE_AP_INACTIVE" 3 "UNAVAILABLE_CONSTRUCTION" 4 "UNAVAILABLE_CONTROLLED_ACCESS_TOO_FAR" 5 "UNAVAILABLE_DON_INACTIVE" 6 "UNAVAILABLE_TOLL_BOOTH" 7 "UNAVAILABLE_OTHER" 8 "IDLE_BOTH_FORKS_AVAILABLE" 9 "IDLE_LEFT_FORK_AVAILABLE" 10 "IDLE_RIGHT_FORK_AVAILABLE" 11 "IDLE_NO_FORKS_AVAILABLE" 12 "ACTIVE_LEFT_NAV" 13 "ACTIVE_LEFT_USER" 14 "ACTIVE_RIGHT_NAV" 15 "ACTIVE_RIGHT_USER" 16 "FORK_COMPLETE" 17 "ABORT_CONTROL_INACTIVE" 18 "ABORT_BLINKER_CHANGE" 19 "ABORT_NOT_LEFT_LANE" 20 "ABORT_NOT_RIGHT_LANE" 21 "ABORT_DISALLOW" 22 "ABORT_OTHER" 23 "UNAVAILABLE_TIGHT_TURN_RADIUS" 24 "UNAVAILABLE_WEATHER" 25 "PRE_ACTIVE_LEFT_NAV" 26 "PRE_ACTIVE_RIGHT_NAV" 27 "UNAVAILABLE_INTERSECTION_ACTIVE" ;
VAL_ 583 DAS_rqstedBehaviorStatus 0 "VALID" 1 "NO_SRC_POLYLANE" 2 "NO_DEST_POLYLANE" 3 "MAP_NOT_INITIALIZED" 4 "NO_SOURCE_LANE_ON_MAP" 5 "NO_TARGET_LANE_ON_MAP" 6 "BUILD_ARGUMENT_FAIL" 7 "BLOCKED_BY_ULTRASOUND_L" 8 "BLOCKED_BY_BLINDSPOT_CAMERA_L" 9 "BLOCKED_BY_BLINDSPOT_CAMERA_INVALID_L" 10 "BLOCKED_BY_ULTRASOUND_AND_CAMERA_L" 11 "BLOCKED_BY_LANE_TYPE_L" 12 "BLOCKED_BY_ULTRASOUND_R" 13 "BLOCKED_BY_BLINDSPOT_CAMERA_R" 14 "BLOCKED_BY_BLINDSPOT_CAMERA_INVALID_R" 15 "BLOCKED_BY_ULTRASOUND_AND_CAMERA_R" 16 "BLOCKED_BY_LANE_TYPE_R" 17 "ROAD_NOT_APPROPRIATE" 18 "OUT_OF_DATE" 19 "BAD_ORIGIN_UPDATE" 20 "BLOCKED_BY_SLOW_TARGET_L" 21 "BLOCKED_BY_SLOW_TARGET_R" 22 "INVALID_PLAN" ;
VAL_ 583 DAS_autopilotAbortReason 0 "NONE" 1 "WATCHDOG_HEALTH" 2 "DI_MIA" 3 "ESP_MIA" 4 "EPAS_MIA" 5 "GTW_MIA" 6 "SCCM_MIA" 7 "RADAR_MIA" 8 "VCFRONT_MIA" 9 "VCRIGHT_MIA" 10 "CRUISE_FAULT" 11 "CRUISE_NOT_ACTIVE" 12 "USER_DISABLED" 13 "TRAILER_MODE_ACTIVE" 14 "VEHICLE_SPEED_ABOVE_MAX" 15 "EPAS_EAC_NOT_ACTIVE" 16 "EPAS_EAC_ERROR" 17 "CAMERA_FAILSAFES" 18 "CAMERA_CALIBRATION" 19 "RADAR_BLIND" 20 "RADAR_FAULT" 21 "ACC_CANCEL_GENERIC" 22 "ACC_CANCEL_SILENT" 23 "ACC_FAULT" 24 "ROAD_ESTIMATOR_HEALTH" 25 "CONTROLLER_REFERENCE" 26 "CONTROLLER_SOLVER" 27 "CONTROLLER_NOT_ALLOWED" 28 "THERMAL_ISSUE" 29 "MAP_HEALTH" 30 "CONTROLLER_STALE_REFERENCE" 31 "CONTROLLER_STALE_LOCALIZATION" 32 "CONTROLLER_BAD_REF_UPDATE" 33 "AEB" 34 "CONTROLLER_REF_TOO_SHORT" 35 "MISSION_PLANNER_NO_VISION_LANES_FOUND" 36 "GORE_INCURSION" 37 "REACHED_END_OF_NAV_STOP" 38 "STEERING_SATURATED_LANE_DEPARTURE" 39 "EPAS_STEERING_ANGLE_INVALID" 40 "W048_FEATURES_DISABLED" 41 "INVALID_DI_PEDAL_POS" 42 "INVALID_VEHICLE_SPEED" 43 "PERCEPTION_HEALTH_VISION" 44 "SEATBELT_UNBUCKLED" 45 "USER_OVERRIDE_STRIKEOUT" 46 "INTEGRATOR_HEALTH_CRITICAL" 47 "IBOOSTER_MIA" 48 "HEADLIGHT_OFF_AT_NIGHT" 49 "ONCOMING_LANE" 50 "INVALID_BEHAVIOR" 51 "CITY_STREETS_REF_TOO_SHORT" 52 "EXTENDED_COMPUTE_INACTIVE" 53 "PERCEPTION_HEALTH_POST_PROCESSING" 54 "PERCEPTION_HEALTH_STALE" 55 "DRIVER_NOT_PRESENT" 56 "AHB_MANUAL_OVERRIDE" 57 "CABIN_CAM_BLIND" 58 "EXTENDED_COMPUTE_INACTIVE_OTHER_SOC_HEALTH_UNKNOWN" 59 "EXTENDED_COMPUTE_INACTIVE_OTHER_SOC_HEALTH_CRITICAL" 60 "EXTENDED_COMPUTE_INACTIVE_ETHERNET_LINK_HEALTH" 61 "EXTENDED_COMPUTE_INACTIVE_PCIE_LINK_HEALTH" 255 "REASON_MAX" ;
VAL_ 583 DAS_controllerHealth 0 "HEALTHY" 1 "DEGRADED" 2 "CRITICAL" 3 "SOLVER_FAILURE" ;
VAL_ 583 DAS_behaviorReport 1 "VIEW_RANGE" 2 "CURVE_SPEED_ADAPTATION" 3 "RADAR_ONLY_BRAKING" 4 "KEEP_CALM" 5 "FLEET_SPEEDS" 6 "TRAFFIC_CONTROL_STOPPED_STATE" 7 "UNDERTAKE_ASSIST_KEEP_CALM" 8 "IN_LANE_VEHICLE" 9 "TARGET_LANE_VEHICLE" 10 "UNDERTAKE_VEHICLE" 11 "TRAFFIC_CONTROL" 12 "VISION_LANE_GEOMETRY" 13 "MAP_LANE_GEOMETRY" 14 "DRIVABLE_SPACE_VIOLATION" 15 "SLOWING_FOR_TARGET_LANE" 16 "VISION_SPEEDS" 17 "NAV_FLEET_SPEEDS" 18 "NAV_PATH_CSA" 19 "MERGE_VEHICLE_LEFT" 20 "MERGE_VEHICLE_RIGHT" 21 "CUTIN_VEHICLE_LEFT" 22 "CUTIN_VEHICLE_RIGHT" 23 "MP_AP_RESTRICTION" 24 "MP_NOT_BUCKLED" 25 "MP_DRIVER_MONITOR" 26 "MP_AP_STATE_MACHINE" 27 "MP_DI_CRUISE" 28 "MP_ULC" 29 "MP_AP_INACTIVE" 30 "ACTIVE_SAFETY_SLOWDOWN" 31 "STEERING_SATURATED" 32 "END_OF_NAV_ROUTE" 33 "LANE_SPEED_DIFF" 34 "STATIC_OBJECT" 35 "CUTIN_VEHICLE" 36 "STATIC_OBJECT_MERGE_LEFT" 37 "STATIC_OBJECT_MERGE_RIGHT" 38 "RISK_MANAGER" 39 "RELEVANT_VRU" 40 "CROSSWALK" 41 "CROSS_TRAFFIC_AVOIDANCE" 42 "TOLLBOOTH" 43 "ROUNDABOUT" 44 "SUGGESTED_VISION_SPEED" 45 "SPEED_BUMP" 46 "NARROW_CORRIDOR" 47 "TRAFFIC_CONTROL_LAUNCH" 48 "ONRAMP_BOOST" 49 "VANISHING_CIPV_KEEP_CALM" 50 "DYNAMIC_PINCH_POINT" 51 "APPROACHING_TURN" 52 "CLEAR_TO_GO" 53 "CROSSING_OBJECT" 54 "UNSUPPORTED_MANEUVER" 55 "PATH_BLOCKED" 56 "PATH_BLOCKED_BEYOND_TRAJ" 57 "REFERENCE_LENGTH" 58 "TRAJECTORY_OUTLIER_PRESSURE" 59 "CITY_MERGE_OBJECT" 60 "MAIN_CAMERA_SUN_GLARE" 61 "POOR_VISIBILITY" 62 "FORWARD_LATERAL_OBJECT" 63 "AHB_MANUAL_OVERRIDE" 64 "FAILED_LANE_CHANGE" 65 "CREEP_FOR_SHORT_REF" 66 "DRY_STEERING" 67 "CAUTION_LIGHTS" 68 "CAMERA_FAILSAFES" 69 "ROAD_SPEED" 70 "STOPPING_FOR_GEAR_CHANGE" 71 "MAX_SPEED_IN_REVERSE" ;
VAL_ 583 DAS_alcInternalState 0 "DISABLED" 1 "IDLE" 2 "ABORTING" 3 "BEHAVIOR_CHECK" 4 "PRE_ACTIVE_LEFT" 5 "PRE_ACTIVE_RIGHT" 6 "ACTIVE_LEFT" 7 "ACTIVE_RIGHT" 8 "ACTIVE_ACC_LEFT" 9 "ACTIVE_ACC_RIGHT" 10 "SOFT_ABORTING_LEFT" 11 "SOFT_ABORTING_RIGHT" 12 "RETRY" ;
VAL_ 583 DAS_controllerRef 0 "HEALTHY" 1 "UNHEALTHY" 2 "STALE_REFERENCE" 3 "STALE_LOCALIZATION" 4 "BAD_REF_UPDATE" 5 "REF_TOO_SHORT" 6 "INDETERMINATE" ;
VAL_ 583 DAS_mapAvailability 0 "NOT_AVAILABLE" 1 "AVAILABLE" ;
VAL_ 583 DAS_arbiterBehavior 0 "INVALID" 1 "IN_LANE" 2 "LANE_CHANGE_LEFT" 3 "LANE_CHANGE_RIGHT" 4 "CITY_STREETS" ;
VAL_ 583 DAS_roadEstimator 0 "HEALTHY" 1 "UNSTABLE_MEASUREMENTS" 2 "DEGRADED" 3 "CRITICAL" ;
VAL_ 585 SCCM_turnIndicatorStalkStatus 0 "IDLE" 2 "UP_1" 4 "UP_2" 7 "DOWN_1" 8 "DOWN_2" 5 "SNA" ;
VAL_ 585 SCCM_washWipeButtonStatus 0 "NOT_PRESSED" 1 "1ST_DETENT" 2 "2ND_DETENT" 3 "SNA" ;
VAL_ 585 SCCM_highBeamStalkStatus 0 "IDLE" 1 "PULL" 2 "PUSH" 3 "SNA" ;
VAL_ 586 DAS_rearLeftVehDetectedTrip 0 "NOT_DETECTED" 1 "DETECTED" ;
VAL_ 586 DAS_rearRightVehDetectedTrip 0 "NOT_DETECTED" 1 "DETECTED" ;
VAL_ 586 DAS_rearLeftVehDetectedCurrent 0 "NOT_DETECTED" 1 "DETECTED" ;
VAL_ 586 DAS_rearVehDetectedThisCycle 0 "NOT_DETECTED" 1 "DETECTED" ;
VAL_ 586 DAS_ulcType 0 "NONE" 1 "NAV" 2 "SPEED" ;
VAL_ 586 DAS_behaviorType 0 "INVALID" 1 "IN_LANE" 2 "LANE_CHANGE_LEFT" 3 "LANE_CHANGE_RIGHT" ;
VAL_ 586 DAS_ulcInProgress 0 "INACTIVE" 1 "ACTIVE" ;
VAL_ 586 DAS_accSmartSpeedState 0 "NOT_ACTIVE" 1 "ACTIVE_OFFRAMP" 2 "ACTIVE_INTEGRATING" 3 "ACTIVE_ONRAMP" 4 "SET_SPEED_SET_REQUESTED" 5 "OFFRAMP_DELAY" 7 "SNA" ;
VAL_ 586 DAS_navAvailable 0 "UNAVAILABLE" 1 "AVAILABLE" ;
VAL_ 586 DAS_lastAutosteerAbortReason 0 "HM_LANE_VIEW_RANGE" 1 "HM_VIRTUAL_LANE_NO_INPUTS" 2 "HM_STEERING_ERROR" 14 "APP_ME_STATE_NOT_VISION" 15 "ME_MAIN_STATE_NOT_VISION" 16 "CAM_MSG_MIA" 17 "CAM_WATCHDOG" 18 "TRAILER_MODE" 19 "SIDE_COLLISION_IMMINENT" 20 "EPAS_EAC_DENIED" 21 "COMPONENT_MIA" 22 "CRUISE_FAULT" 23 "CID_SWITCH_DISABLED" 24 "DRIVING_OFF_NAV" 25 "VEHICLE_SPEED_ABOVE_MAX" 26 "FOLLOWER_OUTPUT_INVALID" 27 "PLANNER_OUTPUT_INVALID" 28 "EPAS_ERROR_CODE" 29 "ACC_CANCEL" 30 "CAMERA_FAILSAFES" 31 "NO_ABORT" 32 "AEB" 33 "SEATBELT_UNBUCKLED" 34 "USER_OVERRIDE_STRIKEOUT" 35 "DRIVER_NOT_PRESENT" 36 "AHB_MANUAL_OVERRIDE" ;
VAL_ 586 DAS_plannerState 0 "DISABLED" 1 "VL" 2 "FOLLOW" 3 "LANECHANGE_REQUESTED" 4 "LANECHANGE_IN_PROGRESS" 5 "LANECHANGE_WAIT_FOR_SIDE_OBSTACLE" 6 "LANECHANGE_WAIT_FOR_FWD_OBSTACLE" 7 "LANECHANGE_ABORT" ;
VAL_ 586 DAS_lastLinePreferenceReason 0 "OTHER_LANE_DISAGREES_WITH_MODEL" 1 "AGREEMENT_WITH_NEIGHBOR_LANES" 2 "NEIGHBOR_LANE_PROBABILIY" 3 "NAVIGATION_BRANCH" 4 "AVOID_ONCOMING_LANES" 5 "COUNTRY_DRIVING_SIDE" 15 "NONE" ;
VAL_ 586 DAS_autosteerHealthState 0 "UNAVAILABLE" 1 "NOMINAL" 2 "DEGRADED" 3 "SEVERELY_DEGRADED" 4 "ABORTING" 5 "FAULT" ;
VAL_ 586 DAS_roadSurfaceType 0 "SNA" 1 "NORMAL" 2 "ENHANCED" ;
VAL_ 586 DAS_offsetSide 0 "NO_OFFSET" 1 "OFFSET_RIGHT_OBJECT" 2 "OFFSET_LEFT_OBJECT" 3 "OFFSET_BOTH_OBJECTS" ;
VAL_ 586 DAS_autosteerBottsDotsUsage 0 "REJECTED_UNAVAILABLE" 1 "AVAILABLE" 2 "FUSED" 3 "BLACKLISTED" ;
VAL_ 586 DAS_autosteerModelUsage 0 "REJECTED_UNAVAILABLE" 1 "AVAILABLE" 2 "FUSED" 3 "BLACKLISTED" ;
VAL_ 586 DAS_autosteerNavigationUsage 0 "REJECTED_UNAVAILABLE" 1 "AVAILABLE" 2 "FUSED" 3 "BLACKLISTED" ;
VAL_ 586 DAS_autosteerHPPUsage 0 "REJECTED_UNAVAILABLE" 1 "AVAILABLE" 2 "FUSED" 3 "BLACKLISTED" ;
VAL_ 586 DAS_autosteerVehiclesUsage 0 "REJECTED_UNAVAILABLE" 1 "AVAILABLE" 2 "FUSED" 3 "BLACKLISTED" ;
VAL_ 599 DI_opdVehicleModelSpeedRef 4095 "SNA" ;
VAL_ 599 DI_uiSpeedUnits 0 "MPH" 1 "KPH" ;
VAL_ 599 DI_uiSpeed 255 "SNA" ;
VAL_ 601 APP_sentryState 0 "OFF" 1 "IDLE" 2 "ARMED" 3 "AWARE" 4 "PANIC" 5 "QUIET" 6 "SNA" ;
VAL_ 601 APP_fsdRevokeStrikeoutCount 7 "SNA" ;
VAL_ 601 APP_fsdSuspendState 0 "NOT_SUSPENDED" 1 "SUSPENDED" 3 "SNA" ;
VAL_ 601 APP_summonUnavailableReason 0 "UNKNOWN" 1 "NONE" 2 "NOT_IN_PARK" 3 "CAMERA_STREAM" 4 "CAMERA_BLOCKED" 5 "ULTRASONIC_BLOCKED" 6 "ULTRASONIC_FAULT" 7 "CRUISE_UNAVAILABLE" 8 "EAC_UNAVAILABLE" 9 "PUBLIC_ROAD" 10 "POOR_CONNECTION" 11 "PHONE_GPS_UNAVAILABLE" 12 "EGO_GPS_UNAVAILABLE" 13 "PHONE_IS_TOO_FAR" 14 "END_OF_LEASH" 15 "CAMERA_NOT_CALIBRATED" 16 "VISION_HEALTH_CRITICAL" 17 "ULTRASONIC_STALE" 18 "ALL_SENSORS_OCCLUDED" 19 "PUBLIC_ROAD_BOUNDARIES_NOT_VALID" 20 "NO_CONTEXT" ;
VAL_ 601 APP_clipRecordingStatus 0 "NO_DRIVE" 1 "IDLE" 2 "RECORDING" 3 "TRIGGERED" 4 "FAULTED" ;
VAL_ 601 APP_factorySummonStatus 0 "SNA" 1 "ACTIVE" 2 "AVAILABLE" 3 "UNAVAILABLE_NO_QR_INSTRUCTION" 4 "UNAVAILABLE_GOAL_TOO_FAR" 5 "UNAVAILABLE_NO_GPS" 6 "UNAVAILABLE_VEHICLE_SPEED_INVALID" 7 "UNAVAILABLE_HEADING_NOT_INITIALIZED" 8 "END_OF_ROUTE" ;
VAL_ 601 APP_fusedState 0 "UNKNOWN" 1 "UNFUSED" 2 "FUSED" 3 "SNA" ;
VAL_ 601 APP_watchdogState 0 "UNKNOWN" 1 "DEGRADED" 2 "CRITICAL" 3 "HEALTHY" 7 "SNA" ;
VAL_ 602 VCSEC_TPMSDisplayHardWarningIndicationRR 0 "NOT_INDICATED" 1 "INDICATED" ;
VAL_ 602 VCSEC_TPMSDisplayHardWarningIndicationRL 0 "NOT_INDICATED" 1 "INDICATED" ;
VAL_ 602 VCSEC_TPMSDisplayHardWarningIndicationFR 0 "NOT_INDICATED" 1 "INDICATED" ;
VAL_ 602 VCSEC_TPMSDisplayHardWarningIndicationFL 0 "NOT_INDICATED" 1 "INDICATED" ;
VAL_ 602 VCSEC_TPMSDisplaySoftWarningIndicationRR 0 "NOT_INDICATED" 1 "INDICATED" ;
VAL_ 602 VCSEC_TPMSDisplaySoftWarningIndicationRL 0 "NOT_INDICATED" 1 "INDICATED" ;
VAL_ 602 VCSEC_TPMSDisplaySoftWarningIndicationFR 0 "NOT_INDICATED" 1 "INDICATED" ;
VAL_ 602 VCSEC_TPMSDisplaySoftWarningIndicationFL 0 "NOT_INDICATED" 1 "INDICATED" ;
VAL_ 602 VCSEC_TPMSTellTale 0 "OFF" 1 "SOLID" 2 "FLASHING" ;
VAL_ 602 VCSEC_TPMSDisplayPressureRR 255 "SNA" ;
VAL_ 602 VCSEC_TPMSDisplayPressureRL 255 "SNA" ;
VAL_ 602 VCSEC_TPMSDisplayPressureFR 255 "SNA" ;
VAL_ 602 VCSEC_TPMSDisplayPressureFL 255 "SNA" ;
VAL_ 637 APS_eacAllow 0 "INHIBIT" 1 "ALLOW" 2 "RESERVED" 3 "SNA" ;
VAL_ 644 UI_closureEasterEggStatus 0 "IDLE" 1 "REQ_RECD_WAITING_STANDARD" 2 "REQ_RECD_WAITING_DYNAMIC" 3 "PLAYING" ;
VAL_ 644 UI_serviceModePlus 0 "DISABLED" 1 "ENABLED" ;
VAL_ 644 UI_diagnosticsAllowed 0 "NOT_ALLOWED" 1 "ALLOWED" ;
VAL_ 644 UI_serviceMode 0 "DISABLED" 1 "ENABLED" ;
VAL_ 644 UI_showroomMode 0 "DISABLED" 1 "ENABLED" ;
VAL_ 644 UI_transportMode 0 "DISABLED" 1 "ENABLED" ;
VAL_ 644 UI_factoryMode 0 "DISABLED" 1 "ENABLED" ;
VAL_ 659 UI_selfParkTune 15 "SNA" ;
VAL_ 659 UI_redLightStopSignEnable 0 "RLSSW_OFF" 1 "RLSSW_ON" 3 "SNA" ;
VAL_ 659 UI_pedalMap_epas 0 "CHILL" 1 "SPORT" 2 "PERFORMANCE" ;
VAL_ 659 UI_pedalSafetyEnable 0 "PEDAL_SAFETY_OFF" 1 "PEDAL_SAFETY_ON" 3 "SNA" ;
VAL_ 659 UI_ldwEnable 0 "NO_HAPTIC" 1 "LDW_TRIGGERS_HAPTIC" 3 "SNA" ;
VAL_ 659 UI_latControlEnable 0 "OFF" 1 "ON" 2 "UNAVAILABLE" 3 "SNA" ;
VAL_ 659 UI_fcwSensitivity 0 "AEB_SENSITIVITY_EARLY" 1 "AEB_SENSITIVITY_AVERAGE" 2 "AEB_SENSITIVITY_LATE" 3 "SNA" ;
VAL_ 659 UI_fcwEnable 0 "FCW_OFF" 1 "FCW_ON" 3 "SNA" ;
VAL_ 659 UI_bsdEnable 0 "BSD_OFF" 1 "BSD_ON" 3 "SNA" ;
VAL_ 659 UI_autoParkRequest 0 "NONE" 1 "PARK_LEFT_PARALLEL" 2 "PARK_LEFT_CROSS" 3 "PARK_RIGHT_PARALLEL" 4 "PARK_RIGHT_CROSS" 5 "PARALLEL_PULL_OUT_TO_LEFT" 6 "PARALLEL_PULL_OUT_TO_RIGHT" 7 "ABORT" 8 "COMPLETE" 9 "SEARCH" 10 "PAUSE" 11 "RESUME" 12 "BEGIN_PARKING" 15 "SNA" ;
VAL_ 659 UI_autoLaneChangeEnable 0 "OFF" 1 "ON" 3 "SNA" ;
VAL_ 659 UI_ahlbEnable 0 "AHLB_OFF" 1 "AHLB_ON" 3 "SNA" ;
VAL_ 659 UI_aesEnable 0 "AES_OFF" 1 "AES_ON" 3 "SNA" ;
VAL_ 659 UI_aebEnable 0 "AEB_OFF" 1 "AEB_ON" 3 "SNA" ;
VAL_ 659 UI_accOvertakeEnable 0 "ACC_OVERTAKE_OFF" 1 "ACC_OVERTAKE_ON" 3 "SNA" ;
VAL_ 659 UI_distanceUnits 0 "KM" 1 "MILES" ;
VAL_ 659 UI_trailerMode 0 "OFF" 1 "ON" ;
VAL_ 659 UI_zeroSpeedConfirmed 0 "CANCELED" 1 "CONFIRMED" 2 "UNUSED" 3 "SNA" ;
VAL_ 659 UI_winchModeRequest 0 "IDLE" 1 "ENTER" 2 "EXIT" ;
VAL_ 659 UI_parkBrakeRequest 0 "IDLE" 1 "PRESSED" 3 "SNA" ;
VAL_ 659 UI_tractionControlMode 0 "NORMAL_SELECTED" 1 "SLIP_START_SELECTED" 2 "DEV_MODE_1_SELECTED" 3 "DEV_MODE_2_SELECTED" 4 "ROLLS_MODE_SELECTED" 5 "DYNO_MODE_SELECTED" 6 "OFFROAD_ASSIST_SELECTED" ;
VAL_ 659 UI_steeringTuneRequest 0 "COMFORT" 1 "STANDARD" 2 "SPORT" ;
VAL_ 680 EPBL_brakeDiscWipeRequest 0 "NONE" 1 "LIGHT" 2 "STRONG" 3 "SNA" ;
VAL_ 680 EPBL_cdpRequest 0 "NOT_REQUESTED" 1 "REQUESTED" ;
VAL_ 680 EPBL_telltale 0 "LAMP_OFF" 1 "LAMP_RED_ON" 2 "LAMP_AMBER_ON" 3 "LAMP_RED_FLASH" 7 "SNA" ;
VAL_ 680 EPBL_freeRollModeStatus 0 "UNAVAILABLE" 1 "AVAILABLE" 2 "ENABLED" ;
VAL_ 680 EPBL_systemStatus 0 "UNKNOWN" 1 "RELEASED" 2 "PARKED" 3 "DYNAMIC" 4 "PARKING" 5 "RELEASING" 6 "FAULT" 7 "FAULT_SECURE" 8 "MISMATCH" ;
VAL_ 697 DAS_accelMax 511 "SNA" ;
VAL_ 697 DAS_accelMin 511 "SNA" ;
VAL_ 697 DAS_jerkMax 255 "SNA" ;
VAL_ 697 DAS_jerkMin 511 "SNA" ;
VAL_ 697 DAS_aebEvent 0 "NOT_ACTIVE" 1 "ACTIVE" 2 "FAULT" 3 "SNA" ;
VAL_ 697 DAS_accState 0 "ACC_CANCEL_GENERIC" 1 "ACC_BACKWARD" 3 "ACC_HOLD" 4 "ACC_ON" 5 "APC_BACKWARD" 6 "APC_FORWARD" 7 "APC_COMPLETE" 8 "APC_ABORT" 9 "APC_PAUSE" 10 "APC_UNPARK_COMPLETE" 11 "APC_SELFPARK_START" 13 "ACC_CANCEL_GENERIC_SILENT" 15 "FAULT_SNA" ;
VAL_ 697 DAS_setSpeed 4095 "SNA" ;
VAL_ 723 UI_screenPCBTemperature 2047 "GTW_I2C_TEMP_SNA" ;
VAL_ 723 UI_solarElevationAngle 127 "SNA" ;
VAL_ 723 UI_isSunUp 0 "DOWN" 1 "UP" 3 "SNA" ;
VAL_ 723 UI_solarAzimuthAngleCarRef 255 "SNA" ;
VAL_ 723 UI_solarAzimuthAngle 4294934528 "SNA" ;
VAL_ 737 VCFRONT_homelinkCommStatus 0 "SNA" 1 "OFF" 2 "ON" 3 "FAULT" ;
VAL_ 737 VCFRONT_pressureRefrigDischarge 255 "SNA" ;
VAL_ 737 VCFRONT_pressureRefrigSuction 127 "SNA" ;
VAL_ 737 VCFRONT_AS8510Voltage 4095 "SNA" ;
VAL_ 737 VCFRONT_airCompressorStatus 0 "OFF" 1 "ON" 2 "TURNING_OFF" 3 "TURNING_ON" 4 "FAULT" 5 "RETRY_AVAILABLE" 7 "SNA" ;
VAL_ 737 VCFRONT_crashState 0 "IDLE" 1 "MINOR" 2 "SEVERE" ;
VAL_ 737 VCFRONT_crashDetectedType 0 "NONE" 1 "MINOR" 2 "SEVERE" ;
VAL_ 737 VCFRONT_wiperState 0 "SNA" 1 "SERVICE" 2 "FAULT" 3 "DELAYED_REST" 4 "PARK" 5 "WASH" 6 "MOMENTARY_WIPE" 7 "INTERMITTENT_HIGH" 8 "INTERMITTENT_LOW" 9 "CONT_FAST" 10 "CONT_SLOW" 11 "INT_AUTO_LOW" 12 "INT_AUTO_HIGH" ;
VAL_ 737 VCFRONT_batterySMState 0 "INIT" 1 "CHARGE" 2 "DISCHARGE" 3 "STANDBY" 4 "RESISTANCE_ESTIMATION" 5 "OTA_STANDBY" 6 "DISCONNECTED_BATTERY_TEST" 7 "FAULT" ;
VAL_ 737 VCFRONT_wiperPosition 0 "SNA" 1 "SERVICE" 2 "DEPRESSED_PARK" 3 "DELAYED_REST" 4 "WIPING" ;
VAL_ 737 VCFRONT_wiperSpeed 0 "SNA" 1 "OFF" 2 "1" 3 "2" 4 "3" 5 "4" 6 "5" 7 "LOW" 8 "HIGH" ;
VAL_ 737 VCFRONT_vehicleStatusDBG 0 "INIT" 1 "LOW_POWER_STANDBY" 2 "SILENT_WAKE" 3 "BATTERY_POST_WAKE" 4 "SYSTEM_CHECKS" 5 "SLEEP_SHUTDOWN" 6 "SLEEP_STANDBY" 7 "LV_SHUTDOWN" 8 "LV_AWAKE" 9 "HV_UP_STANDBY" 10 "ACCESSORY" 11 "ACCESSORY_PLUS" 12 "CONDITIONING" 13 "DRIVE" 14 "CRASH" 15 "OTA" 16 "TURN_ON_RAILS" 17 "RESET" ;
VAL_ 737 VCFRONT_iBoosterStateDBG 0 "OFF" 1 "ON" 2 "GOING_DOWN" 3 "WRITING_DATA_SHUTDOWN" 4 "FORCE_OFF" ;
VAL_ 737 VCFRONT_frunkLatchStatus 0 "SNA" 1 "OPENED" 2 "CLOSED" 3 "CLOSING" 4 "OPENING" 5 "AJAR" 6 "TIMEOUT" 7 "DEFAULT" 8 "FAULT" ;
VAL_ 737 VCFRONT_statusIndex 0 "BODY_CONTROLS" 1 "VEHICLE_AND_RAILS" 2 "HOMELINK" 3 "REFRIGERANT_SYSTEM" 4 "LV_BATTERY_DEBUG" 5 "INVALID" ;
VAL_ 744 EPBR_brakeDiscWipeRequest 0 "NONE" 1 "LIGHT" 2 "STRONG" 3 "SNA" ;
VAL_ 744 EPBR_cdpRequest 0 "NOT_REQUESTED" 1 "REQUESTED" ;
VAL_ 744 EPBR_telltale 0 "LAMP_OFF" 1 "LAMP_RED_ON" 2 "LAMP_AMBER_ON" 3 "LAMP_RED_FLASH" 7 "SNA" ;
VAL_ 744 EPBR_freeRollModeStatus 0 "UNAVAILABLE" 1 "AVAILABLE" 2 "ENABLED" ;
VAL_ 744 EPBR_systemStatus 0 "UNKNOWN" 1 "RELEASED" 2 "PARKED" 3 "DYNAMIC" 4 "PARKING" 5 "RELEASING" 6 "FAULT" 7 "FAULT_SECURE" 8 "MISMATCH" ;
VAL_ 755 UI_hvacReqSecondRowState 0 "AUTO" 1 "OFF" 2 "LOW" 3 "MED" 4 "HIGH" ;
VAL_ 755 UI_hvacReqUserPowerState 0 "OFF" 1 "ON" 2 "PRECONDITION" 3 "OVERHEAT_PROTECT_FANONLY" 4 "OVERHEAT_PROTECT" ;
VAL_ 755 UI_hvacReqManualDefogState 0 "NONE" 1 "DEFOG" 2 "DEFROST" ;
VAL_ 755 UI_hvacReqACDisable 0 "AUTO" 1 "OFF" 2 "ON" ;
VAL_ 755 UI_hvacReqRecirc 0 "AUTO" 1 "RECIRC" 2 "FRESH" ;
VAL_ 755 UI_hvacReqBlowerSegment 0 "OFF" 1 "1" 2 "2" 3 "3" 4 "4" 5 "5" 6 "6" 7 "7" 8 "8" 9 "9" 10 "10" 11 "AUTO" ;
VAL_ 755 UI_hvacReqAirDistributionMode 0 "AUTO" 1 "MANUAL_FLOOR" 2 "MANUAL_PANEL" 3 "MANUAL_PANEL_FLOOR" 4 "MANUAL_DEFROST" 5 "MANUAL_DEFROST_FLOOR" 6 "MANUAL_DEFROST_PANEL" 7 "MANUAL_DEFROST_PANEL_FLOOR" ;
VAL_ 755 UI_hvacReqTempSetpointRight 0 "LO" 26 "HI" ;
VAL_ 755 UI_hvacReqTempSetpointLeft 0 "LO" 26 "HI" ;
VAL_ 760 UI_conditionalSpeedLimit 31 "SNA" ;
VAL_ 760 UI_userSpeedOffsetUnits 0 "MPH" 1 "KPH" ;
VAL_ 760 UI_mapSpeedLimitUnits 0 "MPH" 1 "KPH" ;
VAL_ 771 OCS1P_occupantClassificationQF 0 "FAULTED" 1 "NOT_FAULTED" ;
VAL_ 771 OCS1P_occupantClassification 0 "EMPTY" 1 "INHIBIT" 2 "SMALL" 3 "LARGE" 4 "INIT" 5 "NOT_CONFIGURED" 7 "SNA" ;
VAL_ 777 DAS_leadVeh2Id 0 "SNA" ;
VAL_ 777 DAS_leftVeh2Id 0 "SNA" ;
VAL_ 777 DAS_rightVeh2Id 0 "SNA" ;
VAL_ 777 DAS_cutinVehHeading 255 "SNA" ;
VAL_ 777 DAS_rightVeh2Heading 255 "SNA" ;
VAL_ 777 DAS_leadVeh2VxRel 15 "SNA" ;
VAL_ 777 DAS_leftVeh2VxRel 15 "SNA" ;
VAL_ 777 DAS_rightVeh2VxRel 15 "SNA" ;
VAL_ 777 DAS_rightVehHeading 255 "SNA" ;
VAL_ 777 DAS_leadVeh2Dx 255 "SNA" ;
VAL_ 777 DAS_leftVeh2Dx 255 "SNA" ;
VAL_ 777 DAS_rightVeh2Dx 255 "SNA" ;
VAL_ 777 DAS_leadVeh2Type 0 "UNKNOWN" 1 "TRUCK" 2 "CAR" 3 "MOTORCYCLE" 4 "BICYCLE" 5 "PEDESTRIAN" ;
VAL_ 777 DAS_leftVeh2Type 0 "UNKNOWN" 1 "TRUCK" 2 "CAR" 3 "MOTORCYCLE" 4 "BICYCLE" 5 "PEDESTRIAN" ;
VAL_ 777 DAS_rightVeh2Type 0 "UNKNOWN" 1 "TRUCK" 2 "CAR" 3 "MOTORCYCLE" 4 "BICYCLE" 5 "PEDESTRIAN" ;
VAL_ 777 DAS_leftVeh2Heading 255 "SNA" ;
VAL_ 777 DAS_roadSignOrientation 0 "UNKNOWN" 1 "VERTICAL_3_LIGHT" 2 "HORIZONTAL_3_LIGHT" ;
VAL_ 777 DAS_leadVehId 127 "SNA" ;
VAL_ 777 DAS_leftVehId 127 "SNA" ;
VAL_ 777 DAS_rightVehId 127 "SNA" ;
VAL_ 777 DAS_cutinVehId 127 "SNA" ;
VAL_ 777 DAS_roadSignArrow 0 "CIRCLE" 1 "LEFT" 2 "RIGHT" 3 "STRAIGHT" 4 "UNKNOWN" ;
VAL_ 777 DAS_roadSignSource 0 "NONE" 1 "NAV" 2 "VISION" ;
VAL_ 777 DAS_leftVehHeading 255 "SNA" ;
VAL_ 777 DAS_leadVehVxRel 15 "SNA" ;
VAL_ 777 DAS_leftVehVxRel 15 "SNA" ;
VAL_ 777 DAS_rightVehVxRel 15 "SNA" ;
VAL_ 777 DAS_cutinVehVxRel 15 "SNA" ;
VAL_ 777 DAS_leadVeh2Heading 255 "SNA" ;
VAL_ 777 DAS_roadSignStopLineDist 1023 "SNA" ;
VAL_ 777 DAS_leadVehDx 255 "SNA" ;
VAL_ 777 DAS_leftVehDx 255 "SNA" ;
VAL_ 777 DAS_rightVehDx 255 "SNA" ;
VAL_ 777 DAS_cutinVehDx 255 "SNA" ;
VAL_ 777 DAS_leadVehHeading 255 "SNA" ;
VAL_ 777 DAS_roadSignId 0 "STOP_SIGN" 1 "TRAFFIC_LIGHT" 255 "SNA" ;
VAL_ 777 DAS_leadVehType 0 "UNKNOWN" 1 "TRUCK" 2 "CAR" 3 "MOTORCYCLE" 4 "BICYCLE" 5 "PEDESTRIAN" 6 "IPSO" ;
VAL_ 777 DAS_leftVehType 0 "UNKNOWN" 1 "TRUCK" 2 "CAR" 3 "MOTORCYCLE" 4 "BICYCLE" 5 "PEDESTRIAN" ;
VAL_ 777 DAS_rightVehType 0 "UNKNOWN" 1 "TRUCK" 2 "CAR" 3 "MOTORCYCLE" 4 "BICYCLE" 5 "PEDESTRIAN" ;
VAL_ 777 DAS_cutinVehType 0 "UNKNOWN" 1 "TRUCK" 2 "CAR" 3 "MOTORCYCLE" 4 "BICYCLE" 5 "PEDESTRIAN" ;
VAL_ 777 DAS_roadSignColor 0 "NONE" 1 "RED" 2 "YELLOW" 3 "GREEN" 4 "RED_YELLOW" ;
VAL_ 777 DAS_objectId 0 "LEAD_VEHICLES" 1 "LEFT_VEHICLES" 2 "RIGHT_VEHICLES" 3 "CUTIN_VEHICLE" 4 "ROAD_SIGN" 5 "VEHICLE_HEADINGS" ;
VAL_ 785 EPAS3S_infoBuildType 0 "UNKNOWN_BUILD" 1 "PLATFORM_BUILD" 2 "LOCAL_BUILD" 3 "TRACEABLE_CI_BUILD" 4 "MFG_BUILD" ;
VAL_ 785 EPAS3S_infoIndex 0 "DEPRECATED_0" 1 "DEPRECATED_1" 2 "DEPRECATED_2" 3 "DEPRECATED_3" 4 "DEPRECATED_4" 5 "DEPRECATED_5" 6 "DEPRECATED_6" 7 "DEPRECATED_7" 8 "DEPRECATED_8" 9 "DEPRECATED_9" 10 "BUILD_HWID_COMPONENTID" 11 "PCBAID_ASSYID_USAGEID" 13 "APP_CRC" 14 "BOOTLOADER_SVN" 15 "BOOTLOADER_CRC" 16 "SUBCOMPONENT" 17 "APP_GITHASH" 18 "BOOTLOADER_GITHASH" 19 "VERSION_DEPRECATED" 20 "UDS_PROTOCOL_BOOTCRC" 22 "VARIANTCRC" 25 "PACKAGE_PN_1_7" 26 "PACKAGE_PN_8_14" 27 "PACKAGE_PN_15_20" 29 "PACKAGE_SN_1_7" 30 "PACKAGE_SN_8_14" 31 "SUBCOMPONENT_GITHASH" 255 "END" ;
VAL_ 789 OCS1P_infoBuildType 0 "UNKNOWN_BUILD" 1 "PLATFORM_BUILD" 2 "LOCAL_BUILD" 3 "TRACEABLE_CI_BUILD" 4 "MFG_BUILD" ;
VAL_ 789 OCS1P_infoIndex 10 "Mux10" 11 "Mux11" 13 "Mux13" 14 "Mux14" 17 "Mux17" 18 "Mux18" 19 "Mux19" 20 "Mux20" ;
VAL_ 801 VCFRONT_tempAmbientFiltered 0 "SNA" ;
VAL_ 801 VCFRONT_washerFluidLevel 0 "SNA" 1 "LOW" 2 "NORMAL" ;
VAL_ 801 VCFRONT_tempAmbient 0 "SNA" ;
VAL_ 801 VCFRONT_brakeFluidLevel 0 "SNA" 1 "LOW" 2 "NORMAL" ;
VAL_ 801 VCFRONT_coolantLevel 0 "NOT_OK" 1 "FILLED" ;
VAL_ 801 VCFRONT_tempCoolantPTInlet 2047 "SNA" ;
VAL_ 801 VCFRONT_tempCoolantBatInlet 1023 "SNA" ;
VAL_ 805 ESP_infoVehicleVariant 1 "01" 2 "02" 3 "03" 4 "04" 5 "05" 6 "06" 7 "07" 8 "08" 9 "09" ;
VAL_ 805 ESP_infoBuildType 0 "UNKNOWN_BUILD" 1 "PLATFORM_BUILD" 2 "LOCAL_BUILD" 3 "TRACEABLE_CI_BUILD" 4 "MFG_BUILD" ;
VAL_ 805 ESP_infoIndex 0 "DEPRECATED_0" 1 "DEPRECATED_1" 2 "DEPRECATED_2" 3 "DEPRECATED_3" 4 "DEPRECATED_4" 5 "DEPRECATED_5" 6 "DEPRECATED_6" 7 "DEPRECATED_7" 8 "DEPRECATED_8" 9 "DEPRECATED_9" 10 "BUILD_HWID_COMPONENTID" 11 "PCBAID_ASSYID_USAGEID" 13 "APP_CRC" 14 "BOOTLOADER_SVN" 15 "BOOTLOADER_CRC" 16 "SUBCOMPONENT" 17 "APP_GITHASH" 18 "BOOTLOADER_GITHASH" 19 "VERSION_DEPRECATED" 20 "UDS_PROTOCOL_BOOTCRC" 22 "VARIANTCRC" 25 "PACKAGE_PN_1_7" 26 "PACKAGE_PN_8_14" 27 "PACKAGE_PN_15_20" 29 "PACKAGE_SN_1_7" 30 "PACKAGE_SN_8_14" 31 "SUBCOMPONENT_GITHASH" 255 "END" ;
VAL_ 813 IBST_infoBuildType 0 "UNKNOWN_BUILD" 1 "PLATFORM_BUILD" 2 "LOCAL_BUILD" 3 "TRACEABLE_CI_BUILD" 4 "MFG_BUILD" ;
VAL_ 813 IBST_infoIndex 0 "DEPRECATED_0" 1 "DEPRECATED_1" 2 "DEPRECATED_2" 3 "DEPRECATED_3" 4 "DEPRECATED_4" 5 "DEPRECATED_5" 6 "DEPRECATED_6" 7 "DEPRECATED_7" 8 "DEPRECATED_8" 9 "DEPRECATED_9" 10 "BUILD_HWID_COMPONENTID" 11 "PCBAID_ASSYID_USAGEID" 13 "APP_CRC" 14 "BOOTLOADER_SVN" 15 "BOOTLOADER_CRC" 16 "SUBCOMPONENT" 17 "APP_GITHASH" 18 "BOOTLOADER_GITHASH" 19 "VERSION_DEPRECATED" 20 "UDS_PROTOCOL_BOOTCRC" 22 "VARIANTCRC" 25 "PACKAGE_PN_1_7" 26 "PACKAGE_PN_8_14" 27 "PACKAGE_PN_15_20" 29 "PACKAGE_SN_1_7" 30 "PACKAGE_SN_8_14" 31 "SUBCOMPONENT_GITHASH" 255 "END" ;
VAL_ 817 DAS_autopilotOverrideState 0 "BASE" 1 "SUBSCRIPTION" 2 "TRIAL" ;
VAL_ 817 DAS_autopilot 0 "NONE" 1 "HIGHWAY" 2 "ENHANCED" 3 "SELF_DRIVING" 4 "BASIC" ;
VAL_ 820 UI_speedLimit 511 "SNA" ;
VAL_ 820 UI_stoppingMode 0 "STANDARD" 1 "CREEP" 2 "HOLD" ;
VAL_ 820 UI_wasteModeRegenLimit 0 "MAX" 1 "30A" 2 "10A" 3 "0A" ;
VAL_ 820 UI_wasteMode 0 "NONE" 1 "PARTIAL" 2 "FULL" 3 "BURN_IN" ;
VAL_ 820 UI_motorOnMode 0 "NORMAL" 1 "FRONT_ONLY" 2 "REAR_ONLY" ;
VAL_ 820 UI_limitMode 0 "NORMAL" 1 "VALET" 2 "FACTORY" 3 "SERVICE" ;
VAL_ 820 UI_closureConfirmed 0 "NONE" 1 "FRUNK" 2 "PROX" 3 "FALCON" ;
VAL_ 820 UI_systemTorqueLimit 63 "SNA" ;
VAL_ 820 UI_pedalMap 0 "CHILL" 1 "SPORT" 2 "PERFORMANCE" ;
VAL_ 820 UI_systemPowerLimit 31 "SNA" ;
VAL_ 838 GTW_autopilotOverrideState 0 "BASE" 1 "SUBSCRIPTION" 2 "TRIAL" ;
VAL_ 840 GTW_sentryModeState 0 "OFF" 1 "IDLE" 2 "ARMED" 3 "AWARE" 4 "PANIC" 5 "QUIET" 6 "SNA" ;
VAL_ 840 GTW_hwtype 0 "SNA" 1 "MPC57" 2 "SPC58" ;
VAL_ 840 GTW_vehicleVersionMatchStatus 0 "NOT_CALCULATED_YET" 1 "MISMATCHED" 2 "MATCHED" ;
VAL_ 848 APS_w208_rackDetected 0 "UNKNOWN" 1 "NO_RACK" 2 "RACK_DETECTED" 3 "SNA" ;
VAL_ 849 RCM_infoBuildType 0 "UNKNOWN_BUILD" 1 "PLATFORM_BUILD" 2 "LOCAL_BUILD" 3 "TRACEABLE_CI_BUILD" 4 "MFG_BUILD" ;
VAL_ 849 RCM_infoIndex 0 "DEPRECATED_0" 1 "DEPRECATED_1" 2 "DEPRECATED_2" 3 "DEPRECATED_3" 4 "DEPRECATED_4" 5 "DEPRECATED_5" 6 "DEPRECATED_6" 7 "DEPRECATED_7" 8 "DEPRECATED_8" 9 "DEPRECATED_9" 10 "BUILD_HWID_COMPONENTID" 11 "PCBAID_ASSYID_USAGEID" 13 "APP_CRC" 14 "BOOTLOADER_SVN" 15 "BOOTLOADER_CRC" 16 "SUBCOMPONENT" 17 "APP_GITHASH" 18 "BOOTLOADER_GITHASH" 19 "VERSION_DEPRECATED" 20 "UDS_PROTOCOL_BOOTCRC" 22 "VARIANTCRC" 25 "PACKAGE_PN_1_7" 26 "PACKAGE_PN_8_14" 27 "PACKAGE_PN_15_20" 29 "PACKAGE_SN_1_7" 30 "PACKAGE_SN_8_14" 31 "SUBCOMPONENT_GITHASH" 255 "END" ;
VAL_ 851 UI_trailerModeTelltale 0 "OFF" 1 "BLUE" 2 "YELLOW" 3 "RED" ;
VAL_ 851 UI_cellSignalBars 0 "ZERO" 1 "ONE" 2 "TWO" 3 "THREE" 4 "FOUR" 5 "FIVE" 7 "SNA" ;
VAL_ 851 UI_cellNetworkTechnology 0 "NONE" 1 "GPRS" 2 "EDGE" 3 "UMTS" 4 "HSDPA" 5 "HSUPA" 6 "HSPA" 7 "LTE" 8 "GSM" 9 "CDMA" 10 "WCDMA" 15 "SNA" ;
VAL_ 851 UI_factoryReset 0 "NONE_SNA" 1 "DEVELOPER" 2 "DIAGNOSTIC" 3 "CUSTOMER" ;
VAL_ 851 UI_autopilotTrial 0 "NONE" 1 "START" 2 "STOP" 3 "ACTIVE" ;
